VERSION ""

NS_ :

BS_:

BU_:BMS FCS VCU
BO_ 2550595703 BatP7_BMS_ChargingInfo: 8 BMS
 SG_ P7_ChrgrCplrStat : 7|1@0+ (1,0) [0|1] "" VCU
 SG_ P7_HVBattChrgSysStatus : 6|4@0+ (1,0) [0|15] "" VCU
 SG_ P7_DCChrgCrntCmd : 2|9@0+ (1,0) [0|500] "A" VCU
 SG_ P7_CC2Vlt : 9|8@0+ (0.1,0) [0|25] "V" VCU
 SG_ P7_DCRcptPosTemp : 17|9@0+ (0.5,-40) [-40|150] "C" VCU
 SG_ P7_DCRcptNegTemp : 24|9@0+ (0.5,-40) [-40|150] "C" VCU
 SG_ P7_Tm2FullChrg : 47|14@0+ (1,0) [0|65535] "min" VCU

BO_ 2550661239 BatP7_BMS_ThermalManagement: 8 BMS
 SG_ P7_Inlet1ClntTemp : 7|11@0+ (0.1,-40) [-40|150] "C" VCU
 SG_ P7_Inlet2ClntTemp : 12|11@0+ (0.1,-40) [-40|150] "C" VCU
 SG_ P7_Outlet1ClntTemp : 17|11@0+ (0.1,-40) [-40|150] "C" VCU
 SG_ P7_Outlet2ClntTemp : 38|11@0+ (0.1,-40) [-40|150] "C" VCU
 SG_ P7_TrgtClntTemp : 43|11@0+ (0.1,-40) [-40|150] "C" VCU
 SG_ P7_TrgtClntFlowRate : 48|9@0+ (0.2,0) [0|100] "C" VCU

BO_ 2550726775 BatP7_BMS_CellVoltMaxMin: 8 BMS
 SG_ P7_MaxCellVlt : 7|13@0+ (0.001,0) [0|5] "V" VCU
 SG_ P7_MaxCellVltNum : 10|9@0+ (1,0) [0|500] "" VCU
 SG_ P7_MinCellVlt : 17|13@0+ (0.001,0) [0|5] "V" VCU
 SG_ P7_MinCellVltNum : 36|9@0+ (1,0) [0|500] "" VCU
 SG_ P7_AvgCellVlt : 43|13@0+ (0.001,0) [0|5] "V" VCU

BO_ 2550792311 BatP7_BMS_CellTempMaxMin: 8 BMS
 SG_ P7_MaxCellTemp : 7|11@0+ (0.1,-40) [-40|150] "C" VCU
 SG_ P7_MaxCellTempNum : 12|9@0+ (1,0) [0|500] "" VCU
 SG_ P7_MinCellTemp : 19|11@0+ (0.1,-40) [-40|150] "C" VCU
 SG_ P7_MinCellTempNum : 24|9@0+ (1,0) [0|500] "" VCU
 SG_ P7_AvgCellTemp : 47|11@0+ (0.1,-40) [-40|150] "C" VCU

BO_ 2550857847 BatP7_BMS_PackFaultInfo1: 8 BMS
 SG_ P7_PackTotFltNum : 7|8@0+ (1,0) [0|200] "" VCU
 SG_ P7_CellOverVoltage : 15|2@0+ (1,0) [0|3] "" VCU
 SG_ P7_CellUnderVoltage : 13|2@0+ (1,0) [0|3] "" VCU
 SG_ P7_CellVoltageDiffHi : 11|1@0+ (1,0) [0|1] "" VCU
 SG_ P7_PackOverVoltage : 10|2@0+ (1,0) [0|3] "" VCU
 SG_ P7_PackUnderVoltage : 8|2@0+ (1,0) [0|3] "" VCU
 SG_ P7_CellOverTemp : 22|2@0+ (1,0) [0|3] "" VCU
 SG_ P7_CellTempLow : 20|1@0+ (1,0) [0|1] "" VCU
 SG_ P7_CellTempDiffHi : 19|1@0+ (1,0) [0|1] "" VCU
 SG_ P7_PackDschrgCrntHi : 18|2@0+ (1,0) [0|3] "" VCU
 SG_ P7_PackChrgCrntHi : 16|2@0+ (1,0) [0|3] "" VCU
 SG_ P7_PackCrnSnsr1OffsetHi : 30|1@0+ (1,0) [0|1] "" VCU
 SG_ P7_HVIsolFlt : 29|2@0+ (1,0) [0|3] "" VCU
 SG_ P7_HVILFlt : 27|1@0+ (1,0) [0|1] "" VCU
 SG_ P7_ThrmlRunaway : 26|1@0+ (1,0) [0|1] "" VCU
 SG_ P7_CellVoltInvalid : 25|1@0+ (1,0) [0|1] "" VCU
 SG_ P7_CellTempInvalid : 24|1@0+ (1,0) [0|1] "" VCU
 SG_ P7_DaisyChainComFlt : 39|1@0+ (1,0) [0|1] "" VCU
 SG_ P7_PackVoltRatFlt : 38|1@0+ (1,0) [0|1] "" VCU
 SG_ P7_CrntSnsr1Invalid : 37|1@0+ (1,0) [0|1] "" VCU
 SG_ P7_CrntSnsr1OOR : 36|1@0+ (1,0) [0|1] "" VCU
 SG_ P7_CrntSnsr2Invalid : 35|1@0+ (1,0) [0|1] "" VCU
 SG_ P7_CrntSnsr2OOR : 34|1@0+ (1,0) [0|1] "" VCU
 SG_ P7_PackCrnSnsr2OffsetHi : 33|1@0+ (1,0) [0|1] "" VCU
 SG_ P7_OutofEnergy : 32|1@0+ (1,0) [0|1] "" VCU
 SG_ P7_IsolDetCircErr : 47|1@0+ (1,0) [0|1] "" VCU
 SG_ P7_HVILCircShortToGND : 46|1@0+ (1,0) [0|1] "" VCU
 SG_ P7_HVILCircShortToPwr : 45|1@0+ (1,0) [0|1] "" VCU

BO_ 2550923383 BatP7_BMS_PackFaultInfo2: 8 BMS
 SG_ P7_MainPosCntctrStkClsd : 7|1@0+ (1,0) [0|1] "" VCU
 SG_ P7_MainPosCntctrStkOpn : 6|1@0+ (1,0) [0|1] "" VCU
 SG_ P7_MainNegCntctr1StkClsd : 5|1@0+ (1,0) [0|1] "" VCU
 SG_ P7_MainNegCntctr1StkOpn : 4|1@0+ (1,0) [0|1] "" VCU
 SG_ P7_MainNegCntctr2StkClsd : 3|1@0+ (1,0) [0|1] "" VCU
 SG_ P7_MainNegCntctr2StkOpn : 2|1@0+ (1,0) [0|1] "" VCU
 SG_ P7_PrechargTmOut : 1|1@0+ (1,0) [0|1] "" VCU
 SG_ P7_PrechrgCrntHi : 0|1@0+ (1,0) [0|1] "" VCU
 SG_ P7_ChrgCplrPosTempHi : 15|1@0+ (1,0) [0|1] "" VCU
 SG_ P7_ChrgCplrNegTempHi : 14|1@0+ (1,0) [0|1] "" VCU
 SG_ P7_BMSPwrSuplVlt1Hi : 13|1@0+ (1,0) [0|1] "" VCU
 SG_ P7_BMSPwrSuplVlt1Lo : 12|1@0+ (1,0) [0|1] "" VCU
 SG_ P7_BMSPwrSuplVlt2Hi : 11|1@0+ (1,0) [0|1] "" VCU
 SG_ P7_BMSPwrSuplVlt2Lo : 10|1@0+ (1,0) [0|1] "" VCU
 SG_ P7_CntctrCirPwrSuplVltLo : 9|1@0+ (1,0) [0|1] "" VCU
 SG_ P7_CntctrCirPwrSuplVltHi : 8|1@0+ (1,0) [0|1] "" VCU
 SG_ P7_CAN1BusOff : 23|1@0+ (1,0) [0|1] "" VCU
 SG_ P7_CAN1BusTmOut : 22|1@0+ (1,0) [0|1] "" VCU
 SG_ P7_CAN2BusOff : 21|1@0+ (1,0) [0|1] "" VCU
 SG_ P7_CAN2BusTmOut : 20|1@0+ (1,0) [0|1] "" VCU
 SG_ P7_CellBalCircTempHi : 19|1@0+ (1,0) [0|1] "" VCU
 SG_ P7_ClntInTempHi : 18|1@0+ (1,0) [0|1] "" VCU
 SG_ P7_ClntOutTempHi : 17|1@0+ (1,0) [0|1] "" VCU
 SG_ P7_CellExtrmUdrVolt : 16|1@0+ (1,0) [0|1] "" VCU
 SG_ P7_CellExtrmOvrVolt : 31|1@0+ (1,0) [0|1] "" VCU
 SG_ P7_Branch1DischrgCrntHi  : 30|1@0+ (1,0) [0|1] "" VCU
 SG_ P7_Branch2DischrgCrntHi  : 29|1@0+ (1,0) [0|1] "" VCU
 SG_ P7_Branch1ChrgCrntHi  : 28|1@0+ (1,0) [0|1] "" VCU
 SG_ P7_Branch2ChrgCrntHi  : 27|1@0+ (1,0) [0|1] "" VCU
 SG_ P7_InitFailed : 26|1@0+ (1,0) [0|1] "" VCU
 SG_ P7_PackErrCode : 25|10@0+ (1,0) [0|1023] "" VCU

BO_ 2550988919 BatP7_BMS_PackConfigInfo: 8 BMS
 SG_ P7_PackTotCellNum : 7|9@0+ (1,0) [0|500] "" VCU
 SG_ P7_PackTotCellTempSnsrNum : 14|9@0+ (1,0) [0|500] "" VCU

BO_ 2552299639 BatP7_BMS_BMSVersion: 8 BMS
 SG_ P7_BMSASWMajVerNum : 7|8@0+ (1,0) [0|9] "" VCU
 SG_ P7_BMSASWMinVerNum : 15|8@0+ (1,0) [0|99] "" VCU
 SG_ P7_BMSASWPatchVerNum : 23|8@0+ (1,0) [0|255] "" VCU
 SG_ P7_BMSBSWMajVerNum : 31|8@0+ (1,0) [0|9] "" VCU
 SG_ P7_BMSBSWMinVerNum : 39|8@0+ (1,0) [0|99] "" VCU
 SG_ P7_BMSBSWPatchVerNum : 47|8@0+ (1,0) [0|255] "" VCU

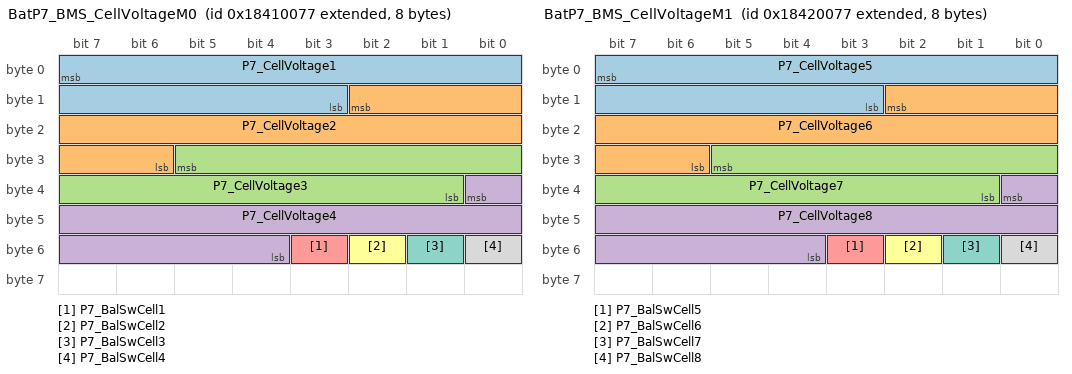
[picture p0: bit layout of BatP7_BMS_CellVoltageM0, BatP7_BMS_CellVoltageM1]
BO_ 2554396791 BatP7_BMS_CellVoltageM0: 8 BMS
 SG_ P7_CellVoltage1 : 7|13@0+ (0.001,0) [0|5] "V" VCU
 SG_ P7_CellVoltage2 : 10|13@0+ (0.001,0) [0|5] "V" VCU
 SG_ P7_CellVoltage3 : 29|13@0+ (0.001,0) [0|5] "V" VCU
 SG_ P7_CellVoltage4 : 32|13@0+ (0.001,0) [0|5] "V" VCU
 SG_ P7_BalSwCell1 : 51|1@0+ (1,0) [0|1] "" VCU
 SG_ P7_BalSwCell2 : 50|1@0+ (1,0) [0|1] "" VCU
 SG_ P7_BalSwCell3 : 49|1@0+ (1,0) [0|1] "" VCU
 SG_ P7_BalSwCell4 : 48|1@0+ (1,0) [0|1] "" VCU

BO_ 2554462327 BatP7_BMS_CellVoltageM1: 8 BMS
 SG_ P7_CellVoltage5 : 7|13@0+ (0.001,0) [0|5] "V" VCU
 SG_ P7_CellVoltage6 : 10|13@0+ (0.001,0) [0|5] "V" VCU
 SG_ P7_CellVoltage7 : 29|13@0+ (0.001,0) [0|5] "V" VCU
 SG_ P7_CellVoltage8 : 32|13@0+ (0.001,0) [0|5] "V" VCU
 SG_ P7_BalSwCell5 : 51|1@0+ (1,0) [0|1] "" VCU
 SG_ P7_BalSwCell6 : 50|1@0+ (1,0) [0|1] "" VCU
 SG_ P7_BalSwCell7 : 49|1@0+ (1,0) [0|1] "" VCU
 SG_ P7_BalSwCell8 : 48|1@0+ (1,0) [0|1] "" VCU

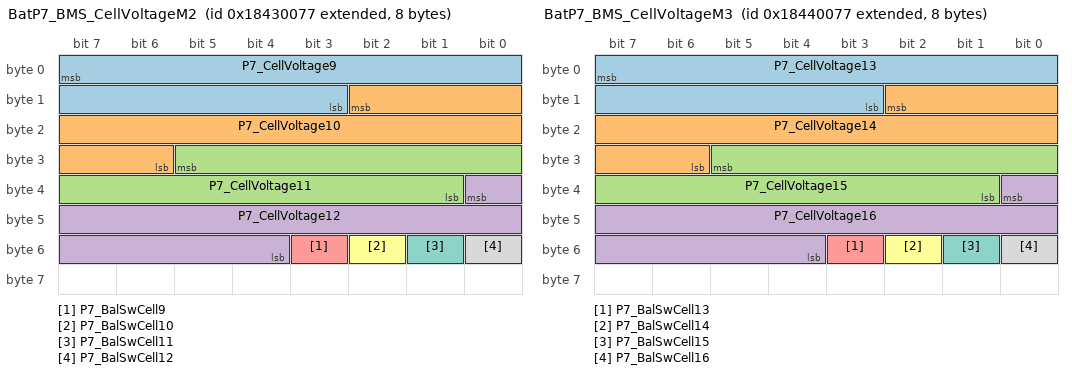
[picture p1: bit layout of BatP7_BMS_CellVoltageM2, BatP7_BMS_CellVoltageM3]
BO_ 2554527863 BatP7_BMS_CellVoltageM2: 8 BMS
 SG_ P7_CellVoltage9 : 7|13@0+ (0.001,0) [0|5] "V" VCU
 SG_ P7_CellVoltage10 : 10|13@0+ (0.001,0) [0|5] "V" VCU
 SG_ P7_CellVoltage11 : 29|13@0+ (0.001,0) [0|5] "V" VCU
 SG_ P7_CellVoltage12 : 32|13@0+ (0.001,0) [0|5] "V" VCU
 SG_ P7_BalSwCell9 : 51|1@0+ (1,0) [0|1] "" VCU
 SG_ P7_BalSwCell10 : 50|1@0+ (1,0) [0|1] "" VCU
 SG_ P7_BalSwCell11 : 49|1@0+ (1,0) [0|1] "" VCU
 SG_ P7_BalSwCell12 : 48|1@0+ (1,0) [0|1] "" VCU

BO_ 2554593399 BatP7_BMS_CellVoltageM3: 8 BMS
 SG_ P7_CellVoltage13 : 7|13@0+ (0.001,0) [0|5] "V" VCU
 SG_ P7_CellVoltage14 : 10|13@0+ (0.001,0) [0|5] "V" VCU
 SG_ P7_CellVoltage15 : 29|13@0+ (0.001,0) [0|5] "V" VCU
 SG_ P7_CellVoltage16 : 32|13@0+ (0.001,0) [0|5] "V" VCU
 SG_ P7_BalSwCell13 : 51|1@0+ (1,0) [0|1] "" VCU
 SG_ P7_BalSwCell14 : 50|1@0+ (1,0) [0|1] "" VCU
 SG_ P7_BalSwCell15 : 49|1@0+ (1,0) [0|1] "" VCU
 SG_ P7_BalSwCell16 : 48|1@0+ (1,0) [0|1] "" VCU

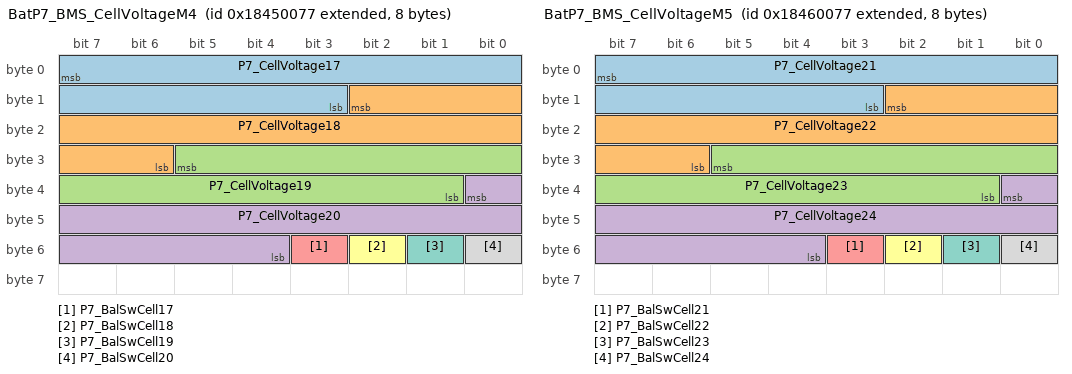
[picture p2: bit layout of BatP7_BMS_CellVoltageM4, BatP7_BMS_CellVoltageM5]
BO_ 2554658935 BatP7_BMS_CellVoltageM4: 8 BMS
 SG_ P7_CellVoltage17 : 7|13@0+ (0.001,0) [0|5] "V" VCU
 SG_ P7_CellVoltage18 : 10|13@0+ (0.001,0) [0|5] "V" VCU
 SG_ P7_CellVoltage19 : 29|13@0+ (0.001,0) [0|5] "V" VCU
 SG_ P7_CellVoltage20 : 32|13@0+ (0.001,0) [0|5] "V" VCU
 SG_ P7_BalSwCell17 : 51|1@0+ (1,0) [0|1] "" VCU
 SG_ P7_BalSwCell18 : 50|1@0+ (1,0) [0|1] "" VCU
 SG_ P7_BalSwCell19 : 49|1@0+ (1,0) [0|1] "" VCU
 SG_ P7_BalSwCell20 : 48|1@0+ (1,0) [0|1] "" VCU

BO_ 2554724471 BatP7_BMS_CellVoltageM5: 8 BMS
 SG_ P7_CellVoltage21 : 7|13@0+ (0.001,0) [0|5] "V" VCU
 SG_ P7_CellVoltage22 : 10|13@0+ (0.001,0) [0|5] "V" VCU
 SG_ P7_CellVoltage23 : 29|13@0+ (0.001,0) [0|5] "V" VCU
 SG_ P7_CellVoltage24 : 32|13@0+ (0.001,0) [0|5] "V" VCU
 SG_ P7_BalSwCell21 : 51|1@0+ (1,0) [0|1] "" VCU
 SG_ P7_BalSwCell22 : 50|1@0+ (1,0) [0|1] "" VCU
 SG_ P7_BalSwCell23 : 49|1@0+ (1,0) [0|1] "" VCU
 SG_ P7_BalSwCell24 : 48|1@0+ (1,0) [0|1] "" VCU

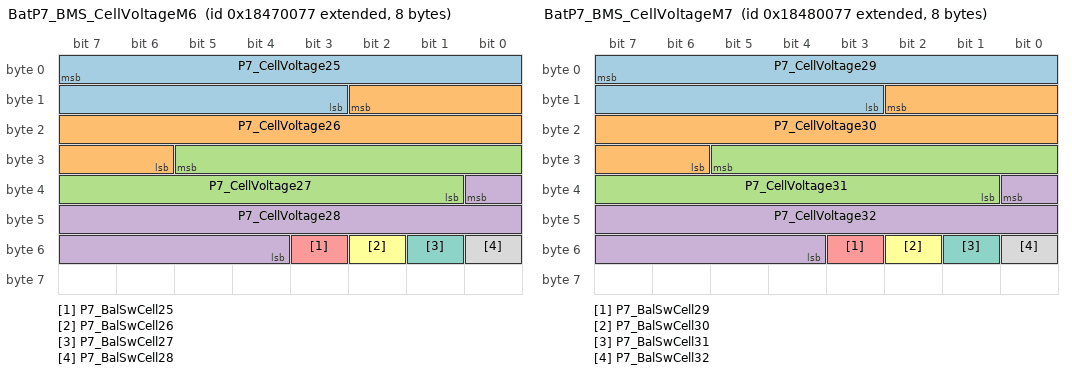
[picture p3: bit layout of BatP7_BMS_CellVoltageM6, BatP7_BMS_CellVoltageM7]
BO_ 2554790007 BatP7_BMS_CellVoltageM6: 8 BMS
 SG_ P7_CellVoltage25 : 7|13@0+ (0.001,0) [0|5] "V" VCU
 SG_ P7_CellVoltage26 : 10|13@0+ (0.001,0) [0|5] "V" VCU
 SG_ P7_CellVoltage27 : 29|13@0+ (0.001,0) [0|5] "V" VCU
 SG_ P7_CellVoltage28 : 32|13@0+ (0.001,0) [0|5] "V" VCU
 SG_ P7_BalSwCell25 : 51|1@0+ (1,0) [0|1] "" VCU
 SG_ P7_BalSwCell26 : 50|1@0+ (1,0) [0|1] "" VCU
 SG_ P7_BalSwCell27 : 49|1@0+ (1,0) [0|1] "" VCU
 SG_ P7_BalSwCell28 : 48|1@0+ (1,0) [0|1] "" VCU

BO_ 2554855543 BatP7_BMS_CellVoltageM7: 8 BMS
 SG_ P7_CellVoltage29 : 7|13@0+ (0.001,0) [0|5] "V" VCU
 SG_ P7_CellVoltage30 : 10|13@0+ (0.001,0) [0|5] "V" VCU
 SG_ P7_CellVoltage31 : 29|13@0+ (0.001,0) [0|5] "V" VCU
 SG_ P7_CellVoltage32 : 32|13@0+ (0.001,0) [0|5] "V" VCU
 SG_ P7_BalSwCell29 : 51|1@0+ (1,0) [0|1] "" VCU
 SG_ P7_BalSwCell30 : 50|1@0+ (1,0) [0|1] "" VCU
 SG_ P7_BalSwCell31 : 49|1@0+ (1,0) [0|1] "" VCU
 SG_ P7_BalSwCell32 : 48|1@0+ (1,0) [0|1] "" VCU

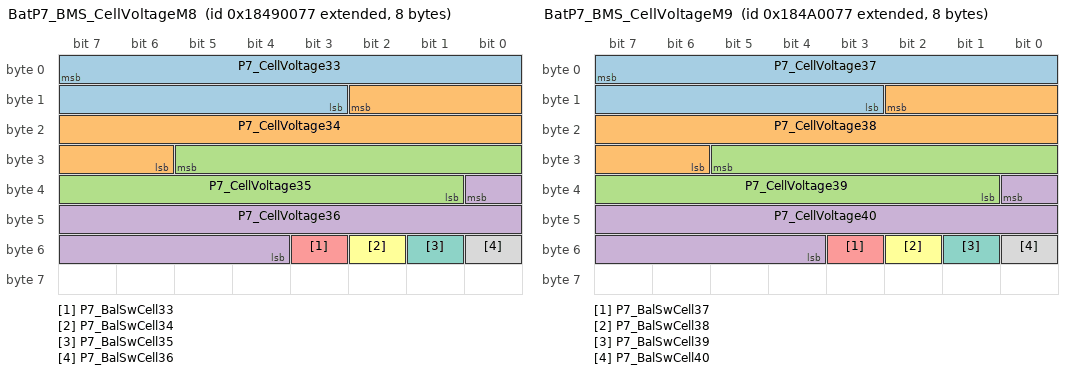
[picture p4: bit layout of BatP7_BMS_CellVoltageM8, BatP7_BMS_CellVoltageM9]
BO_ 2554921079 BatP7_BMS_CellVoltageM8: 8 BMS
 SG_ P7_CellVoltage33 : 7|13@0+ (0.001,0) [0|5] "V" VCU
 SG_ P7_CellVoltage34 : 10|13@0+ (0.001,0) [0|5] "V" VCU
 SG_ P7_CellVoltage35 : 29|13@0+ (0.001,0) [0|5] "V" VCU
 SG_ P7_CellVoltage36 : 32|13@0+ (0.001,0) [0|5] "V" VCU
 SG_ P7_BalSwCell33 : 51|1@0+ (1,0) [0|1] "" VCU
 SG_ P7_BalSwCell34 : 50|1@0+ (1,0) [0|1] "" VCU
 SG_ P7_BalSwCell35 : 49|1@0+ (1,0) [0|1] "" VCU
 SG_ P7_BalSwCell36 : 48|1@0+ (1,0) [0|1] "" VCU

BO_ 2554986615 BatP7_BMS_CellVoltageM9: 8 BMS
 SG_ P7_CellVoltage37 : 7|13@0+ (0.001,0) [0|5] "V" VCU
 SG_ P7_CellVoltage38 : 10|13@0+ (0.001,0) [0|5] "V" VCU
 SG_ P7_CellVoltage39 : 29|13@0+ (0.001,0) [0|5] "V" VCU
 SG_ P7_CellVoltage40 : 32|13@0+ (0.001,0) [0|5] "V" VCU
 SG_ P7_BalSwCell37 : 51|1@0+ (1,0) [0|1] "" VCU
 SG_ P7_BalSwCell38 : 50|1@0+ (1,0) [0|1] "" VCU
 SG_ P7_BalSwCell39 : 49|1@0+ (1,0) [0|1] "" VCU
 SG_ P7_BalSwCell40 : 48|1@0+ (1,0) [0|1] "" VCU

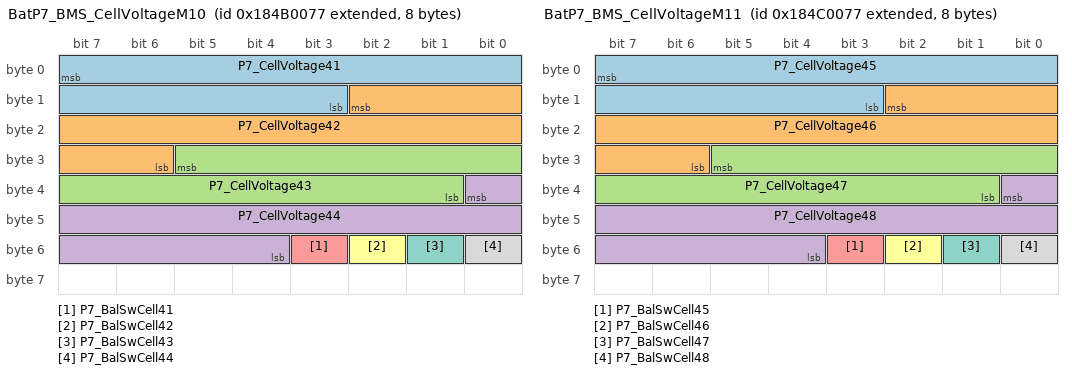
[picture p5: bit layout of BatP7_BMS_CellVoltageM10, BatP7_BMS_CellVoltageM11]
BO_ 2555052151 BatP7_BMS_CellVoltageM10: 8 BMS
 SG_ P7_CellVoltage41 : 7|13@0+ (0.001,0) [0|5] "V" VCU
 SG_ P7_CellVoltage42 : 10|13@0+ (0.001,0) [0|5] "V" VCU
 SG_ P7_CellVoltage43 : 29|13@0+ (0.001,0) [0|5] "V" VCU
 SG_ P7_CellVoltage44 : 32|13@0+ (0.001,0) [0|5] "V" VCU
 SG_ P7_BalSwCell41 : 51|1@0+ (1,0) [0|1] "" VCU
 SG_ P7_BalSwCell42 : 50|1@0+ (1,0) [0|1] "" VCU
 SG_ P7_BalSwCell43 : 49|1@0+ (1,0) [0|1] "" VCU
 SG_ P7_BalSwCell44 : 48|1@0+ (1,0) [0|1] "" VCU

BO_ 2555117687 BatP7_BMS_CellVoltageM11: 8 BMS
 SG_ P7_CellVoltage45 : 7|13@0+ (0.001,0) [0|5] "V" VCU
 SG_ P7_CellVoltage46 : 10|13@0+ (0.001,0) [0|5] "V" VCU
 SG_ P7_CellVoltage47 : 29|13@0+ (0.001,0) [0|5] "V" VCU
 SG_ P7_CellVoltage48 : 32|13@0+ (0.001,0) [0|5] "V" VCU
 SG_ P7_BalSwCell45 : 51|1@0+ (1,0) [0|1] "" VCU
 SG_ P7_BalSwCell46 : 50|1@0+ (1,0) [0|1] "" VCU
 SG_ P7_BalSwCell47 : 49|1@0+ (1,0) [0|1] "" VCU
 SG_ P7_BalSwCell48 : 48|1@0+ (1,0) [0|1] "" VCU

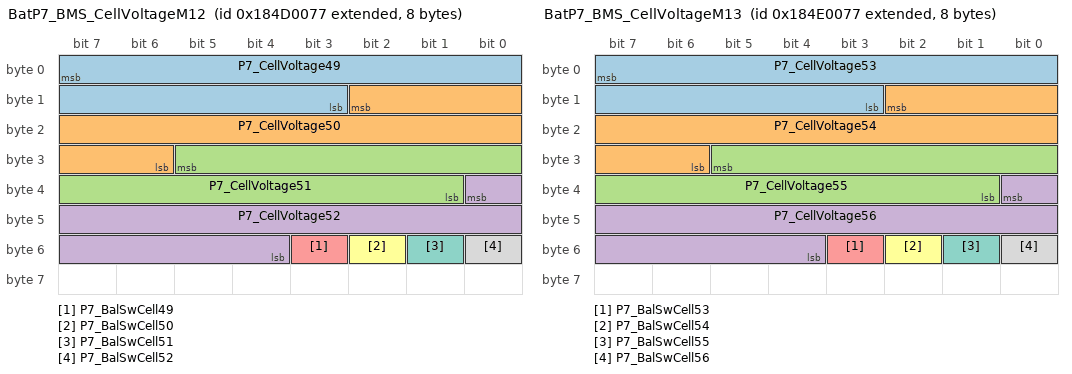
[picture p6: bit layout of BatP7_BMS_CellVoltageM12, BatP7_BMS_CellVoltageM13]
BO_ 2555183223 BatP7_BMS_CellVoltageM12: 8 BMS
 SG_ P7_CellVoltage49 : 7|13@0+ (0.001,0) [0|5] "V" VCU
 SG_ P7_CellVoltage50 : 10|13@0+ (0.001,0) [0|5] "V" VCU
 SG_ P7_CellVoltage51 : 29|13@0+ (0.001,0) [0|5] "V" VCU
 SG_ P7_CellVoltage52 : 32|13@0+ (0.001,0) [0|5] "V" VCU
 SG_ P7_BalSwCell49 : 51|1@0+ (1,0) [0|1] "" VCU
 SG_ P7_BalSwCell50 : 50|1@0+ (1,0) [0|1] "" VCU
 SG_ P7_BalSwCell51 : 49|1@0+ (1,0) [0|1] "" VCU
 SG_ P7_BalSwCell52 : 48|1@0+ (1,0) [0|1] "" VCU

BO_ 2555248759 BatP7_BMS_CellVoltageM13: 8 BMS
 SG_ P7_CellVoltage53 : 7|13@0+ (0.001,0) [0|5] "V" VCU
 SG_ P7_CellVoltage54 : 10|13@0+ (0.001,0) [0|5] "V" VCU
 SG_ P7_CellVoltage55 : 29|13@0+ (0.001,0) [0|5] "V" VCU
 SG_ P7_CellVoltage56 : 32|13@0+ (0.001,0) [0|5] "V" VCU
 SG_ P7_BalSwCell53 : 51|1@0+ (1,0) [0|1] "" VCU
 SG_ P7_BalSwCell54 : 50|1@0+ (1,0) [0|1] "" VCU
 SG_ P7_BalSwCell55 : 49|1@0+ (1,0) [0|1] "" VCU
 SG_ P7_BalSwCell56 : 48|1@0+ (1,0) [0|1] "" VCU

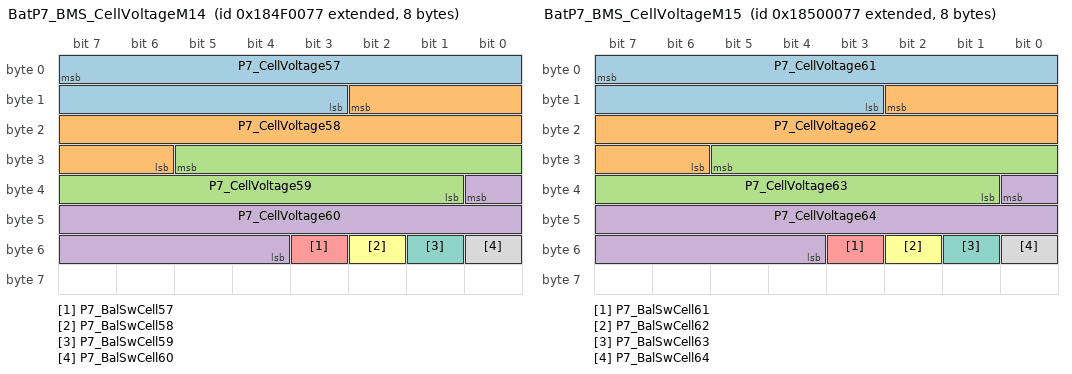
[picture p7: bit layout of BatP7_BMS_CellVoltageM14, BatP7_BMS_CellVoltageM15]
BO_ 2555314295 BatP7_BMS_CellVoltageM14: 8 BMS
 SG_ P7_CellVoltage57 : 7|13@0+ (0.001,0) [0|5] "V" VCU
 SG_ P7_CellVoltage58 : 10|13@0+ (0.001,0) [0|5] "V" VCU
 SG_ P7_CellVoltage59 : 29|13@0+ (0.001,0) [0|5] "V" VCU
 SG_ P7_CellVoltage60 : 32|13@0+ (0.001,0) [0|5] "V" VCU
 SG_ P7_BalSwCell57 : 51|1@0+ (1,0) [0|1] "" VCU
 SG_ P7_BalSwCell58 : 50|1@0+ (1,0) [0|1] "" VCU
 SG_ P7_BalSwCell59 : 49|1@0+ (1,0) [0|1] "" VCU
 SG_ P7_BalSwCell60 : 48|1@0+ (1,0) [0|1] "" VCU

BO_ 2555379831 BatP7_BMS_CellVoltageM15: 8 BMS
 SG_ P7_CellVoltage61 : 7|13@0+ (0.001,0) [0|5] "V" VCU
 SG_ P7_CellVoltage62 : 10|13@0+ (0.001,0) [0|5] "V" VCU
 SG_ P7_CellVoltage63 : 29|13@0+ (0.001,0) [0|5] "V" VCU
 SG_ P7_CellVoltage64 : 32|13@0+ (0.001,0) [0|5] "V" VCU
 SG_ P7_BalSwCell61 : 51|1@0+ (1,0) [0|1] "" VCU
 SG_ P7_BalSwCell62 : 50|1@0+ (1,0) [0|1] "" VCU
 SG_ P7_BalSwCell63 : 49|1@0+ (1,0) [0|1] "" VCU
 SG_ P7_BalSwCell64 : 48|1@0+ (1,0) [0|1] "" VCU

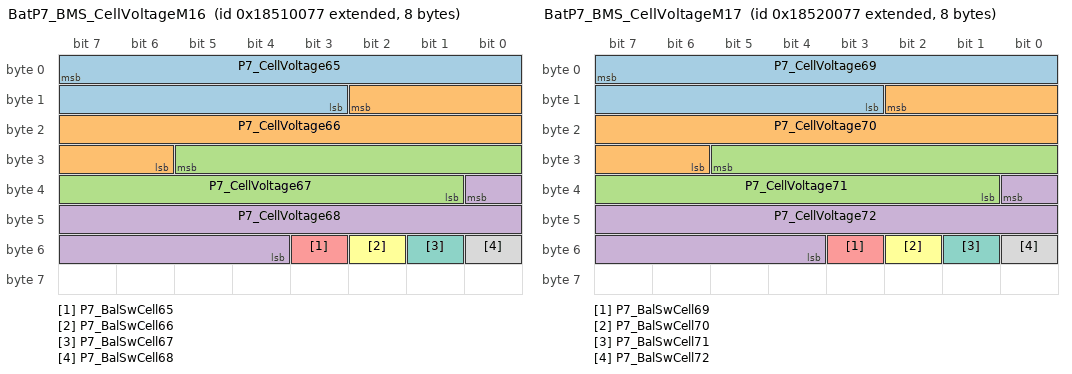
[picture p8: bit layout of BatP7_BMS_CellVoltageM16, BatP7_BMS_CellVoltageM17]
BO_ 2555445367 BatP7_BMS_CellVoltageM16: 8 BMS
 SG_ P7_CellVoltage65 : 7|13@0+ (0.001,0) [0|5] "V" VCU
 SG_ P7_CellVoltage66 : 10|13@0+ (0.001,0) [0|5] "V" VCU
 SG_ P7_CellVoltage67 : 29|13@0+ (0.001,0) [0|5] "V" VCU
 SG_ P7_CellVoltage68 : 32|13@0+ (0.001,0) [0|5] "V" VCU
 SG_ P7_BalSwCell65 : 51|1@0+ (1,0) [0|1] "" VCU
 SG_ P7_BalSwCell66 : 50|1@0+ (1,0) [0|1] "" VCU
 SG_ P7_BalSwCell67 : 49|1@0+ (1,0) [0|1] "" VCU
 SG_ P7_BalSwCell68 : 48|1@0+ (1,0) [0|1] "" VCU

BO_ 2555510903 BatP7_BMS_CellVoltageM17: 8 BMS
 SG_ P7_CellVoltage69 : 7|13@0+ (0.001,0) [0|5] "V" VCU
 SG_ P7_CellVoltage70 : 10|13@0+ (0.001,0) [0|5] "V" VCU
 SG_ P7_CellVoltage71 : 29|13@0+ (0.001,0) [0|5] "V" VCU
 SG_ P7_CellVoltage72 : 32|13@0+ (0.001,0) [0|5] "V" VCU
 SG_ P7_BalSwCell69 : 51|1@0+ (1,0) [0|1] "" VCU
 SG_ P7_BalSwCell70 : 50|1@0+ (1,0) [0|1] "" VCU
 SG_ P7_BalSwCell71 : 49|1@0+ (1,0) [0|1] "" VCU
 SG_ P7_BalSwCell72 : 48|1@0+ (1,0) [0|1] "" VCU

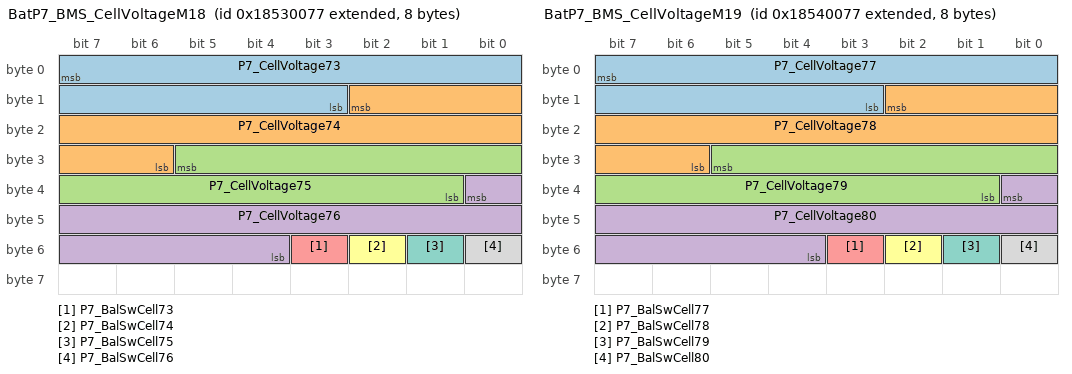
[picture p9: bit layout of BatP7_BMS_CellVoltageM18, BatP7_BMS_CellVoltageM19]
BO_ 2555576439 BatP7_BMS_CellVoltageM18: 8 BMS
 SG_ P7_CellVoltage73 : 7|13@0+ (0.001,0) [0|5] "V" VCU
 SG_ P7_CellVoltage74 : 10|13@0+ (0.001,0) [0|5] "V" VCU
 SG_ P7_CellVoltage75 : 29|13@0+ (0.001,0) [0|5] "V" VCU
 SG_ P7_CellVoltage76 : 32|13@0+ (0.001,0) [0|5] "V" VCU
 SG_ P7_BalSwCell73 : 51|1@0+ (1,0) [0|1] "" VCU
 SG_ P7_BalSwCell74 : 50|1@0+ (1,0) [0|1] "" VCU
 SG_ P7_BalSwCell75 : 49|1@0+ (1,0) [0|1] "" VCU
 SG_ P7_BalSwCell76 : 48|1@0+ (1,0) [0|1] "" VCU

BO_ 2555641975 BatP7_BMS_CellVoltageM19: 8 BMS
 SG_ P7_CellVoltage77 : 7|13@0+ (0.001,0) [0|5] "V" VCU
 SG_ P7_CellVoltage78 : 10|13@0+ (0.001,0) [0|5] "V" VCU
 SG_ P7_CellVoltage79 : 29|13@0+ (0.001,0) [0|5] "V" VCU
 SG_ P7_CellVoltage80 : 32|13@0+ (0.001,0) [0|5] "V" VCU
 SG_ P7_BalSwCell77 : 51|1@0+ (1,0) [0|1] "" VCU
 SG_ P7_BalSwCell78 : 50|1@0+ (1,0) [0|1] "" VCU
 SG_ P7_BalSwCell79 : 49|1@0+ (1,0) [0|1] "" VCU
 SG_ P7_BalSwCell80 : 48|1@0+ (1,0) [0|1] "" VCU

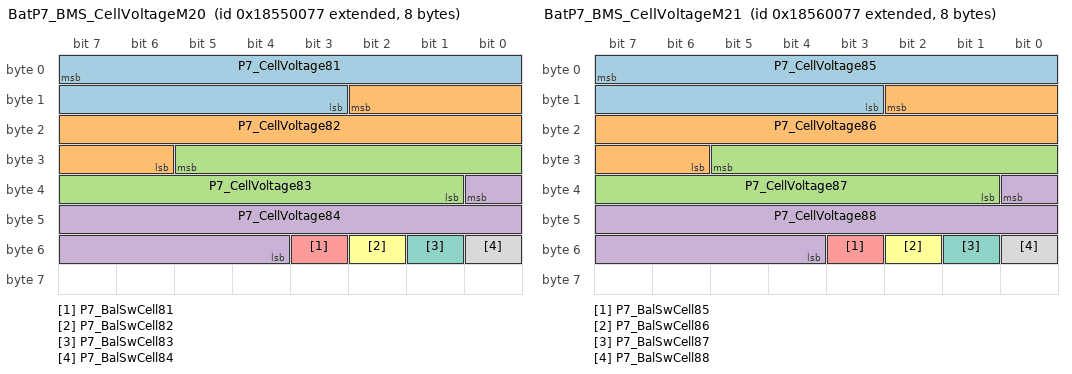
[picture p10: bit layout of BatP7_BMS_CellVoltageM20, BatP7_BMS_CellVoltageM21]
BO_ 2555707511 BatP7_BMS_CellVoltageM20: 8 BMS
 SG_ P7_CellVoltage81 : 7|13@0+ (0.001,0) [0|5] "V" VCU
 SG_ P7_CellVoltage82 : 10|13@0+ (0.001,0) [0|5] "V" VCU
 SG_ P7_CellVoltage83 : 29|13@0+ (0.001,0) [0|5] "V" VCU
 SG_ P7_CellVoltage84 : 32|13@0+ (0.001,0) [0|5] "V" VCU
 SG_ P7_BalSwCell81 : 51|1@0+ (1,0) [0|1] "" VCU
 SG_ P7_BalSwCell82 : 50|1@0+ (1,0) [0|1] "" VCU
 SG_ P7_BalSwCell83 : 49|1@0+ (1,0) [0|1] "" VCU
 SG_ P7_BalSwCell84 : 48|1@0+ (1,0) [0|1] "" VCU

BO_ 2555773047 BatP7_BMS_CellVoltageM21: 8 BMS
 SG_ P7_CellVoltage85 : 7|13@0+ (0.001,0) [0|5] "V" VCU
 SG_ P7_CellVoltage86 : 10|13@0+ (0.001,0) [0|5] "V" VCU
 SG_ P7_CellVoltage87 : 29|13@0+ (0.001,0) [0|5] "V" VCU
 SG_ P7_CellVoltage88 : 32|13@0+ (0.001,0) [0|5] "V" VCU
 SG_ P7_BalSwCell85 : 51|1@0+ (1,0) [0|1] "" VCU
 SG_ P7_BalSwCell86 : 50|1@0+ (1,0) [0|1] "" VCU
 SG_ P7_BalSwCell87 : 49|1@0+ (1,0) [0|1] "" VCU
 SG_ P7_BalSwCell88 : 48|1@0+ (1,0) [0|1] "" VCU

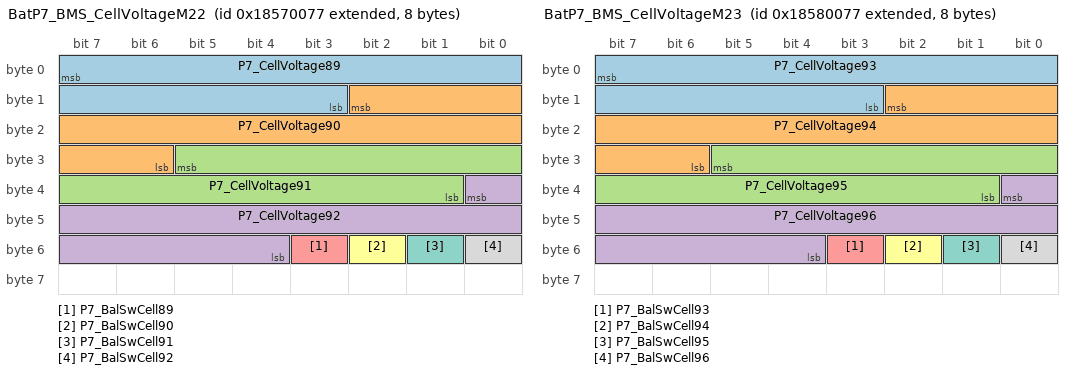
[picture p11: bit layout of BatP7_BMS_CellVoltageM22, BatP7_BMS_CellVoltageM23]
BO_ 2555838583 BatP7_BMS_CellVoltageM22: 8 BMS
 SG_ P7_CellVoltage89 : 7|13@0+ (0.001,0) [0|5] "V" VCU
 SG_ P7_CellVoltage90 : 10|13@0+ (0.001,0) [0|5] "V" VCU
 SG_ P7_CellVoltage91 : 29|13@0+ (0.001,0) [0|5] "V" VCU
 SG_ P7_CellVoltage92 : 32|13@0+ (0.001,0) [0|5] "V" VCU
 SG_ P7_BalSwCell89 : 51|1@0+ (1,0) [0|1] "" VCU
 SG_ P7_BalSwCell90 : 50|1@0+ (1,0) [0|1] "" VCU
 SG_ P7_BalSwCell91 : 49|1@0+ (1,0) [0|1] "" VCU
 SG_ P7_BalSwCell92 : 48|1@0+ (1,0) [0|1] "" VCU

BO_ 2555904119 BatP7_BMS_CellVoltageM23: 8 BMS
 SG_ P7_CellVoltage93 : 7|13@0+ (0.001,0) [0|5] "V" VCU
 SG_ P7_CellVoltage94 : 10|13@0+ (0.001,0) [0|5] "V" VCU
 SG_ P7_CellVoltage95 : 29|13@0+ (0.001,0) [0|5] "V" VCU
 SG_ P7_CellVoltage96 : 32|13@0+ (0.001,0) [0|5] "V" VCU
 SG_ P7_BalSwCell93 : 51|1@0+ (1,0) [0|1] "" VCU
 SG_ P7_BalSwCell94 : 50|1@0+ (1,0) [0|1] "" VCU
 SG_ P7_BalSwCell95 : 49|1@0+ (1,0) [0|1] "" VCU
 SG_ P7_BalSwCell96 : 48|1@0+ (1,0) [0|1] "" VCU

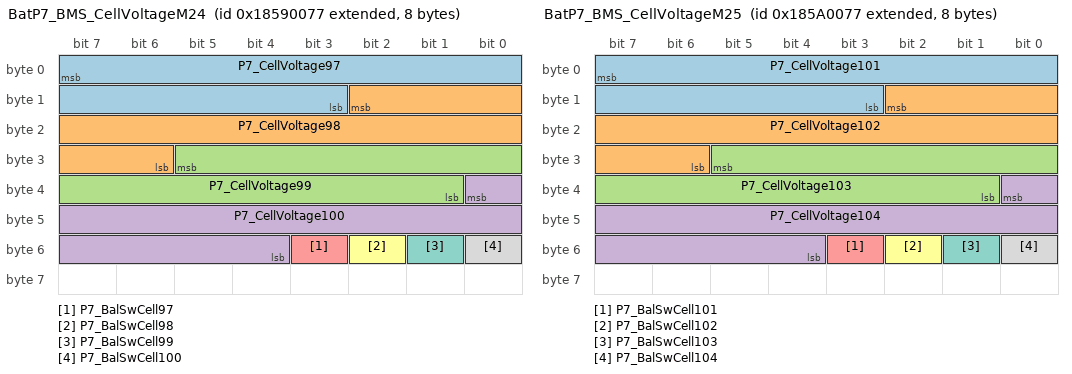
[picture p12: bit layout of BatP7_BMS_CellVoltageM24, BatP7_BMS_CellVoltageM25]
BO_ 2555969655 BatP7_BMS_CellVoltageM24: 8 BMS
 SG_ P7_CellVoltage97 : 7|13@0+ (0.001,0) [0|5] "V" VCU
 SG_ P7_CellVoltage98 : 10|13@0+ (0.001,0) [0|5] "V" VCU
 SG_ P7_CellVoltage99 : 29|13@0+ (0.001,0) [0|5] "V" VCU
 SG_ P7_CellVoltage100 : 32|13@0+ (0.001,0) [0|5] "V" VCU
 SG_ P7_BalSwCell97 : 51|1@0+ (1,0) [0|1] "" VCU
 SG_ P7_BalSwCell98 : 50|1@0+ (1,0) [0|1] "" VCU
 SG_ P7_BalSwCell99 : 49|1@0+ (1,0) [0|1] "" VCU
 SG_ P7_BalSwCell100 : 48|1@0+ (1,0) [0|1] "" VCU

BO_ 2556035191 BatP7_BMS_CellVoltageM25: 8 BMS
 SG_ P7_CellVoltage101 : 7|13@0+ (0.001,0) [0|5] "V" VCU
 SG_ P7_CellVoltage102 : 10|13@0+ (0.001,0) [0|5] "V" VCU
 SG_ P7_CellVoltage103 : 29|13@0+ (0.001,0) [0|5] "V" VCU
 SG_ P7_CellVoltage104 : 32|13@0+ (0.001,0) [0|5] "V" VCU
 SG_ P7_BalSwCell101 : 51|1@0+ (1,0) [0|1] "" VCU
 SG_ P7_BalSwCell102 : 50|1@0+ (1,0) [0|1] "" VCU
 SG_ P7_BalSwCell103 : 49|1@0+ (1,0) [0|1] "" VCU
 SG_ P7_BalSwCell104 : 48|1@0+ (1,0) [0|1] "" VCU

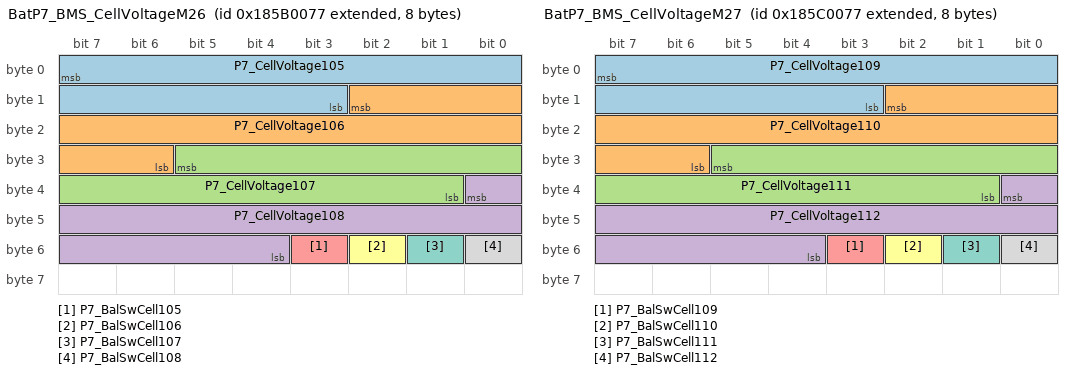
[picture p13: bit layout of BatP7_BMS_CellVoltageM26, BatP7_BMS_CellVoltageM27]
BO_ 2556100727 BatP7_BMS_CellVoltageM26: 8 BMS
 SG_ P7_CellVoltage105 : 7|13@0+ (0.001,0) [0|5] "V" VCU
 SG_ P7_CellVoltage106 : 10|13@0+ (0.001,0) [0|5] "V" VCU
 SG_ P7_CellVoltage107 : 29|13@0+ (0.001,0) [0|5] "V" VCU
 SG_ P7_CellVoltage108 : 32|13@0+ (0.001,0) [0|5] "V" VCU
 SG_ P7_BalSwCell105 : 51|1@0+ (1,0) [0|1] "" VCU
 SG_ P7_BalSwCell106 : 50|1@0+ (1,0) [0|1] "" VCU
 SG_ P7_BalSwCell107 : 49|1@0+ (1,0) [0|1] "" VCU
 SG_ P7_BalSwCell108 : 48|1@0+ (1,0) [0|1] "" VCU

BO_ 2556166263 BatP7_BMS_CellVoltageM27: 8 BMS
 SG_ P7_CellVoltage109 : 7|13@0+ (0.001,0) [0|5] "V" VCU
 SG_ P7_CellVoltage110 : 10|13@0+ (0.001,0) [0|5] "V" VCU
 SG_ P7_CellVoltage111 : 29|13@0+ (0.001,0) [0|5] "V" VCU
 SG_ P7_CellVoltage112 : 32|13@0+ (0.001,0) [0|5] "V" VCU
 SG_ P7_BalSwCell109 : 51|1@0+ (1,0) [0|1] "" VCU
 SG_ P7_BalSwCell110 : 50|1@0+ (1,0) [0|1] "" VCU
 SG_ P7_BalSwCell111 : 49|1@0+ (1,0) [0|1] "" VCU
 SG_ P7_BalSwCell112 : 48|1@0+ (1,0) [0|1] "" VCU

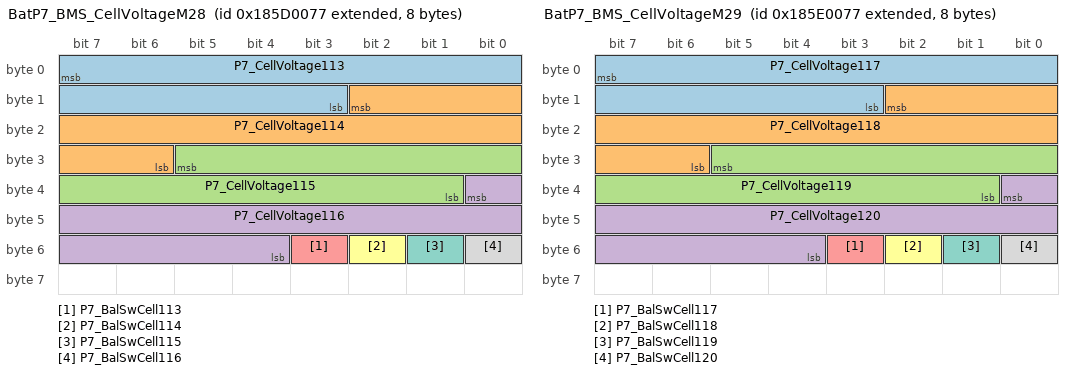
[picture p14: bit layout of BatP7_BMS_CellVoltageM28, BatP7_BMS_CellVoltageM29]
BO_ 2556231799 BatP7_BMS_CellVoltageM28: 8 BMS
 SG_ P7_CellVoltage113 : 7|13@0+ (0.001,0) [0|5] "V" VCU
 SG_ P7_CellVoltage114 : 10|13@0+ (0.001,0) [0|5] "V" VCU
 SG_ P7_CellVoltage115 : 29|13@0+ (0.001,0) [0|5] "V" VCU
 SG_ P7_CellVoltage116 : 32|13@0+ (0.001,0) [0|5] "V" VCU
 SG_ P7_BalSwCell113 : 51|1@0+ (1,0) [0|1] "" VCU
 SG_ P7_BalSwCell114 : 50|1@0+ (1,0) [0|1] "" VCU
 SG_ P7_BalSwCell115 : 49|1@0+ (1,0) [0|1] "" VCU
 SG_ P7_BalSwCell116 : 48|1@0+ (1,0) [0|1] "" VCU

BO_ 2556297335 BatP7_BMS_CellVoltageM29: 8 BMS
 SG_ P7_CellVoltage117 : 7|13@0+ (0.001,0) [0|5] "V" VCU
 SG_ P7_CellVoltage118 : 10|13@0+ (0.001,0) [0|5] "V" VCU
 SG_ P7_CellVoltage119 : 29|13@0+ (0.001,0) [0|5] "V" VCU
 SG_ P7_CellVoltage120 : 32|13@0+ (0.001,0) [0|5] "V" VCU
 SG_ P7_BalSwCell117 : 51|1@0+ (1,0) [0|1] "" VCU
 SG_ P7_BalSwCell118 : 50|1@0+ (1,0) [0|1] "" VCU
 SG_ P7_BalSwCell119 : 49|1@0+ (1,0) [0|1] "" VCU
 SG_ P7_BalSwCell120 : 48|1@0+ (1,0) [0|1] "" VCU

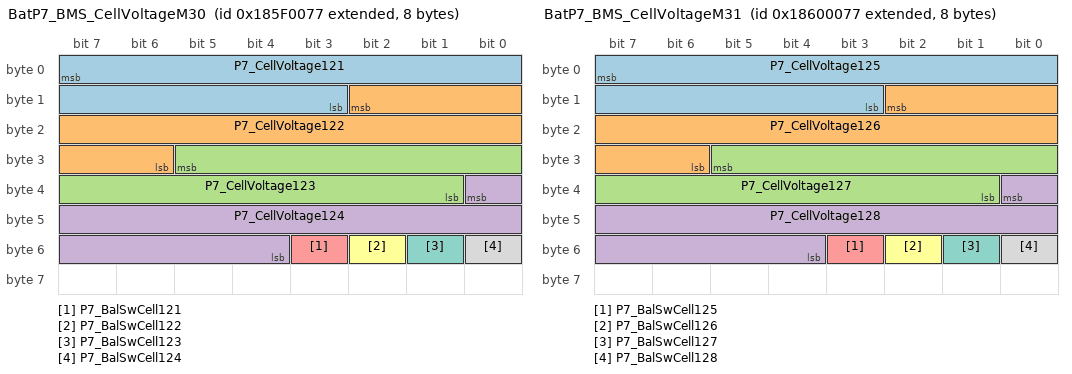
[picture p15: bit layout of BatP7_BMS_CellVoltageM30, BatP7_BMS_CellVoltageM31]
BO_ 2556362871 BatP7_BMS_CellVoltageM30: 8 BMS
 SG_ P7_CellVoltage121 : 7|13@0+ (0.001,0) [0|5] "V" VCU
 SG_ P7_CellVoltage122 : 10|13@0+ (0.001,0) [0|5] "V" VCU
 SG_ P7_CellVoltage123 : 29|13@0+ (0.001,0) [0|5] "V" VCU
 SG_ P7_CellVoltage124 : 32|13@0+ (0.001,0) [0|5] "V" VCU
 SG_ P7_BalSwCell121 : 51|1@0+ (1,0) [0|1] "" VCU
 SG_ P7_BalSwCell122 : 50|1@0+ (1,0) [0|1] "" VCU
 SG_ P7_BalSwCell123 : 49|1@0+ (1,0) [0|1] "" VCU
 SG_ P7_BalSwCell124 : 48|1@0+ (1,0) [0|1] "" VCU

BO_ 2556428407 BatP7_BMS_CellVoltageM31: 8 BMS
 SG_ P7_CellVoltage125 : 7|13@0+ (0.001,0) [0|5] "V" VCU
 SG_ P7_CellVoltage126 : 10|13@0+ (0.001,0) [0|5] "V" VCU
 SG_ P7_CellVoltage127 : 29|13@0+ (0.001,0) [0|5] "V" VCU
 SG_ P7_CellVoltage128 : 32|13@0+ (0.001,0) [0|5] "V" VCU
 SG_ P7_BalSwCell125 : 51|1@0+ (1,0) [0|1] "" VCU
 SG_ P7_BalSwCell126 : 50|1@0+ (1,0) [0|1] "" VCU
 SG_ P7_BalSwCell127 : 49|1@0+ (1,0) [0|1] "" VCU
 SG_ P7_BalSwCell128 : 48|1@0+ (1,0) [0|1] "" VCU

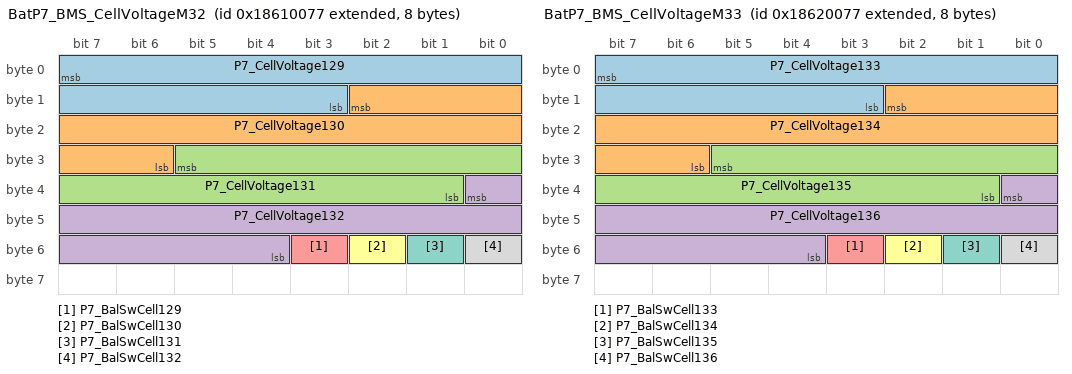
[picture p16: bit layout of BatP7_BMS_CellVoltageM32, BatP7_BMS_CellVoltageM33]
BO_ 2556493943 BatP7_BMS_CellVoltageM32: 8 BMS
 SG_ P7_CellVoltage129 : 7|13@0+ (0.001,0) [0|5] "V" VCU
 SG_ P7_CellVoltage130 : 10|13@0+ (0.001,0) [0|5] "V" VCU
 SG_ P7_CellVoltage131 : 29|13@0+ (0.001,0) [0|5] "V" VCU
 SG_ P7_CellVoltage132 : 32|13@0+ (0.001,0) [0|5] "V" VCU
 SG_ P7_BalSwCell129 : 51|1@0+ (1,0) [0|1] "" VCU
 SG_ P7_BalSwCell130 : 50|1@0+ (1,0) [0|1] "" VCU
 SG_ P7_BalSwCell131 : 49|1@0+ (1,0) [0|1] "" VCU
 SG_ P7_BalSwCell132 : 48|1@0+ (1,0) [0|1] "" VCU

BO_ 2556559479 BatP7_BMS_CellVoltageM33: 8 BMS
 SG_ P7_CellVoltage133 : 7|13@0+ (0.001,0) [0|5] "V" VCU
 SG_ P7_CellVoltage134 : 10|13@0+ (0.001,0) [0|5] "V" VCU
 SG_ P7_CellVoltage135 : 29|13@0+ (0.001,0) [0|5] "V" VCU
 SG_ P7_CellVoltage136 : 32|13@0+ (0.001,0) [0|5] "V" VCU
 SG_ P7_BalSwCell133 : 51|1@0+ (1,0) [0|1] "" VCU
 SG_ P7_BalSwCell134 : 50|1@0+ (1,0) [0|1] "" VCU
 SG_ P7_BalSwCell135 : 49|1@0+ (1,0) [0|1] "" VCU
 SG_ P7_BalSwCell136 : 48|1@0+ (1,0) [0|1] "" VCU

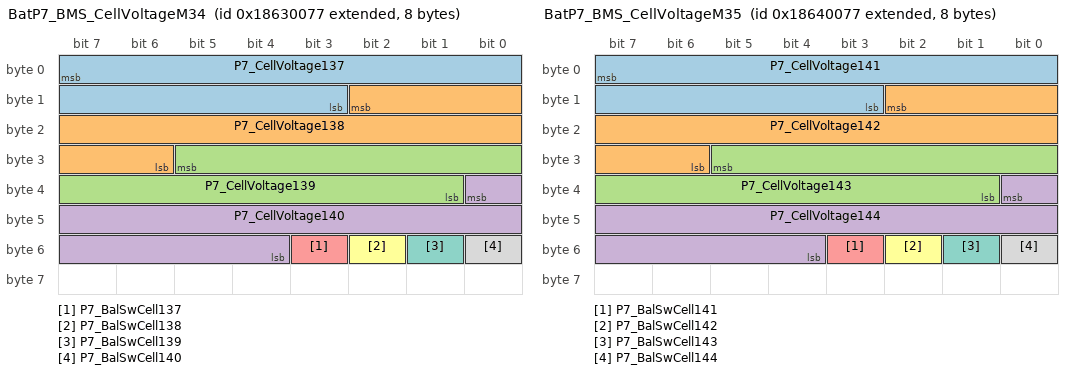
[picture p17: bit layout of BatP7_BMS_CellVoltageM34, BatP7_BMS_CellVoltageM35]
BO_ 2556625015 BatP7_BMS_CellVoltageM34: 8 BMS
 SG_ P7_CellVoltage137 : 7|13@0+ (0.001,0) [0|5] "V" VCU
 SG_ P7_CellVoltage138 : 10|13@0+ (0.001,0) [0|5] "V" VCU
 SG_ P7_CellVoltage139 : 29|13@0+ (0.001,0) [0|5] "V" VCU
 SG_ P7_CellVoltage140 : 32|13@0+ (0.001,0) [0|5] "V" VCU
 SG_ P7_BalSwCell137 : 51|1@0+ (1,0) [0|1] "" VCU
 SG_ P7_BalSwCell138 : 50|1@0+ (1,0) [0|1] "" VCU
 SG_ P7_BalSwCell139 : 49|1@0+ (1,0) [0|1] "" VCU
 SG_ P7_BalSwCell140 : 48|1@0+ (1,0) [0|1] "" VCU

BO_ 2556690551 BatP7_BMS_CellVoltageM35: 8 BMS
 SG_ P7_CellVoltage141 : 7|13@0+ (0.001,0) [0|5] "V" VCU
 SG_ P7_CellVoltage142 : 10|13@0+ (0.001,0) [0|5] "V" VCU
 SG_ P7_CellVoltage143 : 29|13@0+ (0.001,0) [0|5] "V" VCU
 SG_ P7_CellVoltage144 : 32|13@0+ (0.001,0) [0|5] "V" VCU
 SG_ P7_BalSwCell141 : 51|1@0+ (1,0) [0|1] "" VCU
 SG_ P7_BalSwCell142 : 50|1@0+ (1,0) [0|1] "" VCU
 SG_ P7_BalSwCell143 : 49|1@0+ (1,0) [0|1] "" VCU
 SG_ P7_BalSwCell144 : 48|1@0+ (1,0) [0|1] "" VCU

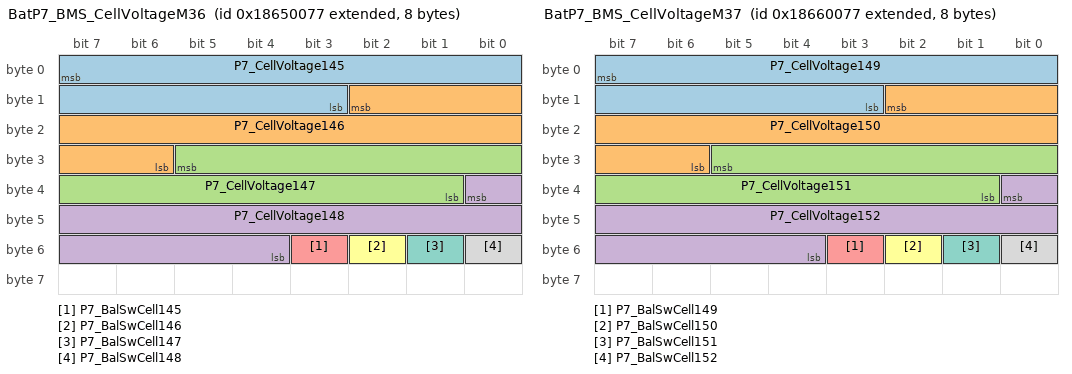
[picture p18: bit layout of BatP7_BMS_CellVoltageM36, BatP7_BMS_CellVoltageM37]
BO_ 2556756087 BatP7_BMS_CellVoltageM36: 8 BMS
 SG_ P7_CellVoltage145 : 7|13@0+ (0.001,0) [0|5] "V" VCU
 SG_ P7_CellVoltage146 : 10|13@0+ (0.001,0) [0|5] "V" VCU
 SG_ P7_CellVoltage147 : 29|13@0+ (0.001,0) [0|5] "V" VCU
 SG_ P7_CellVoltage148 : 32|13@0+ (0.001,0) [0|5] "V" VCU
 SG_ P7_BalSwCell145 : 51|1@0+ (1,0) [0|1] "" VCU
 SG_ P7_BalSwCell146 : 50|1@0+ (1,0) [0|1] "" VCU
 SG_ P7_BalSwCell147 : 49|1@0+ (1,0) [0|1] "" VCU
 SG_ P7_BalSwCell148 : 48|1@0+ (1,0) [0|1] "" VCU

BO_ 2556821623 BatP7_BMS_CellVoltageM37: 8 BMS
 SG_ P7_CellVoltage149 : 7|13@0+ (0.001,0) [0|5] "V" VCU
 SG_ P7_CellVoltage150 : 10|13@0+ (0.001,0) [0|5] "V" VCU
 SG_ P7_CellVoltage151 : 29|13@0+ (0.001,0) [0|5] "V" VCU
 SG_ P7_CellVoltage152 : 32|13@0+ (0.001,0) [0|5] "V" VCU
 SG_ P7_BalSwCell149 : 51|1@0+ (1,0) [0|1] "" VCU
 SG_ P7_BalSwCell150 : 50|1@0+ (1,0) [0|1] "" VCU
 SG_ P7_BalSwCell151 : 49|1@0+ (1,0) [0|1] "" VCU
 SG_ P7_BalSwCell152 : 48|1@0+ (1,0) [0|1] "" VCU

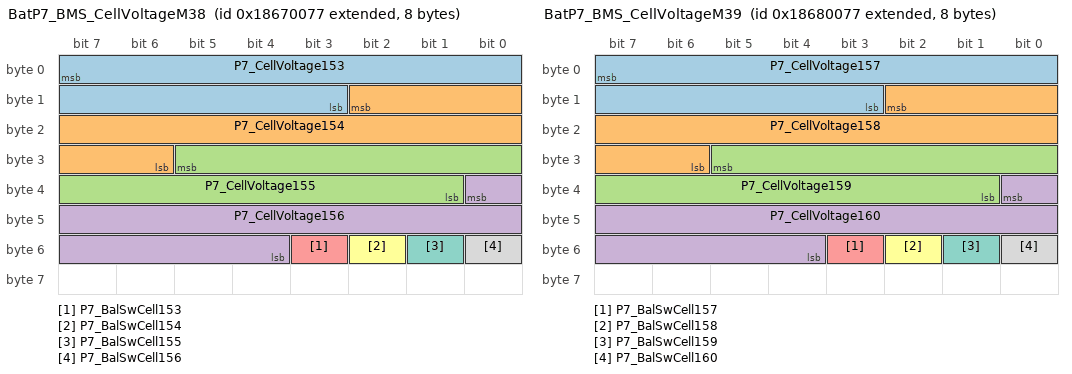
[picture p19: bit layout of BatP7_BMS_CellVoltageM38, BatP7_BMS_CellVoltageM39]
BO_ 2556887159 BatP7_BMS_CellVoltageM38: 8 BMS
 SG_ P7_CellVoltage153 : 7|13@0+ (0.001,0) [0|5] "V" VCU
 SG_ P7_CellVoltage154 : 10|13@0+ (0.001,0) [0|5] "V" VCU
 SG_ P7_CellVoltage155 : 29|13@0+ (0.001,0) [0|5] "V" VCU
 SG_ P7_CellVoltage156 : 32|13@0+ (0.001,0) [0|5] "V" VCU
 SG_ P7_BalSwCell153 : 51|1@0+ (1,0) [0|1] "" VCU
 SG_ P7_BalSwCell154 : 50|1@0+ (1,0) [0|1] "" VCU
 SG_ P7_BalSwCell155 : 49|1@0+ (1,0) [0|1] "" VCU
 SG_ P7_BalSwCell156 : 48|1@0+ (1,0) [0|1] "" VCU

BO_ 2556952695 BatP7_BMS_CellVoltageM39: 8 BMS
 SG_ P7_CellVoltage157 : 7|13@0+ (0.001,0) [0|5] "V" VCU
 SG_ P7_CellVoltage158 : 10|13@0+ (0.001,0) [0|5] "V" VCU
 SG_ P7_CellVoltage159 : 29|13@0+ (0.001,0) [0|5] "V" VCU
 SG_ P7_CellVoltage160 : 32|13@0+ (0.001,0) [0|5] "V" VCU
 SG_ P7_BalSwCell157 : 51|1@0+ (1,0) [0|1] "" VCU
 SG_ P7_BalSwCell158 : 50|1@0+ (1,0) [0|1] "" VCU
 SG_ P7_BalSwCell159 : 49|1@0+ (1,0) [0|1] "" VCU
 SG_ P7_BalSwCell160 : 48|1@0+ (1,0) [0|1] "" VCU

BO_ 2557018231 BatP7_BMS_CellVoltageM40: 8 BMS
 SG_ P7_CellVoltage161 : 7|13@0+ (0.001,0) [0|5] "V" VCU
 SG_ P7_CellVoltage162 : 10|13@0+ (0.001,0) [0|5] "V" VCU
 SG_ P7_CellVoltage163 : 29|13@0+ (0.001,0) [0|5] "V" VCU
 SG_ P7_CellVoltage164 : 32|13@0+ (0.001,0) [0|5] "V" VCU
 SG_ P7_BalSwCell161 : 51|1@0+ (1,0) [0|1] "" VCU
 SG_ P7_BalSwCell162 : 50|1@0+ (1,0) [0|1] "" VCU
 SG_ P7_BalSwCell163 : 49|1@0+ (1,0) [0|1] "" VCU
 SG_ P7_BalSwCell164 : 48|1@0+ (1,0) [0|1] "" VCU

BO_ 2557083767 BatP7_BMS_CellVoltageM41: 8 BMS
 SG_ P7_CellVoltage165 : 7|13@0+ (0.001,0) [0|5] "V" VCU
 SG_ P7_CellVoltage166 : 10|13@0+ (0.001,0) [0|5] "V" VCU
 SG_ P7_CellVoltage167 : 29|13@0+ (0.001,0) [0|5] "V" VCU
 SG_ P7_CellVoltage168 : 32|13@0+ (0.001,0) [0|5] "V" VCU
 SG_ P7_BalSwCell165 : 51|1@0+ (1,0) [0|1] "" VCU
 SG_ P7_BalSwCell166 : 50|1@0+ (1,0) [0|1] "" VCU
 SG_ P7_BalSwCell167 : 49|1@0+ (1,0) [0|1] "" VCU
 SG_ P7_BalSwCell168 : 48|1@0+ (1,0) [0|1] "" VCU

BO_ 2557149303 BatP7_BMS_CellVoltageM42: 8 BMS
 SG_ P7_CellVoltage169 : 7|13@0+ (0.001,0) [0|5] "V" VCU
 SG_ P7_CellVoltage170 : 10|13@0+ (0.001,0) [0|5] "V" VCU
 SG_ P7_CellVoltage171 : 29|13@0+ (0.001,0) [0|5] "V" VCU
 SG_ P7_CellVoltage172 : 32|13@0+ (0.001,0) [0|5] "V" VCU
 SG_ P7_BalSwCell169 : 51|1@0+ (1,0) [0|1] "" VCU
 SG_ P7_BalSwCell170 : 50|1@0+ (1,0) [0|1] "" VCU
 SG_ P7_BalSwCell171 : 49|1@0+ (1,0) [0|1] "" VCU
 SG_ P7_BalSwCell172 : 48|1@0+ (1,0) [0|1] "" VCU

BO_ 2557214839 BatP7_BMS_CellVoltageM43: 8 BMS
 SG_ P7_CellVoltage173 : 7|13@0+ (0.001,0) [0|5] "V" VCU
 SG_ P7_CellVoltage174 : 10|13@0+ (0.001,0) [0|5] "V" VCU
 SG_ P7_CellVoltage175 : 29|13@0+ (0.001,0) [0|5] "V" VCU
 SG_ P7_CellVoltage176 : 32|13@0+ (0.001,0) [0|5] "V" VCU
 SG_ P7_BalSwCell173 : 51|1@0+ (1,0) [0|1] "" VCU
 SG_ P7_BalSwCell174 : 50|1@0+ (1,0) [0|1] "" VCU
 SG_ P7_BalSwCell175 : 49|1@0+ (1,0) [0|1] "" VCU
 SG_ P7_BalSwCell176 : 48|1@0+ (1,0) [0|1] "" VCU

BO_ 2557280375 BatP7_BMS_CellVoltageM44: 8 BMS
 SG_ P7_CellVoltage177 : 7|13@0+ (0.001,0) [0|5] "V" VCU
 SG_ P7_CellVoltage178 : 10|13@0+ (0.001,0) [0|5] "V" VCU
 SG_ P7_CellVoltage179 : 29|13@0+ (0.001,0) [0|5] "V" VCU
 SG_ P7_CellVoltage180 : 32|13@0+ (0.001,0) [0|5] "V" VCU
 SG_ P7_BalSwCell177 : 51|1@0+ (1,0) [0|1] "" VCU
 SG_ P7_BalSwCell178 : 50|1@0+ (1,0) [0|1] "" VCU
 SG_ P7_BalSwCell179 : 49|1@0+ (1,0) [0|1] "" VCU
 SG_ P7_BalSwCell180 : 48|1@0+ (1,0) [0|1] "" VCU

BO_ 2557345911 BatP7_BMS_CellVoltageM45: 8 BMS
 SG_ P7_CellVoltage181 : 7|13@0+ (0.001,0) [0|5] "V" VCU
 SG_ P7_CellVoltage182 : 10|13@0+ (0.001,0) [0|5] "V" VCU
 SG_ P7_CellVoltage183 : 29|13@0+ (0.001,0) [0|5] "V" VCU
 SG_ P7_CellVoltage184 : 32|13@0+ (0.001,0) [0|5] "V" VCU
 SG_ P7_BalSwCell181 : 51|1@0+ (1,0) [0|1] "" VCU
 SG_ P7_BalSwCell182 : 50|1@0+ (1,0) [0|1] "" VCU
 SG_ P7_BalSwCell183 : 49|1@0+ (1,0) [0|1] "" VCU
 SG_ P7_BalSwCell184 : 48|1@0+ (1,0) [0|1] "" VCU

BO_ 2557411447 BatP7_BMS_CellVoltageM46: 8 BMS
 SG_ P7_CellVoltage185 : 7|13@0+ (0.001,0) [0|5] "V" VCU
 SG_ P7_CellVoltage186 : 10|13@0+ (0.001,0) [0|5] "V" VCU
 SG_ P7_CellVoltage187 : 29|13@0+ (0.001,0) [0|5] "V" VCU
 SG_ P7_CellVoltage188 : 32|13@0+ (0.001,0) [0|5] "V" VCU
 SG_ P7_BalSwCell185 : 51|1@0+ (1,0) [0|1] "" VCU
 SG_ P7_BalSwCell186 : 50|1@0+ (1,0) [0|1] "" VCU
 SG_ P7_BalSwCell187 : 49|1@0+ (1,0) [0|1] "" VCU
 SG_ P7_BalSwCell188 : 48|1@0+ (1,0) [0|1] "" VCU

BO_ 2557476983 BatP7_BMS_CellVoltageM47: 8 BMS
 SG_ P7_CellVoltage189 : 7|13@0+ (0.001,0) [0|5] "V" VCU
 SG_ P7_CellVoltage190 : 10|13@0+ (0.001,0) [0|5] "V" VCU
 SG_ P7_CellVoltage191 : 29|13@0+ (0.001,0) [0|5] "V" VCU
 SG_ P7_CellVoltage192 : 32|13@0+ (0.001,0) [0|5] "V" VCU
 SG_ P7_BalSwCell189 : 51|1@0+ (1,0) [0|1] "" VCU
 SG_ P7_BalSwCell190 : 50|1@0+ (1,0) [0|1] "" VCU
 SG_ P7_BalSwCell191 : 49|1@0+ (1,0) [0|1] "" VCU
 SG_ P7_BalSwCell192 : 48|1@0+ (1,0) [0|1] "" VCU

BO_ 2558525559 BatP7_BMS_CellTempM0: 8 BMS
 SG_ P7_CellTemp1 : 7|11@0+ (0.1,-40) [-40|150] "C" VCU
 SG_ P7_CellTemp2 : 12|11@0+ (0.1,-40) [-40|150] "C" VCU
 SG_ P7_CellTemp3 : 17|11@0+ (0.1,-40) [-40|150] "C" VCU
 SG_ P7_CellTemp4 : 38|11@0+ (0.1,-40) [-40|150] "C" VCU
 SG_ P7_CellTemp5 : 43|11@0+ (0.1,-40) [-40|150] "C" VCU

BO_ 2558591095 BatP7_BMS_CellTempM1: 8 BMS
 SG_ P7_CellTemp6 : 7|11@0+ (0.1,-40) [-40|150] "C" VCU
 SG_ P7_CellTemp7 : 12|11@0+ (0.1,-40) [-40|150] "C" VCU
 SG_ P7_CellTemp8 : 17|11@0+ (0.1,-40) [-40|150] "C" VCU
 SG_ P7_CellTemp9 : 38|11@0+ (0.1,-40) [-40|150] "C" VCU
 SG_ P7_CellTemp10 : 43|11@0+ (0.1,-40) [-40|150] "C" VCU

BO_ 2558656631 BatP7_BMS_CellTempM2: 8 BMS
 SG_ P7_CellTemp11 : 7|11@0+ (0.1,-40) [-40|150] "C" VCU
 SG_ P7_CellTemp12 : 12|11@0+ (0.1,-40) [-40|150] "C" VCU
 SG_ P7_CellTemp13 : 17|11@0+ (0.1,-40) [-40|150] "C" VCU
 SG_ P7_CellTemp14 : 38|11@0+ (0.1,-40) [-40|150] "C" VCU
 SG_ P7_CellTemp15 : 43|11@0+ (0.1,-40) [-40|150] "C" VCU

BO_ 2558722167 BatP7_BMS_CellTempM3: 8 BMS
 SG_ P7_CellTemp16 : 7|11@0+ (0.1,-40) [-40|150] "C" VCU
 SG_ P7_CellTemp17 : 12|11@0+ (0.1,-40) [-40|150] "C" VCU
 SG_ P7_CellTemp18 : 17|11@0+ (0.1,-40) [-40|150] "C" VCU
 SG_ P7_CellTemp19 : 38|11@0+ (0.1,-40) [-40|150] "C" VCU
 SG_ P7_CellTemp20 : 43|11@0+ (0.1,-40) [-40|150] "C" VCU

BO_ 2558787703 BatP7_BMS_CellTempM4: 8 BMS
 SG_ P7_CellTemp21 : 7|11@0+ (0.1,-40) [-40|150] "C" VCU
 SG_ P7_CellTemp22 : 12|11@0+ (0.1,-40) [-40|150] "C" VCU
 SG_ P7_CellTemp23 : 17|11@0+ (0.1,-40) [-40|150] "C" VCU
 SG_ P7_CellTemp24 : 38|11@0+ (0.1,-40) [-40|150] "C" VCU
 SG_ P7_CellTemp25 : 43|11@0+ (0.1,-40) [-40|150] "C" VCU

BO_ 2558853239 BatP7_BMS_CellTempM5: 8 BMS
 SG_ P7_CellTemp26 : 7|11@0+ (0.1,-40) [-40|150] "C" VCU
 SG_ P7_CellTemp27 : 12|11@0+ (0.1,-40) [-40|150] "C" VCU
 SG_ P7_CellTemp28 : 17|11@0+ (0.1,-40) [-40|150] "C" VCU
 SG_ P7_CellTemp29 : 38|11@0+ (0.1,-40) [-40|150] "C" VCU
 SG_ P7_CellTemp30 : 43|11@0+ (0.1,-40) [-40|150] "C" VCU

BO_ 2558918775 BatP7_BMS_CellTempM6: 8 BMS
 SG_ P7_CellTemp31 : 7|11@0+ (0.1,-40) [-40|150] "C" VCU
 SG_ P7_CellTemp32 : 12|11@0+ (0.1,-40) [-40|150] "C" VCU
 SG_ P7_CellTemp33 : 17|11@0+ (0.1,-40) [-40|150] "C" VCU
 SG_ P7_CellTemp34 : 38|11@0+ (0.1,-40) [-40|150] "C" VCU
 SG_ P7_CellTemp35 : 43|11@0+ (0.1,-40) [-40|150] "C" VCU

BO_ 2558984311 BatP7_BMS_CellTempM7: 8 BMS
 SG_ P7_CellTemp36 : 7|11@0+ (0.1,-40) [-40|150] "C" VCU
 SG_ P7_CellTemp37 : 12|11@0+ (0.1,-40) [-40|150] "C" VCU
 SG_ P7_CellTemp38 : 17|11@0+ (0.1,-40) [-40|150] "C" VCU
 SG_ P7_CellTemp39 : 38|11@0+ (0.1,-40) [-40|150] "C" VCU
 SG_ P7_CellTemp40 : 43|11@0+ (0.1,-40) [-40|150] "C" VCU

BO_ 2559049847 BatP7_BMS_CellTempM8: 8 BMS
 SG_ P7_CellTemp41 : 7|11@0+ (0.1,-40) [-40|150] "C" VCU
 SG_ P7_CellTemp42 : 12|11@0+ (0.1,-40) [-40|150] "C" VCU
 SG_ P7_CellTemp43 : 17|11@0+ (0.1,-40) [-40|150] "C" VCU
 SG_ P7_CellTemp44 : 38|11@0+ (0.1,-40) [-40|150] "C" VCU
 SG_ P7_CellTemp45 : 43|11@0+ (0.1,-40) [-40|150] "C" VCU

BO_ 2559115383 BatP7_BMS_CellTempM9: 8 BMS
 SG_ P7_CellTemp46 : 7|11@0+ (0.1,-40) [-40|150] "C" VCU
 SG_ P7_CellTemp47 : 12|11@0+ (0.1,-40) [-40|150] "C" VCU
 SG_ P7_CellTemp48 : 17|11@0+ (0.1,-40) [-40|150] "C" VCU
 SG_ P7_CellTemp49 : 38|11@0+ (0.1,-40) [-40|150] "C" VCU
 SG_ P7_CellTemp50 : 43|11@0+ (0.1,-40) [-40|150] "C" VCU

BO_ 2559180919 BatP7_BMS_CellTempM10: 8 BMS
 SG_ P7_CellTemp51 : 7|11@0+ (0.1,-40) [-40|150] "C" VCU
 SG_ P7_CellTemp52 : 12|11@0+ (0.1,-40) [-40|150] "C" VCU
 SG_ P7_CellTemp53 : 17|11@0+ (0.1,-40) [-40|150] "C" VCU
 SG_ P7_CellTemp54 : 38|11@0+ (0.1,-40) [-40|150] "C" VCU
 SG_ P7_CellTemp55 : 43|11@0+ (0.1,-40) [-40|150] "C" VCU

BO_ 2559246455 BatP7_BMS_CellTempM11: 8 BMS
 SG_ P7_CellTemp56 : 7|11@0+ (0.1,-40) [-40|150] "C" VCU
 SG_ P7_CellTemp57 : 12|11@0+ (0.1,-40) [-40|150] "C" VCU
 SG_ P7_CellTemp58 : 17|11@0+ (0.1,-40) [-40|150] "C" VCU
 SG_ P7_CellTemp59 : 38|11@0+ (0.1,-40) [-40|150] "C" VCU
 SG_ P7_CellTemp60 : 43|11@0+ (0.1,-40) [-40|150] "C" VCU

BO_ 2559311991 BatP7_BMS_CellTempM12: 8 BMS
 SG_ P7_CellTemp61 : 7|11@0+ (0.1,-40) [-40|150] "C" VCU
 SG_ P7_CellTemp62 : 12|11@0+ (0.1,-40) [-40|150] "C" VCU
 SG_ P7_CellTemp63 : 17|11@0+ (0.1,-40) [-40|150] "C" VCU
 SG_ P7_CellTemp64 : 38|11@0+ (0.1,-40) [-40|150] "C" VCU
 SG_ P7_CellTemp65 : 43|11@0+ (0.1,-40) [-40|150] "C" VCU

BO_ 2559377527 BatP7_BMS_CellTempM13: 8 BMS
 SG_ P7_CellTemp66 : 7|11@0+ (0.1,-40) [-40|150] "C" VCU
 SG_ P7_CellTemp67 : 12|11@0+ (0.1,-40) [-40|150] "C" VCU
 SG_ P7_CellTemp68 : 17|11@0+ (0.1,-40) [-40|150] "C" VCU
 SG_ P7_CellTemp69 : 38|11@0+ (0.1,-40) [-40|150] "C" VCU
 SG_ P7_CellTemp70 : 43|11@0+ (0.1,-40) [-40|150] "C" VCU

BO_ 2559443063 BatP7_BMS_CellTempM14: 8 BMS
 SG_ P7_CellTemp71 : 7|11@0+ (0.1,-40) [-40|150] "C" VCU
 SG_ P7_CellTemp72 : 12|11@0+ (0.1,-40) [-40|150] "C" VCU
 SG_ P7_CellTemp73 : 17|11@0+ (0.1,-40) [-40|150] "C" VCU
 SG_ P7_CellTemp74 : 38|11@0+ (0.1,-40) [-40|150] "C" VCU
 SG_ P7_CellTemp75 : 43|11@0+ (0.1,-40) [-40|150] "C" VCU

BO_ 2559508599 BatP7_BMS_CellTempM15: 8 BMS
 SG_ P7_CellTemp76 : 7|11@0+ (0.1,-40) [-40|150] "C" VCU
 SG_ P7_CellTemp77 : 12|11@0+ (0.1,-40) [-40|150] "C" VCU
 SG_ P7_CellTemp78 : 17|11@0+ (0.1,-40) [-40|150] "C" VCU
 SG_ P7_CellTemp79 : 38|11@0+ (0.1,-40) [-40|150] "C" VCU
 SG_ P7_CellTemp80 : 43|11@0+ (0.1,-40) [-40|150] "C" VCU

BO_ 2559574135 BatP7_BMS_CellTempM16: 8 BMS
 SG_ P7_CellTemp81 : 7|11@0+ (0.1,-40) [-40|150] "C" VCU
 SG_ P7_CellTemp82 : 12|11@0+ (0.1,-40) [-40|150] "C" VCU
 SG_ P7_CellTemp83 : 17|11@0+ (0.1,-40) [-40|150] "C" VCU
 SG_ P7_CellTemp84 : 38|11@0+ (0.1,-40) [-40|150] "C" VCU
 SG_ P7_CellTemp85 : 43|11@0+ (0.1,-40) [-40|150] "C" VCU

BO_ 2559639671 BatP7_BMS_CellTempM17: 8 BMS
 SG_ P7_CellTemp86 : 7|11@0+ (0.1,-40) [-40|150] "C" VCU
 SG_ P7_CellTemp87 : 12|11@0+ (0.1,-40) [-40|150] "C" VCU
 SG_ P7_CellTemp88 : 17|11@0+ (0.1,-40) [-40|150] "C" VCU
 SG_ P7_CellTemp89 : 38|11@0+ (0.1,-40) [-40|150] "C" VCU
 SG_ P7_CellTemp90 : 43|11@0+ (0.1,-40) [-40|150] "C" VCU

BO_ 2559705207 BatP7_BMS_CellTempM18: 8 BMS
 SG_ P7_CellTemp91 : 7|11@0+ (0.1,-40) [-40|150] "C" VCU
 SG_ P7_CellTemp92 : 12|11@0+ (0.1,-40) [-40|150] "C" VCU
 SG_ P7_CellTemp93 : 17|11@0+ (0.1,-40) [-40|150] "C" VCU
 SG_ P7_CellTemp94 : 38|11@0+ (0.1,-40) [-40|150] "C" VCU
 SG_ P7_CellTemp95 : 43|11@0+ (0.1,-40) [-40|150] "C" VCU

BO_ 2559770743 BatP7_BMS_CellTempM19: 8 BMS
 SG_ P7_CellTemp96 : 7|11@0+ (0.1,-40) [-40|150] "C" VCU
 SG_ P7_CellTemp97 : 12|11@0+ (0.1,-40) [-40|150] "C" VCU
 SG_ P7_CellTemp98 : 17|11@0+ (0.1,-40) [-40|150] "C" VCU
 SG_ P7_CellTemp99 : 38|11@0+ (0.1,-40) [-40|150] "C" VCU
 SG_ P7_CellTemp100 : 43|11@0+ (0.1,-40) [-40|150] "C" VCU

BO_ 2559836279 BatP7_BMS_CellTempM20: 8 BMS
 SG_ P7_CellTemp101 : 7|11@0+ (0.1,-40) [-40|150] "C" VCU
 SG_ P7_CellTemp102 : 12|11@0+ (0.1,-40) [-40|150] "C" VCU
 SG_ P7_CellTemp103 : 17|11@0+ (0.1,-40) [-40|150] "C" VCU
 SG_ P7_CellTemp104 : 38|11@0+ (0.1,-40) [-40|150] "C" VCU
 SG_ P7_CellTemp105 : 43|11@0+ (0.1,-40) [-40|150] "C" VCU

BO_ 2559901815 BatP7_BMS_CellTempM21: 8 BMS
 SG_ P7_CellTemp106 : 7|11@0+ (0.1,-40) [-40|150] "C" VCU
 SG_ P7_CellTemp107 : 12|11@0+ (0.1,-40) [-40|150] "C" VCU
 SG_ P7_CellTemp108 : 17|11@0+ (0.1,-40) [-40|150] "C" VCU
 SG_ P7_CellTemp109 : 38|11@0+ (0.1,-40) [-40|150] "C" VCU
 SG_ P7_CellTemp110 : 43|11@0+ (0.1,-40) [-40|150] "C" VCU

BO_ 2559967351 BatP7_BMS_CellTempM22: 8 BMS
 SG_ P7_CellTemp111 : 7|11@0+ (0.1,-40) [-40|150] "C" VCU
 SG_ P7_CellTemp112 : 12|11@0+ (0.1,-40) [-40|150] "C" VCU
 SG_ P7_CellTemp113 : 17|11@0+ (0.1,-40) [-40|150] "C" VCU
 SG_ P7_CellTemp114 : 38|11@0+ (0.1,-40) [-40|150] "C" VCU
 SG_ P7_CellTemp115 : 43|11@0+ (0.1,-40) [-40|150] "C" VCU

BO_ 2560032887 BatP7_BMS_CellTempM23: 8 BMS
 SG_ P7_CellTemp116 : 7|11@0+ (0.1,-40) [-40|150] "C" VCU
 SG_ P7_CellTemp117 : 12|11@0+ (0.1,-40) [-40|150] "C" VCU
 SG_ P7_CellTemp118 : 17|11@0+ (0.1,-40) [-40|150] "C" VCU
 SG_ P7_CellTemp119 : 38|11@0+ (0.1,-40) [-40|150] "C" VCU
 SG_ P7_CellTemp120 : 43|11@0+ (0.1,-40) [-40|150] "C" VCU

BO_ 2560098423 BatP7_BMS_CellTempM24: 8 BMS
 SG_ P7_CellTemp121 : 7|11@0+ (0.1,-40) [-40|150] "C" VCU
 SG_ P7_CellTemp122 : 12|11@0+ (0.1,-40) [-40|150] "C" VCU
 SG_ P7_CellTemp123 : 17|11@0+ (0.1,-40) [-40|150] "C" VCU
 SG_ P7_CellTemp124 : 38|11@0+ (0.1,-40) [-40|150] "C" VCU
 SG_ P7_CellTemp125 : 43|11@0+ (0.1,-40) [-40|150] "C" VCU

BO_ 2560163959 BatP7_BMS_CellTempM25: 8 BMS
 SG_ P7_CellTemp126 : 7|11@0+ (0.1,-40) [-40|150] "C" VCU
 SG_ P7_CellTemp127 : 12|11@0+ (0.1,-40) [-40|150] "C" VCU
 SG_ P7_CellTemp128 : 17|11@0+ (0.1,-40) [-40|150] "C" VCU
 SG_ P7_CellTemp129 : 38|11@0+ (0.1,-40) [-40|150] "C" VCU
 SG_ P7_CellTemp130 : 43|11@0+ (0.1,-40) [-40|150] "C" VCU

BO_ 2560229495 BatP7_BMS_CellTempM26: 8 BMS
 SG_ P7_CellTemp131 : 7|11@0+ (0.1,-40) [-40|150] "C" VCU
 SG_ P7_CellTemp132 : 12|11@0+ (0.1,-40) [-40|150] "C" VCU
 SG_ P7_CellTemp133 : 17|11@0+ (0.1,-40) [-40|150] "C" VCU
 SG_ P7_CellTemp134 : 38|11@0+ (0.1,-40) [-40|150] "C" VCU
 SG_ P7_CellTemp135 : 43|11@0+ (0.1,-40) [-40|150] "C" VCU

BO_ 2560295031 BatP7_BMS_CellTempM27: 8 BMS
 SG_ P7_CellTemp136 : 7|11@0+ (0.1,-40) [-40|150] "C" VCU
 SG_ P7_CellTemp137 : 12|11@0+ (0.1,-40) [-40|150] "C" VCU
 SG_ P7_CellTemp138 : 17|11@0+ (0.1,-40) [-40|150] "C" VCU
 SG_ P7_CellTemp139 : 38|11@0+ (0.1,-40) [-40|150] "C" VCU
 SG_ P7_CellTemp140 : 43|11@0+ (0.1,-40) [-40|150] "C" VCU

BO_ 2560360567 BatP7_BMS_CellTempM28: 8 BMS
 SG_ P7_CellTemp141 : 7|11@0+ (0.1,-40) [-40|150] "C" VCU
 SG_ P7_CellTemp142 : 12|11@0+ (0.1,-40) [-40|150] "C" VCU
 SG_ P7_CellTemp143 : 17|11@0+ (0.1,-40) [-40|150] "C" VCU
 SG_ P7_CellTemp144 : 38|11@0+ (0.1,-40) [-40|150] "C" VCU
 SG_ P7_CellTemp145 : 43|11@0+ (0.1,-40) [-40|150] "C" VCU

BO_ 2560426103 BatP7_BMS_CellTempM29: 8 BMS
 SG_ P7_CellTemp146 : 7|11@0+ (0.1,-40) [-40|150] "C" VCU
 SG_ P7_CellTemp147 : 12|11@0+ (0.1,-40) [-40|150] "C" VCU
 SG_ P7_CellTemp148 : 17|11@0+ (0.1,-40) [-40|150] "C" VCU
 SG_ P7_CellTemp149 : 38|11@0+ (0.1,-40) [-40|150] "C" VCU
 SG_ P7_CellTemp150 : 43|11@0+ (0.1,-40) [-40|150] "C" VCU

BO_ 2560491639 BatP7_BMS_CellTempM30: 8 BMS
 SG_ P7_CellTemp151 : 7|11@0+ (0.1,-40) [-40|150] "C" VCU
 SG_ P7_CellTemp152 : 12|11@0+ (0.1,-40) [-40|150] "C" VCU
 SG_ P7_CellTemp153 : 17|11@0+ (0.1,-40) [-40|150] "C" VCU
 SG_ P7_CellTemp154 : 38|11@0+ (0.1,-40) [-40|150] "C" VCU
 SG_ P7_CellTemp155 : 43|11@0+ (0.1,-40) [-40|150] "C" VCU

BO_ 2560557175 BatP7_BMS_CellTempM31: 8 BMS
 SG_ P7_CellTemp156 : 7|11@0+ (0.1,-40) [-40|150] "C" VCU
 SG_ P7_CellTemp157 : 12|11@0+ (0.1,-40) [-40|150] "C" VCU
 SG_ P7_CellTemp158 : 17|11@0+ (0.1,-40) [-40|150] "C" VCU
 SG_ P7_CellTemp159 : 38|11@0+ (0.1,-40) [-40|150] "C" VCU
 SG_ P7_CellTemp160 : 43|11@0+ (0.1,-40) [-40|150] "C" VCU

BO_ 2560622711 BatP7_BMS_CellTempM32: 8 BMS
 SG_ P7_CellTemp161 : 7|11@0+ (0.1,-40) [-40|150] "C" VCU
 SG_ P7_CellTemp162 : 12|11@0+ (0.1,-40) [-40|150] "C" VCU
 SG_ P7_CellTemp163 : 17|11@0+ (0.1,-40) [-40|150] "C" VCU
 SG_ P7_CellTemp164 : 38|11@0+ (0.1,-40) [-40|150] "C" VCU
 SG_ P7_CellTemp165 : 43|11@0+ (0.1,-40) [-40|150] "C" VCU

BO_ 2560688247 BatP7_BMS_CellTempM33: 8 BMS
 SG_ P7_CellTemp166 : 7|11@0+ (0.1,-40) [-40|150] "C" VCU
 SG_ P7_CellTemp167 : 12|11@0+ (0.1,-40) [-40|150] "C" VCU
 SG_ P7_CellTemp168 : 17|11@0+ (0.1,-40) [-40|150] "C" VCU
 SG_ P7_CellTemp169 : 38|11@0+ (0.1,-40) [-40|150] "C" VCU
 SG_ P7_CellTemp170 : 43|11@0+ (0.1,-40) [-40|150] "C" VCU

BO_ 2560753783 BatP7_BMS_CellTempM34: 8 BMS
 SG_ P7_CellTemp171 : 7|11@0+ (0.1,-40) [-40|150] "C" VCU
 SG_ P7_CellTemp172 : 12|11@0+ (0.1,-40) [-40|150] "C" VCU
 SG_ P7_CellTemp173 : 17|11@0+ (0.1,-40) [-40|150] "C" VCU
 SG_ P7_CellTemp174 : 38|11@0+ (0.1,-40) [-40|150] "C" VCU
 SG_ P7_CellTemp175 : 43|11@0+ (0.1,-40) [-40|150] "C" VCU

BO_ 2560819319 BatP7_BMS_CellTempM35: 8 BMS
 SG_ P7_CellTemp176 : 7|11@0+ (0.1,-40) [-40|150] "C" VCU
 SG_ P7_CellTemp177 : 12|11@0+ (0.1,-40) [-40|150] "C" VCU
 SG_ P7_CellTemp178 : 17|11@0+ (0.1,-40) [-40|150] "C" VCU
 SG_ P7_CellTemp179 : 38|11@0+ (0.1,-40) [-40|150] "C" VCU
 SG_ P7_CellTemp180 : 43|11@0+ (0.1,-40) [-40|150] "C" VCU

BO_ 2560884855 BatP7_BMS_CellTempM36: 8 BMS
 SG_ P7_CellTemp181 : 7|11@0+ (0.1,-40) [-40|150] "C" VCU
 SG_ P7_CellTemp182 : 12|11@0+ (0.1,-40) [-40|150] "C" VCU
 SG_ P7_CellTemp183 : 17|11@0+ (0.1,-40) [-40|150] "C" VCU
 SG_ P7_CellTemp184 : 38|11@0+ (0.1,-40) [-40|150] "C" VCU
 SG_ P7_CellTemp185 : 43|11@0+ (0.1,-40) [-40|150] "C" VCU

BO_ 2560950391 BatP7_BMS_CellTempM37: 8 BMS
 SG_ P7_CellTemp186 : 7|11@0+ (0.1,-40) [-40|150] "C" VCU
 SG_ P7_CellTemp187 : 12|11@0+ (0.1,-40) [-40|150] "C" VCU
 SG_ P7_CellTemp188 : 17|11@0+ (0.1,-40) [-40|150] "C" VCU
 SG_ P7_CellTemp189 : 38|11@0+ (0.1,-40) [-40|150] "C" VCU
 SG_ P7_CellTemp190 : 43|11@0+ (0.1,-40) [-40|150] "C" VCU

BO_ 2561015927 BatP7_BMS_CellTempM38: 8 BMS
 SG_ P7_CellTemp191 : 7|11@0+ (0.1,-40) [-40|150] "C" VCU
 SG_ P7_CellTemp192 : 12|11@0+ (0.1,-40) [-40|150] "C" VCU
 SG_ P7_DatLen16DbgInfo1 : 7|16@0+ (1,0) [0|65535] "" VCU
 SG_ P7_DatLen16DbgInfo2 : 23|16@0+ (1,0) [0|65535] "" VCU
 SG_ P7_DatLen16DbgInfo3 : 39|16@0+ (1,0) [0|65535] "" VCU
 SG_ P7_DatLen16DbgInfo4 : 55|16@0+ (1,0) [0|65535] "" VCU

BO_ 2550399112 BatP8_BMS_PowerSupplyInfo: 8 BMS
 SG_ P8_BMSPwrSuplVlt1 : 7|9@0+ (0.1,0) [0|50] "V" VCU
 SG_ P8_BMSPwrSuplVlt2 : 14|9@0+ (0.1,0) [0|50] "V" VCU
 SG_ P8_ChrgStationAuxPwrSuplVlt : 21|9@0+ (0.1,0) [0|50] "V" VCU
 SG_ P8_BMSKL15ON : 28|1@0+ (1,0) [0|1] "" VCU
 SG_ P8_DCStepState : 27|8@0+ (1,0) [0|255] "" VCU
 SG_ P8_ExtLvWakeup_28VOnly : 35|9@0+ (0.1,0) [0|50] "V" VCU

BO_ 2550464648 BatP8_BMS_PackUsageLimit: 8 BMS
 SG_ P8_PackVltUprLmt : 7|14@0+ (0.1,0) [0|1200] "V" VCU
 SG_ P8_PackVltLoLmt : 9|14@0+ (0.1,0) [0|1200] "V" VCU
 SG_ P8_PackMaxDschrgCrnt : 27|14@0+ (0.1,0) [0|1600] "A" VCU
 SG_ P8_PackMaxChrgCrnt : 45|14@0+ (0.1,0) [0|1600] "A" VCU

BO_ 2550530184 BatP8_BMS_PackPowerCapability: 8 BMS
 SG_ P8_PackDschrgPwrLmt : 7|10@0+ (1,0) [0|1000] "kW" VCU
 SG_ P8_PackDschrgPwrStat : 13|2@0+ (1,0) [0|3] "" VCU
 SG_ P8_PackChrgPwrLmt : 11|10@0+ (1,0) [0|1000] "kW" VCU
 SG_ P8_PackChrgPwrStat : 17|2@0+ (1,0) [0|3] "" VCU

BO_ 2550595720 BatP8_BMS_ChargingInfo: 8 BMS
 SG_ P8_ChrgrCplrStat : 7|1@0+ (1,0) [0|1] "" VCU
 SG_ P8_HVBattChrgSysStatus : 6|4@0+ (1,0) [0|15] "" VCU
 SG_ P8_DCChrgCrntCmd : 2|9@0+ (1,0) [0|500] "A" VCU
 SG_ P8_CC2Vlt : 9|8@0+ (0.1,0) [0|25] "V" VCU
 SG_ P8_DCRcptPosTemp : 17|9@0+ (0.5,-40) [-40|150] "C" VCU
 SG_ P8_DCRcptNegTemp : 24|9@0+ (0.5,-40) [-40|150] "C" VCU
 SG_ P8_Tm2FullChrg : 47|14@0+ (1,0) [0|65535] "min" VCU

BO_ 2550661256 BatP8_BMS_ThermalManagement: 8 BMS
 SG_ P8_Inlet1ClntTemp : 7|11@0+ (0.1,-40) [-40|150] "C" VCU
 SG_ P8_Inlet2ClntTemp : 12|11@0+ (0.1,-40) [-40|150] "C" VCU
 SG_ P8_Outlet1ClntTemp : 17|11@0+ (0.1,-40) [-40|150] "C" VCU
 SG_ P8_Outlet2ClntTemp : 38|11@0+ (0.1,-40) [-40|150] "C" VCU
 SG_ P8_TrgtClntTemp : 43|11@0+ (0.1,-40) [-40|150] "C" VCU
 SG_ P8_TrgtClntFlowRate : 48|9@0+ (0.2,0) [0|100] "C" VCU

BO_ 2550726792 BatP8_BMS_CellVoltMaxMin: 8 BMS
 SG_ P8_MaxCellVlt : 7|13@0+ (0.001,0) [0|5] "V" VCU
 SG_ P8_MaxCellVltNum : 10|9@0+ (1,0) [0|500] "" VCU
 SG_ P8_MinCellVlt : 17|13@0+ (0.001,0) [0|5] "V" VCU
 SG_ P8_MinCellVltNum : 36|9@0+ (1,0) [0|500] "" VCU
 SG_ P8_AvgCellVlt : 43|13@0+ (0.001,0) [0|5] "V" VCU

BO_ 2550792328 BatP8_BMS_CellTempMaxMin: 8 BMS
 SG_ P8_MaxCellTemp : 7|11@0+ (0.1,-40) [-40|150] "C" VCU
 SG_ P8_MaxCellTempNum : 12|9@0+ (1,0) [0|500] "" VCU
 SG_ P8_MinCellTemp : 19|11@0+ (0.1,-40) [-40|150] "C" VCU
 SG_ P8_MinCellTempNum : 24|9@0+ (1,0) [0|500] "" VCU
 SG_ P8_AvgCellTemp : 47|11@0+ (0.1,-40) [-40|150] "C" VCU

BO_ 2550857864 BatP8_BMS_PackFaultInfo1: 8 BMS
 SG_ P8_PackTotFltNum : 7|8@0+ (1,0) [0|200] "" VCU
 SG_ P8_CellOverVoltage : 15|2@0+ (1,0) [0|3] "" VCU
 SG_ P8_CellUnderVoltage : 13|2@0+ (1,0) [0|3] "" VCU
 SG_ P8_CellVoltageDiffHi : 11|1@0+ (1,0) [0|1] "" VCU
 SG_ P8_PackOverVoltage : 10|2@0+ (1,0) [0|3] "" VCU
 SG_ P8_PackUnderVoltage : 8|2@0+ (1,0) [0|3] "" VCU
 SG_ P8_CellOverTemp : 22|2@0+ (1,0) [0|3] "" VCU
 SG_ P8_CellTempLow : 20|1@0+ (1,0) [0|1] "" VCU
 SG_ P8_CellTempDiffHi : 19|1@0+ (1,0) [0|1] "" VCU
 SG_ P8_PackDschrgCrntHi : 18|2@0+ (1,0) [0|3] "" VCU
 SG_ P8_PackChrgCrntHi : 16|2@0+ (1,0) [0|3] "" VCU
 SG_ P8_PackCrnSnsr1OffsetHi : 30|1@0+ (1,0) [0|1] "" VCU
 SG_ P8_HVIsolFlt : 29|2@0+ (1,0) [0|3] "" VCU
 SG_ P8_HVILFlt : 27|1@0+ (1,0) [0|1] "" VCU
 SG_ P8_ThrmlRunaway : 26|1@0+ (1,0) [0|1] "" VCU
 SG_ P8_CellVoltInvalid : 25|1@0+ (1,0) [0|1] "" VCU
 SG_ P8_CellTempInvalid : 24|1@0+ (1,0) [0|1] "" VCU
 SG_ P8_DaisyChainComFlt : 39|1@0+ (1,0) [0|1] "" VCU
 SG_ P8_PackVoltRatFlt : 38|1@0+ (1,0) [0|1] "" VCU
 SG_ P8_CrntSnsr1Invalid : 37|1@0+ (1,0) [0|1] "" VCU
 SG_ P8_CrntSnsr1OOR : 36|1@0+ (1,0) [0|1] "" VCU
 SG_ P8_CrntSnsr2Invalid : 35|1@0+ (1,0) [0|1] "" VCU
 SG_ P8_CrntSnsr2OOR : 34|1@0+ (1,0) [0|1] "" VCU
 SG_ P8_PackCrnSnsr2OffsetHi : 33|1@0+ (1,0) [0|1] "" VCU
 SG_ P8_OutofEnergy : 32|1@0+ (1,0) [0|1] "" VCU
 SG_ P8_IsolDetCircErr : 47|1@0+ (1,0) [0|1] "" VCU
 SG_ P8_HVILCircShortToGND : 46|1@0+ (1,0) [0|1] "" VCU
 SG_ P8_HVILCircShortToPwr : 45|1@0+ (1,0) [0|1] "" VCU

BO_ 2550923400 BatP8_BMS_PackFaultInfo2: 8 BMS
 SG_ P8_MainPosCntctrStkClsd : 7|1@0+ (1,0) [0|1] "" VCU
 SG_ P8_MainPosCntctrStkOpn : 6|1@0+ (1,0) [0|1] "" VCU
 SG_ P8_MainNegCntctr1StkClsd : 5|1@0+ (1,0) [0|1] "" VCU
 SG_ P8_MainNegCntctr1StkOpn : 4|1@0+ (1,0) [0|1] "" VCU
 SG_ P8_MainNegCntctr2StkClsd : 3|1@0+ (1,0) [0|1] "" VCU
 SG_ P8_MainNegCntctr2StkOpn : 2|1@0+ (1,0) [0|1] "" VCU
 SG_ P8_PrechargTmOut : 1|1@0+ (1,0) [0|1] "" VCU
 SG_ P8_PrechrgCrntHi : 0|1@0+ (1,0) [0|1] "" VCU
 SG_ P8_ChrgCplrPosTempHi : 15|1@0+ (1,0) [0|1] "" VCU
 SG_ P8_ChrgCplrNegTempHi : 14|1@0+ (1,0) [0|1] "" VCU
 SG_ P8_BMSPwrSuplVlt1Hi : 13|1@0+ (1,0) [0|1] "" VCU
 SG_ P8_BMSPwrSuplVlt1Lo : 12|1@0+ (1,0) [0|1] "" VCU
 SG_ P8_BMSPwrSuplVlt2Hi : 11|1@0+ (1,0) [0|1] "" VCU
 SG_ P8_BMSPwrSuplVlt2Lo : 10|1@0+ (1,0) [0|1] "" VCU
 SG_ P8_CntctrCirPwrSuplVltLo : 9|1@0+ (1,0) [0|1] "" VCU
 SG_ P8_CntctrCirPwrSuplVltHi : 8|1@0+ (1,0) [0|1] "" VCU
 SG_ P8_CAN1BusOff : 23|1@0+ (1,0) [0|1] "" VCU
 SG_ P8_CAN1BusTmOut : 22|1@0+ (1,0) [0|1] "" VCU
 SG_ P8_CAN2BusOff : 21|1@0+ (1,0) [0|1] "" VCU
 SG_ P8_CAN2BusTmOut : 20|1@0+ (1,0) [0|1] "" VCU
 SG_ P8_CellBalCircTempHi : 19|1@0+ (1,0) [0|1] "" VCU
 SG_ P8_ClntInTempHi : 18|1@0+ (1,0) [0|1] "" VCU
 SG_ P8_ClntOutTempHi : 17|1@0+ (1,0) [0|1] "" VCU
 SG_ P8_CellExtrmUdrVolt : 16|1@0+ (1,0) [0|1] "" VCU
 SG_ P8_CellExtrmOvrVolt : 31|1@0+ (1,0) [0|1] "" VCU
 SG_ P8_Branch1DischrgCrntHi  : 30|1@0+ (1,0) [0|1] "" VCU
 SG_ P8_Branch2DischrgCrntHi  : 29|1@0+ (1,0) [0|1] "" VCU
 SG_ P8_Branch1ChrgCrntHi  : 28|1@0+ (1,0) [0|1] "" VCU
 SG_ P8_Branch2ChrgCrntHi  : 27|1@0+ (1,0) [0|1] "" VCU
 SG_ P8_InitFailed : 26|1@0+ (1,0) [0|1] "" VCU
 SG_ P8_PackErrCode : 25|10@0+ (1,0) [0|1023] "" VCU

BO_ 2550988936 BatP8_BMS_PackConfigInfo: 8 BMS
 SG_ P8_PackTotCellNum : 7|9@0+ (1,0) [0|500] "" VCU
 SG_ P8_PackTotCellTempSnsrNum : 14|9@0+ (1,0) [0|500] "" VCU

BO_ 2552299656 BatP8_BMS_BMSVersion: 8 BMS
 SG_ P8_BMSASWMajVerNum : 7|8@0+ (1,0) [0|9] "" VCU
 SG_ P8_BMSASWMinVerNum : 15|8@0+ (1,0) [0|99] "" VCU
 SG_ P8_BMSASWPatchVerNum : 23|8@0+ (1,0) [0|255] "" VCU
 SG_ P8_BMSBSWMajVerNum : 31|8@0+ (1,0) [0|9] "" VCU
 SG_ P8_BMSBSWMinVerNum : 39|8@0+ (1,0) [0|99] "" VCU
 SG_ P8_BMSBSWPatchVerNum : 47|8@0+ (1,0) [0|255] "" VCU

BO_ 2554396808 BatP8_BMS_CellVoltageM0: 8 BMS
 SG_ P8_CellVoltage1 : 7|13@0+ (0.001,0) [0|5] "V" VCU
 SG_ P8_CellVoltage2 : 10|13@0+ (0.001,0) [0|5] "V" VCU
 SG_ P8_CellVoltage3 : 29|13@0+ (0.001,0) [0|5] "V" VCU
 SG_ P8_CellVoltage4 : 32|13@0+ (0.001,0) [0|5] "V" VCU
 SG_ P8_BalSwCell1 : 51|1@0+ (1,0) [0|1] "" VCU
 SG_ P8_BalSwCell2 : 50|1@0+ (1,0) [0|1] "" VCU
 SG_ P8_BalSwCell3 : 49|1@0+ (1,0) [0|1] "" VCU
 SG_ P8_BalSwCell4 : 48|1@0+ (1,0) [0|1] "" VCU

BO_ 2554462344 BatP8_BMS_CellVoltageM1: 8 BMS
 SG_ P8_CellVoltage5 : 7|13@0+ (0.001,0) [0|5] "V" VCU
 SG_ P8_CellVoltage6 : 10|13@0+ (0.001,0) [0|5] "V" VCU
 SG_ P8_CellVoltage7 : 29|13@0+ (0.001,0) [0|5] "V" VCU
 SG_ P8_CellVoltage8 : 32|13@0+ (0.001,0) [0|5] "V" VCU
 SG_ P8_BalSwCell5 : 51|1@0+ (1,0) [0|1] "" VCU
 SG_ P8_BalSwCell6 : 50|1@0+ (1,0) [0|1] "" VCU
 SG_ P8_BalSwCell7 : 49|1@0+ (1,0) [0|1] "" VCU
 SG_ P8_BalSwCell8 : 48|1@0+ (1,0) [0|1] "" VCU

BO_ 2554527880 BatP8_BMS_CellVoltageM2: 8 BMS
 SG_ P8_CellVoltage9 : 7|13@0+ (0.001,0) [0|5] "V" VCU
 SG_ P8_CellVoltage10 : 10|13@0+ (0.001,0) [0|5] "V" VCU
 SG_ P8_CellVoltage11 : 29|13@0+ (0.001,0) [0|5] "V" VCU
 SG_ P8_CellVoltage12 : 32|13@0+ (0.001,0) [0|5] "V" VCU
 SG_ P8_BalSwCell9 : 51|1@0+ (1,0) [0|1] "" VCU
 SG_ P8_BalSwCell10 : 50|1@0+ (1,0) [0|1] "" VCU
 SG_ P8_BalSwCell11 : 49|1@0+ (1,0) [0|1] "" VCU
 SG_ P8_BalSwCell12 : 48|1@0+ (1,0) [0|1] "" VCU

BO_ 2554593416 BatP8_BMS_CellVoltageM3: 8 BMS
 SG_ P8_CellVoltage13 : 7|13@0+ (0.001,0) [0|5] "V" VCU
 SG_ P8_CellVoltage14 : 10|13@0+ (0.001,0) [0|5] "V" VCU
 SG_ P8_CellVoltage15 : 29|13@0+ (0.001,0) [0|5] "V" VCU
 SG_ P8_CellVoltage16 : 32|13@0+ (0.001,0) [0|5] "V" VCU
 SG_ P8_BalSwCell13 : 51|1@0+ (1,0) [0|1] "" VCU
 SG_ P8_BalSwCell14 : 50|1@0+ (1,0) [0|1] "" VCU
 SG_ P8_BalSwCell15 : 49|1@0+ (1,0) [0|1] "" VCU
 SG_ P8_BalSwCell16 : 48|1@0+ (1,0) [0|1] "" VCU

BO_ 2554658952 BatP8_BMS_CellVoltageM4: 8 BMS
 SG_ P8_CellVoltage17 : 7|13@0+ (0.001,0) [0|5] "V" VCU
 SG_ P8_CellVoltage18 : 10|13@0+ (0.001,0) [0|5] "V" VCU
 SG_ P8_CellVoltage19 : 29|13@0+ (0.001,0) [0|5] "V" VCU
 SG_ P8_CellVoltage20 : 32|13@0+ (0.001,0) [0|5] "V" VCU
 SG_ P8_BalSwCell17 : 51|1@0+ (1,0) [0|1] "" VCU
 SG_ P8_BalSwCell18 : 50|1@0+ (1,0) [0|1] "" VCU
 SG_ P8_BalSwCell19 : 49|1@0+ (1,0) [0|1] "" VCU
 SG_ P8_BalSwCell20 : 48|1@0+ (1,0) [0|1] "" VCU

BO_ 2554724488 BatP8_BMS_CellVoltageM5: 8 BMS
 SG_ P8_CellVoltage21 : 7|13@0+ (0.001,0) [0|5] "V" VCU
 SG_ P8_CellVoltage22 : 10|13@0+ (0.001,0) [0|5] "V" VCU
 SG_ P8_CellVoltage23 : 29|13@0+ (0.001,0) [0|5] "V" VCU
 SG_ P8_CellVoltage24 : 32|13@0+ (0.001,0) [0|5] "V" VCU
 SG_ P8_BalSwCell21 : 51|1@0+ (1,0) [0|1] "" VCU
 SG_ P8_BalSwCell22 : 50|1@0+ (1,0) [0|1] "" VCU
 SG_ P8_BalSwCell23 : 49|1@0+ (1,0) [0|1] "" VCU
 SG_ P8_BalSwCell24 : 48|1@0+ (1,0) [0|1] "" VCU

BO_ 2554790024 BatP8_BMS_CellVoltageM6: 8 BMS
 SG_ P8_CellVoltage25 : 7|13@0+ (0.001,0) [0|5] "V" VCU
 SG_ P8_CellVoltage26 : 10|13@0+ (0.001,0) [0|5] "V" VCU
 SG_ P8_CellVoltage27 : 29|13@0+ (0.001,0) [0|5] "V" VCU
 SG_ P8_CellVoltage28 : 32|13@0+ (0.001,0) [0|5] "V" VCU
 SG_ P8_BalSwCell25 : 51|1@0+ (1,0) [0|1] "" VCU
 SG_ P8_BalSwCell26 : 50|1@0+ (1,0) [0|1] "" VCU
 SG_ P8_BalSwCell27 : 49|1@0+ (1,0) [0|1] "" VCU
 SG_ P8_BalSwCell28 : 48|1@0+ (1,0) [0|1] "" VCU

BO_ 2554855560 BatP8_BMS_CellVoltageM7: 8 BMS
 SG_ P8_CellVoltage29 : 7|13@0+ (0.001,0) [0|5] "V" VCU
 SG_ P8_CellVoltage30 : 10|13@0+ (0.001,0) [0|5] "V" VCU
 SG_ P8_CellVoltage31 : 29|13@0+ (0.001,0) [0|5] "V" VCU
 SG_ P8_CellVoltage32 : 32|13@0+ (0.001,0) [0|5] "V" VCU
 SG_ P8_BalSwCell29 : 51|1@0+ (1,0) [0|1] "" VCU
 SG_ P8_BalSwCell30 : 50|1@0+ (1,0) [0|1] "" VCU
 SG_ P8_BalSwCell31 : 49|1@0+ (1,0) [0|1] "" VCU
 SG_ P8_BalSwCell32 : 48|1@0+ (1,0) [0|1] "" VCU

BO_ 2554921096 BatP8_BMS_CellVoltageM8: 8 BMS
 SG_ P8_CellVoltage33 : 7|13@0+ (0.001,0) [0|5] "V" VCU
 SG_ P8_CellVoltage34 : 10|13@0+ (0.001,0) [0|5] "V" VCU
 SG_ P8_CellVoltage35 : 29|13@0+ (0.001,0) [0|5] "V" VCU
 SG_ P8_CellVoltage36 : 32|13@0+ (0.001,0) [0|5] "V" VCU
 SG_ P8_BalSwCell33 : 51|1@0+ (1,0) [0|1] "" VCU
 SG_ P8_BalSwCell34 : 50|1@0+ (1,0) [0|1] "" VCU
 SG_ P8_BalSwCell35 : 49|1@0+ (1,0) [0|1] "" VCU
 SG_ P8_BalSwCell36 : 48|1@0+ (1,0) [0|1] "" VCU

BO_ 2554986632 BatP8_BMS_CellVoltageM9: 8 BMS
 SG_ P8_CellVoltage37 : 7|13@0+ (0.001,0) [0|5] "V" VCU
 SG_ P8_CellVoltage38 : 10|13@0+ (0.001,0) [0|5] "V" VCU
 SG_ P8_CellVoltage39 : 29|13@0+ (0.001,0) [0|5] "V" VCU
 SG_ P8_CellVoltage40 : 32|13@0+ (0.001,0) [0|5] "V" VCU
 SG_ P8_BalSwCell37 : 51|1@0+ (1,0) [0|1] "" VCU
 SG_ P8_BalSwCell38 : 50|1@0+ (1,0) [0|1] "" VCU
 SG_ P8_BalSwCell39 : 49|1@0+ (1,0) [0|1] "" VCU
 SG_ P8_BalSwCell40 : 48|1@0+ (1,0) [0|1] "" VCU

BO_ 2555052168 BatP8_BMS_CellVoltageM10: 8 BMS
 SG_ P8_CellVoltage41 : 7|13@0+ (0.001,0) [0|5] "V" VCU
 SG_ P8_CellVoltage42 : 10|13@0+ (0.001,0) [0|5] "V" VCU
 SG_ P8_CellVoltage43 : 29|13@0+ (0.001,0) [0|5] "V" VCU
 SG_ P8_CellVoltage44 : 32|13@0+ (0.001,0) [0|5] "V" VCU
 SG_ P8_BalSwCell41 : 51|1@0+ (1,0) [0|1] "" VCU
 SG_ P8_BalSwCell42 : 50|1@0+ (1,0) [0|1] "" VCU
 SG_ P8_BalSwCell43 : 49|1@0+ (1,0) [0|1] "" VCU
 SG_ P8_BalSwCell44 : 48|1@0+ (1,0) [0|1] "" VCU

BO_ 2555117704 BatP8_BMS_CellVoltageM11: 8 BMS
 SG_ P8_CellVoltage45 : 7|13@0+ (0.001,0) [0|5] "V" VCU
 SG_ P8_CellVoltage46 : 10|13@0+ (0.001,0) [0|5] "V" VCU
 SG_ P8_CellVoltage47 : 29|13@0+ (0.001,0) [0|5] "V" VCU
 SG_ P8_CellVoltage48 : 32|13@0+ (0.001,0) [0|5] "V" VCU
 SG_ P8_BalSwCell45 : 51|1@0+ (1,0) [0|1] "" VCU
 SG_ P8_BalSwCell46 : 50|1@0+ (1,0) [0|1] "" VCU
 SG_ P8_BalSwCell47 : 49|1@0+ (1,0) [0|1] "" VCU
 SG_ P8_BalSwCell48 : 48|1@0+ (1,0) [0|1] "" VCU

BO_ 2555183240 BatP8_BMS_CellVoltageM12: 8 BMS
 SG_ P8_CellVoltage49 : 7|13@0+ (0.001,0) [0|5] "V" VCU
 SG_ P8_CellVoltage50 : 10|13@0+ (0.001,0) [0|5] "V" VCU
 SG_ P8_CellVoltage51 : 29|13@0+ (0.001,0) [0|5] "V" VCU
 SG_ P8_CellVoltage52 : 32|13@0+ (0.001,0) [0|5] "V" VCU
 SG_ P8_BalSwCell49 : 51|1@0+ (1,0) [0|1] "" VCU
 SG_ P8_BalSwCell50 : 50|1@0+ (1,0) [0|1] "" VCU
 SG_ P8_BalSwCell51 : 49|1@0+ (1,0) [0|1] "" VCU
 SG_ P8_BalSwCell52 : 48|1@0+ (1,0) [0|1] "" VCU

BO_ 2555248776 BatP8_BMS_CellVoltageM13: 8 BMS
 SG_ P8_CellVoltage53 : 7|13@0+ (0.001,0) [0|5] "V" VCU
 SG_ P8_CellVoltage54 : 10|13@0+ (0.001,0) [0|5] "V" VCU
 SG_ P8_CellVoltage55 : 29|13@0+ (0.001,0) [0|5] "V" VCU
 SG_ P8_CellVoltage56 : 32|13@0+ (0.001,0) [0|5] "V" VCU
 SG_ P8_BalSwCell53 : 51|1@0+ (1,0) [0|1] "" VCU
 SG_ P8_BalSwCell54 : 50|1@0+ (1,0) [0|1] "" VCU
 SG_ P8_BalSwCell55 : 49|1@0+ (1,0) [0|1] "" VCU
 SG_ P8_BalSwCell56 : 48|1@0+ (1,0) [0|1] "" VCU

BO_ 2555314312 BatP8_BMS_CellVoltageM14: 8 BMS
 SG_ P8_CellVoltage57 : 7|13@0+ (0.001,0) [0|5] "V" VCU
 SG_ P8_CellVoltage58 : 10|13@0+ (0.001,0) [0|5] "V" VCU
 SG_ P8_CellVoltage59 : 29|13@0+ (0.001,0) [0|5] "V" VCU
 SG_ P8_CellVoltage60 : 32|13@0+ (0.001,0) [0|5] "V" VCU
 SG_ P8_BalSwCell57 : 51|1@0+ (1,0) [0|1] "" VCU
 SG_ P8_BalSwCell58 : 50|1@0+ (1,0) [0|1] "" VCU
 SG_ P8_BalSwCell59 : 49|1@0+ (1,0) [0|1] "" VCU
 SG_ P8_BalSwCell60 : 48|1@0+ (1,0) [0|1] "" VCU

BO_ 2555379848 BatP8_BMS_CellVoltageM15: 8 BMS
 SG_ P8_CellVoltage61 : 7|13@0+ (0.001,0) [0|5] "V" VCU
 SG_ P8_CellVoltage62 : 10|13@0+ (0.001,0) [0|5] "V" VCU
 SG_ P8_CellVoltage63 : 29|13@0+ (0.001,0) [0|5] "V" VCU
 SG_ P8_CellVoltage64 : 32|13@0+ (0.001,0) [0|5] "V" VCU
 SG_ P8_BalSwCell61 : 51|1@0+ (1,0) [0|1] "" VCU
 SG_ P8_BalSwCell62 : 50|1@0+ (1,0) [0|1] "" VCU
 SG_ P8_BalSwCell63 : 49|1@0+ (1,0) [0|1] "" VCU
 SG_ P8_BalSwCell64 : 48|1@0+ (1,0) [0|1] "" VCU

BO_ 2555445384 BatP8_BMS_CellVoltageM16: 8 BMS
 SG_ P8_CellVoltage65 : 7|13@0+ (0.001,0) [0|5] "V" VCU
 SG_ P8_CellVoltage66 : 10|13@0+ (0.001,0) [0|5] "V" VCU
 SG_ P8_CellVoltage67 : 29|13@0+ (0.001,0) [0|5] "V" VCU
 SG_ P8_CellVoltage68 : 32|13@0+ (0.001,0) [0|5] "V" VCU
 SG_ P8_BalSwCell65 : 51|1@0+ (1,0) [0|1] "" VCU
 SG_ P8_BalSwCell66 : 50|1@0+ (1,0) [0|1] "" VCU
 SG_ P8_BalSwCell67 : 49|1@0+ (1,0) [0|1] "" VCU
 SG_ P8_BalSwCell68 : 48|1@0+ (1,0) [0|1] "" VCU

BO_ 2555510920 BatP8_BMS_CellVoltageM17: 8 BMS
 SG_ P8_CellVoltage69 : 7|13@0+ (0.001,0) [0|5] "V" VCU
 SG_ P8_CellVoltage70 : 10|13@0+ (0.001,0) [0|5] "V" VCU
 SG_ P8_CellVoltage71 : 29|13@0+ (0.001,0) [0|5] "V" VCU
 SG_ P8_CellVoltage72 : 32|13@0+ (0.001,0) [0|5] "V" VCU
 SG_ P8_BalSwCell69 : 51|1@0+ (1,0) [0|1] "" VCU
 SG_ P8_BalSwCell70 : 50|1@0+ (1,0) [0|1] "" VCU
 SG_ P8_BalSwCell71 : 49|1@0+ (1,0) [0|1] "" VCU
 SG_ P8_BalSwCell72 : 48|1@0+ (1,0) [0|1] "" VCU

BO_ 2555576456 BatP8_BMS_CellVoltageM18: 8 BMS
 SG_ P8_CellVoltage73 : 7|13@0+ (0.001,0) [0|5] "V" VCU
 SG_ P8_CellVoltage74 : 10|13@0+ (0.001,0) [0|5] "V" VCU
 SG_ P8_CellVoltage75 : 29|13@0+ (0.001,0) [0|5] "V" VCU
 SG_ P8_CellVoltage76 : 32|13@0+ (0.001,0) [0|5] "V" VCU
 SG_ P8_BalSwCell73 : 51|1@0+ (1,0) [0|1] "" VCU
 SG_ P8_BalSwCell74 : 50|1@0+ (1,0) [0|1] "" VCU
 SG_ P8_BalSwCell75 : 49|1@0+ (1,0) [0|1] "" VCU
 SG_ P8_BalSwCell76 : 48|1@0+ (1,0) [0|1] "" VCU

BO_ 2555641992 BatP8_BMS_CellVoltageM19: 8 BMS
 SG_ P8_CellVoltage77 : 7|13@0+ (0.001,0) [0|5] "V" VCU
 SG_ P8_CellVoltage78 : 10|13@0+ (0.001,0) [0|5] "V" VCU
 SG_ P8_CellVoltage79 : 29|13@0+ (0.001,0) [0|5] "V" VCU
 SG_ P8_CellVoltage80 : 32|13@0+ (0.001,0) [0|5] "V" VCU
 SG_ P8_BalSwCell77 : 51|1@0+ (1,0) [0|1] "" VCU
 SG_ P8_BalSwCell78 : 50|1@0+ (1,0) [0|1] "" VCU
 SG_ P8_BalSwCell79 : 49|1@0+ (1,0) [0|1] "" VCU
 SG_ P8_BalSwCell80 : 48|1@0+ (1,0) [0|1] "" VCU

BO_ 2555707528 BatP8_BMS_CellVoltageM20: 8 BMS
 SG_ P8_CellVoltage81 : 7|13@0+ (0.001,0) [0|5] "V" VCU
 SG_ P8_CellVoltage82 : 10|13@0+ (0.001,0) [0|5] "V" VCU
 SG_ P8_CellVoltage83 : 29|13@0+ (0.001,0) [0|5] "V" VCU
 SG_ P8_CellVoltage84 : 32|13@0+ (0.001,0) [0|5] "V" VCU
 SG_ P8_BalSwCell81 : 51|1@0+ (1,0) [0|1] "" VCU
 SG_ P8_BalSwCell82 : 50|1@0+ (1,0) [0|1] "" VCU
 SG_ P8_BalSwCell83 : 49|1@0+ (1,0) [0|1] "" VCU
 SG_ P8_BalSwCell84 : 48|1@0+ (1,0) [0|1] "" VCU

BO_ 2555773064 BatP8_BMS_CellVoltageM21: 8 BMS
 SG_ P8_CellVoltage85 : 7|13@0+ (0.001,0) [0|5] "V" VCU
 SG_ P8_CellVoltage86 : 10|13@0+ (0.001,0) [0|5] "V" VCU
 SG_ P8_CellVoltage87 : 29|13@0+ (0.001,0) [0|5] "V" VCU
 SG_ P8_CellVoltage88 : 32|13@0+ (0.001,0) [0|5] "V" VCU
 SG_ P8_BalSwCell85 : 51|1@0+ (1,0) [0|1] "" VCU
 SG_ P8_BalSwCell86 : 50|1@0+ (1,0) [0|1] "" VCU
 SG_ P8_BalSwCell87 : 49|1@0+ (1,0) [0|1] "" VCU
 SG_ P8_BalSwCell88 : 48|1@0+ (1,0) [0|1] "" VCU

BO_ 2555838600 BatP8_BMS_CellVoltageM22: 8 BMS
 SG_ P8_CellVoltage89 : 7|13@0+ (0.001,0) [0|5] "V" VCU
 SG_ P8_CellVoltage90 : 10|13@0+ (0.001,0) [0|5] "V" VCU
 SG_ P8_CellVoltage91 : 29|13@0+ (0.001,0) [0|5] "V" VCU
 SG_ P8_CellVoltage92 : 32|13@0+ (0.001,0) [0|5] "V" VCU
 SG_ P8_BalSwCell89 : 51|1@0+ (1,0) [0|1] "" VCU
 SG_ P8_BalSwCell90 : 50|1@0+ (1,0) [0|1] "" VCU
 SG_ P8_BalSwCell91 : 49|1@0+ (1,0) [0|1] "" VCU
 SG_ P8_BalSwCell92 : 48|1@0+ (1,0) [0|1] "" VCU

BO_ 2555904136 BatP8_BMS_CellVoltageM23: 8 BMS
 SG_ P8_CellVoltage93 : 7|13@0+ (0.001,0) [0|5] "V" VCU
 SG_ P8_CellVoltage94 : 10|13@0+ (0.001,0) [0|5] "V" VCU
 SG_ P8_CellVoltage95 : 29|13@0+ (0.001,0) [0|5] "V" VCU
 SG_ P8_CellVoltage96 : 32|13@0+ (0.001,0) [0|5] "V" VCU
 SG_ P8_BalSwCell93 : 51|1@0+ (1,0) [0|1] "" VCU
 SG_ P8_BalSwCell94 : 50|1@0+ (1,0) [0|1] "" VCU
 SG_ P8_BalSwCell95 : 49|1@0+ (1,0) [0|1] "" VCU
 SG_ P8_BalSwCell96 : 48|1@0+ (1,0) [0|1] "" VCU

BO_ 2555969672 BatP8_BMS_CellVoltageM24: 8 BMS
 SG_ P8_CellVoltage97 : 7|13@0+ (0.001,0) [0|5] "V" VCU
 SG_ P8_CellVoltage98 : 10|13@0+ (0.001,0) [0|5] "V" VCU
 SG_ P8_CellVoltage99 : 29|13@0+ (0.001,0) [0|5] "V" VCU
 SG_ P8_CellVoltage100 : 32|13@0+ (0.001,0) [0|5] "V" VCU
 SG_ P8_BalSwCell97 : 51|1@0+ (1,0) [0|1] "" VCU
 SG_ P8_BalSwCell98 : 50|1@0+ (1,0) [0|1] "" VCU
 SG_ P8_BalSwCell99 : 49|1@0+ (1,0) [0|1] "" VCU
 SG_ P8_BalSwCell100 : 48|1@0+ (1,0) [0|1] "" VCU

BO_ 2556035208 BatP8_BMS_CellVoltageM25: 8 BMS
 SG_ P8_CellVoltage101 : 7|13@0+ (0.001,0) [0|5] "V" VCU
 SG_ P8_CellVoltage102 : 10|13@0+ (0.001,0) [0|5] "V" VCU
 SG_ P8_CellVoltage103 : 29|13@0+ (0.001,0) [0|5] "V" VCU
 SG_ P8_CellVoltage104 : 32|13@0+ (0.001,0) [0|5] "V" VCU
 SG_ P8_BalSwCell101 : 51|1@0+ (1,0) [0|1] "" VCU
 SG_ P8_BalSwCell102 : 50|1@0+ (1,0) [0|1] "" VCU
 SG_ P8_BalSwCell103 : 49|1@0+ (1,0) [0|1] "" VCU
 SG_ P8_BalSwCell104 : 48|1@0+ (1,0) [0|1] "" VCU

BO_ 2556100744 BatP8_BMS_CellVoltageM26: 8 BMS
 SG_ P8_CellVoltage105 : 7|13@0+ (0.001,0) [0|5] "V" VCU
 SG_ P8_CellVoltage106 : 10|13@0+ (0.001,0) [0|5] "V" VCU
 SG_ P8_CellVoltage107 : 29|13@0+ (0.001,0) [0|5] "V" VCU
 SG_ P8_CellVoltage108 : 32|13@0+ (0.001,0) [0|5] "V" VCU
 SG_ P8_BalSwCell105 : 51|1@0+ (1,0) [0|1] "" VCU
 SG_ P8_BalSwCell106 : 50|1@0+ (1,0) [0|1] "" VCU
 SG_ P8_BalSwCell107 : 49|1@0+ (1,0) [0|1] "" VCU
 SG_ P8_BalSwCell108 : 48|1@0+ (1,0) [0|1] "" VCU

BO_ 2556166280 BatP8_BMS_CellVoltageM27: 8 BMS
 SG_ P8_CellVoltage109 : 7|13@0+ (0.001,0) [0|5] "V" VCU
 SG_ P8_CellVoltage110 : 10|13@0+ (0.001,0) [0|5] "V" VCU
 SG_ P8_CellVoltage111 : 29|13@0+ (0.001,0) [0|5] "V" VCU
 SG_ P8_CellVoltage112 : 32|13@0+ (0.001,0) [0|5] "V" VCU
 SG_ P8_BalSwCell109 : 51|1@0+ (1,0) [0|1] "" VCU
 SG_ P8_BalSwCell110 : 50|1@0+ (1,0) [0|1] "" VCU
 SG_ P8_BalSwCell111 : 49|1@0+ (1,0) [0|1] "" VCU
 SG_ P8_BalSwCell112 : 48|1@0+ (1,0) [0|1] "" VCU

BO_ 2556231816 BatP8_BMS_CellVoltageM28: 8 BMS
 SG_ P8_CellVoltage113 : 7|13@0+ (0.001,0) [0|5] "V" VCU
 SG_ P8_CellVoltage114 : 10|13@0+ (0.001,0) [0|5] "V" VCU
 SG_ P8_CellVoltage115 : 29|13@0+ (0.001,0) [0|5] "V" VCU
 SG_ P8_CellVoltage116 : 32|13@0+ (0.001,0) [0|5] "V" VCU
 SG_ P8_BalSwCell113 : 51|1@0+ (1,0) [0|1] "" VCU
 SG_ P8_BalSwCell114 : 50|1@0+ (1,0) [0|1] "" VCU
 SG_ P8_BalSwCell115 : 49|1@0+ (1,0) [0|1] "" VCU
 SG_ P8_BalSwCell116 : 48|1@0+ (1,0) [0|1] "" VCU

BO_ 2556297352 BatP8_BMS_CellVoltageM29: 8 BMS
 SG_ P8_CellVoltage117 : 7|13@0+ (0.001,0) [0|5] "V" VCU
 SG_ P8_CellVoltage118 : 10|13@0+ (0.001,0) [0|5] "V" VCU
 SG_ P8_CellVoltage119 : 29|13@0+ (0.001,0) [0|5] "V" VCU
 SG_ P8_CellVoltage120 : 32|13@0+ (0.001,0) [0|5] "V" VCU
 SG_ P8_BalSwCell117 : 51|1@0+ (1,0) [0|1] "" VCU
 SG_ P8_BalSwCell118 : 50|1@0+ (1,0) [0|1] "" VCU
 SG_ P8_BalSwCell119 : 49|1@0+ (1,0) [0|1] "" VCU
 SG_ P8_BalSwCell120 : 48|1@0+ (1,0) [0|1] "" VCU

BO_ 2556362888 BatP8_BMS_CellVoltageM30: 8 BMS
 SG_ P8_CellVoltage121 : 7|13@0+ (0.001,0) [0|5] "V" VCU
 SG_ P8_CellVoltage122 : 10|13@0+ (0.001,0) [0|5] "V" VCU
 SG_ P8_CellVoltage123 : 29|13@0+ (0.001,0) [0|5] "V" VCU
 SG_ P8_CellVoltage124 : 32|13@0+ (0.001,0) [0|5] "V" VCU
 SG_ P8_BalSwCell121 : 51|1@0+ (1,0) [0|1] "" VCU
 SG_ P8_BalSwCell122 : 50|1@0+ (1,0) [0|1] "" VCU
 SG_ P8_BalSwCell123 : 49|1@0+ (1,0) [0|1] "" VCU
 SG_ P8_BalSwCell124 : 48|1@0+ (1,0) [0|1] "" VCU

BO_ 2556428424 BatP8_BMS_CellVoltageM31: 8 BMS
 SG_ P8_CellVoltage125 : 7|13@0+ (0.001,0) [0|5] "V" VCU
 SG_ P8_CellVoltage126 : 10|13@0+ (0.001,0) [0|5] "V" VCU
 SG_ P8_CellVoltage127 : 29|13@0+ (0.001,0) [0|5] "V" VCU
 SG_ P8_CellVoltage128 : 32|13@0+ (0.001,0) [0|5] "V" VCU
 SG_ P8_BalSwCell125 : 51|1@0+ (1,0) [0|1] "" VCU
 SG_ P8_BalSwCell126 : 50|1@0+ (1,0) [0|1] "" VCU
 SG_ P8_BalSwCell127 : 49|1@0+ (1,0) [0|1] "" VCU
 SG_ P8_BalSwCell128 : 48|1@0+ (1,0) [0|1] "" VCU

BO_ 2556493960 BatP8_BMS_CellVoltageM32: 8 BMS
 SG_ P8_CellVoltage129 : 7|13@0+ (0.001,0) [0|5] "V" VCU
 SG_ P8_CellVoltage130 : 10|13@0+ (0.001,0) [0|5] "V" VCU
 SG_ P8_CellVoltage131 : 29|13@0+ (0.001,0) [0|5] "V" VCU
 SG_ P8_CellVoltage132 : 32|13@0+ (0.001,0) [0|5] "V" VCU
 SG_ P8_BalSwCell129 : 51|1@0+ (1,0) [0|1] "" VCU
 SG_ P8_BalSwCell130 : 50|1@0+ (1,0) [0|1] "" VCU
 SG_ P8_BalSwCell131 : 49|1@0+ (1,0) [0|1] "" VCU
 SG_ P8_BalSwCell132 : 48|1@0+ (1,0) [0|1] "" VCU

BO_ 2556559496 BatP8_BMS_CellVoltageM33: 8 BMS
 SG_ P8_CellVoltage133 : 7|13@0+ (0.001,0) [0|5] "V" VCU
 SG_ P8_CellVoltage134 : 10|13@0+ (0.001,0) [0|5] "V" VCU
 SG_ P8_CellVoltage135 : 29|13@0+ (0.001,0) [0|5] "V" VCU
 SG_ P8_CellVoltage136 : 32|13@0+ (0.001,0) [0|5] "V" VCU
 SG_ P8_BalSwCell133 : 51|1@0+ (1,0) [0|1] "" VCU
 SG_ P8_BalSwCell134 : 50|1@0+ (1,0) [0|1] "" VCU
 SG_ P8_BalSwCell135 : 49|1@0+ (1,0) [0|1] "" VCU
 SG_ P8_BalSwCell136 : 48|1@0+ (1,0) [0|1] "" VCU

BO_ 2556625032 BatP8_BMS_CellVoltageM34: 8 BMS
 SG_ P8_CellVoltage137 : 7|13@0+ (0.001,0) [0|5] "V" VCU
 SG_ P8_CellVoltage138 : 10|13@0+ (0.001,0) [0|5] "V" VCU
 SG_ P8_CellVoltage139 : 29|13@0+ (0.001,0) [0|5] "V" VCU
 SG_ P8_CellVoltage140 : 32|13@0+ (0.001,0) [0|5] "V" VCU
 SG_ P8_BalSwCell137 : 51|1@0+ (1,0) [0|1] "" VCU
 SG_ P8_BalSwCell138 : 50|1@0+ (1,0) [0|1] "" VCU
 SG_ P8_BalSwCell139 : 49|1@0+ (1,0) [0|1] "" VCU
 SG_ P8_BalSwCell140 : 48|1@0+ (1,0) [0|1] "" VCU

BO_ 2556690568 BatP8_BMS_CellVoltageM35: 8 BMS
 SG_ P8_CellVoltage141 : 7|13@0+ (0.001,0) [0|5] "V" VCU
 SG_ P8_CellVoltage142 : 10|13@0+ (0.001,0) [0|5] "V" VCU
 SG_ P8_CellVoltage143 : 29|13@0+ (0.001,0) [0|5] "V" VCU
 SG_ P8_CellVoltage144 : 32|13@0+ (0.001,0) [0|5] "V" VCU
 SG_ P8_BalSwCell141 : 51|1@0+ (1,0) [0|1] "" VCU
 SG_ P8_BalSwCell142 : 50|1@0+ (1,0) [0|1] "" VCU
 SG_ P8_BalSwCell143 : 49|1@0+ (1,0) [0|1] "" VCU
 SG_ P8_BalSwCell144 : 48|1@0+ (1,0) [0|1] "" VCU

BO_ 2556756104 BatP8_BMS_CellVoltageM36: 8 BMS
 SG_ P8_CellVoltage145 : 7|13@0+ (0.001,0) [0|5] "V" VCU
 SG_ P8_CellVoltage146 : 10|13@0+ (0.001,0) [0|5] "V" VCU
 SG_ P8_CellVoltage147 : 29|13@0+ (0.001,0) [0|5] "V" VCU
 SG_ P8_CellVoltage148 : 32|13@0+ (0.001,0) [0|5] "V" VCU
 SG_ P8_BalSwCell145 : 51|1@0+ (1,0) [0|1] "" VCU
 SG_ P8_BalSwCell146 : 50|1@0+ (1,0) [0|1] "" VCU
 SG_ P8_BalSwCell147 : 49|1@0+ (1,0) [0|1] "" VCU
 SG_ P8_BalSwCell148 : 48|1@0+ (1,0) [0|1] "" VCU

BO_ 2556821640 BatP8_BMS_CellVoltageM37: 8 BMS
 SG_ P8_CellVoltage149 : 7|13@0+ (0.001,0) [0|5] "V" VCU
 SG_ P8_CellVoltage150 : 10|13@0+ (0.001,0) [0|5] "V" VCU
 SG_ P8_CellVoltage151 : 29|13@0+ (0.001,0) [0|5] "V" VCU
 SG_ P8_CellVoltage152 : 32|13@0+ (0.001,0) [0|5] "V" VCU
 SG_ P8_BalSwCell149 : 51|1@0+ (1,0) [0|1] "" VCU
 SG_ P8_BalSwCell150 : 50|1@0+ (1,0) [0|1] "" VCU
 SG_ P8_BalSwCell151 : 49|1@0+ (1,0) [0|1] "" VCU
 SG_ P8_BalSwCell152 : 48|1@0+ (1,0) [0|1] "" VCU

BO_ 2556887176 BatP8_BMS_CellVoltageM38: 8 BMS
 SG_ P8_CellVoltage153 : 7|13@0+ (0.001,0) [0|5] "V" VCU
 SG_ P8_CellVoltage154 : 10|13@0+ (0.001,0) [0|5] "V" VCU
 SG_ P8_CellVoltage155 : 29|13@0+ (0.001,0) [0|5] "V" VCU
 SG_ P8_CellVoltage156 : 32|13@0+ (0.001,0) [0|5] "V" VCU
 SG_ P8_BalSwCell153 : 51|1@0+ (1,0) [0|1] "" VCU
 SG_ P8_BalSwCell154 : 50|1@0+ (1,0) [0|1] "" VCU
 SG_ P8_BalSwCell155 : 49|1@0+ (1,0) [0|1] "" VCU
 SG_ P8_BalSwCell156 : 48|1@0+ (1,0) [0|1] "" VCU

BO_ 2556952712 BatP8_BMS_CellVoltageM39: 8 BMS
 SG_ P8_CellVoltage157 : 7|13@0+ (0.001,0) [0|5] "V" VCU
 SG_ P8_CellVoltage158 : 10|13@0+ (0.001,0) [0|5] "V" VCU
 SG_ P8_CellVoltage159 : 29|13@0+ (0.001,0) [0|5] "V" VCU
 SG_ P8_CellVoltage160 : 32|13@0+ (0.001,0) [0|5] "V" VCU
 SG_ P8_BalSwCell157 : 51|1@0+ (1,0) [0|1] "" VCU
 SG_ P8_BalSwCell158 : 50|1@0+ (1,0) [0|1] "" VCU
 SG_ P8_BalSwCell159 : 49|1@0+ (1,0) [0|1] "" VCU
 SG_ P8_BalSwCell160 : 48|1@0+ (1,0) [0|1] "" VCU

BO_ 2557018248 BatP8_BMS_CellVoltageM40: 8 BMS
 SG_ P8_CellVoltage161 : 7|13@0+ (0.001,0) [0|5] "V" VCU
 SG_ P8_CellVoltage162 : 10|13@0+ (0.001,0) [0|5] "V" VCU
 SG_ P8_CellVoltage163 : 29|13@0+ (0.001,0) [0|5] "V" VCU
 SG_ P8_CellVoltage164 : 32|13@0+ (0.001,0) [0|5] "V" VCU
 SG_ P8_BalSwCell161 : 51|1@0+ (1,0) [0|1] "" VCU
 SG_ P8_BalSwCell162 : 50|1@0+ (1,0) [0|1] "" VCU
 SG_ P8_BalSwCell163 : 49|1@0+ (1,0) [0|1] "" VCU
 SG_ P8_BalSwCell164 : 48|1@0+ (1,0) [0|1] "" VCU

BO_ 2557083784 BatP8_BMS_CellVoltageM41: 8 BMS
 SG_ P8_CellVoltage165 : 7|13@0+ (0.001,0) [0|5] "V" VCU
 SG_ P8_CellVoltage166 : 10|13@0+ (0.001,0) [0|5] "V" VCU
 SG_ P8_CellVoltage167 : 29|13@0+ (0.001,0) [0|5] "V" VCU
 SG_ P8_CellVoltage168 : 32|13@0+ (0.001,0) [0|5] "V" VCU
 SG_ P8_BalSwCell165 : 51|1@0+ (1,0) [0|1] "" VCU
 SG_ P8_BalSwCell166 : 50|1@0+ (1,0) [0|1] "" VCU
 SG_ P8_BalSwCell167 : 49|1@0+ (1,0) [0|1] "" VCU
 SG_ P8_BalSwCell168 : 48|1@0+ (1,0) [0|1] "" VCU

BO_ 2557149320 BatP8_BMS_CellVoltageM42: 8 BMS
 SG_ P8_CellVoltage169 : 7|13@0+ (0.001,0) [0|5] "V" VCU
 SG_ P8_CellVoltage170 : 10|13@0+ (0.001,0) [0|5] "V" VCU
 SG_ P8_CellVoltage171 : 29|13@0+ (0.001,0) [0|5] "V" VCU
 SG_ P8_CellVoltage172 : 32|13@0+ (0.001,0) [0|5] "V" VCU
 SG_ P8_BalSwCell169 : 51|1@0+ (1,0) [0|1] "" VCU
 SG_ P8_BalSwCell170 : 50|1@0+ (1,0) [0|1] "" VCU
 SG_ P8_BalSwCell171 : 49|1@0+ (1,0) [0|1] "" VCU
 SG_ P8_BalSwCell172 : 48|1@0+ (1,0) [0|1] "" VCU

BO_ 2557214856 BatP8_BMS_CellVoltageM43: 8 BMS
 SG_ P8_CellVoltage173 : 7|13@0+ (0.001,0) [0|5] "V" VCU
 SG_ P8_CellVoltage174 : 10|13@0+ (0.001,0) [0|5] "V" VCU
 SG_ P8_CellVoltage175 : 29|13@0+ (0.001,0) [0|5] "V" VCU
 SG_ P8_CellVoltage176 : 32|13@0+ (0.001,0) [0|5] "V" VCU
 SG_ P8_BalSwCell173 : 51|1@0+ (1,0) [0|1] "" VCU
 SG_ P8_BalSwCell174 : 50|1@0+ (1,0) [0|1] "" VCU
 SG_ P8_BalSwCell175 : 49|1@0+ (1,0) [0|1] "" VCU
 SG_ P8_BalSwCell176 : 48|1@0+ (1,0) [0|1] "" VCU

BO_ 2557280392 BatP8_BMS_CellVoltageM44: 8 BMS
 SG_ P8_CellVoltage177 : 7|13@0+ (0.001,0) [0|5] "V" VCU
 SG_ P8_CellVoltage178 : 10|13@0+ (0.001,0) [0|5] "V" VCU
 SG_ P8_CellVoltage179 : 29|13@0+ (0.001,0) [0|5] "V" VCU
 SG_ P8_CellVoltage180 : 32|13@0+ (0.001,0) [0|5] "V" VCU
 SG_ P8_BalSwCell177 : 51|1@0+ (1,0) [0|1] "" VCU
 SG_ P8_BalSwCell178 : 50|1@0+ (1,0) [0|1] "" VCU
 SG_ P8_BalSwCell179 : 49|1@0+ (1,0) [0|1] "" VCU
 SG_ P8_BalSwCell180 : 48|1@0+ (1,0) [0|1] "" VCU

BO_ 2557345928 BatP8_BMS_CellVoltageM45: 8 BMS
 SG_ P8_CellVoltage181 : 7|13@0+ (0.001,0) [0|5] "V" VCU
 SG_ P8_CellVoltage182 : 10|13@0+ (0.001,0) [0|5] "V" VCU
 SG_ P8_CellVoltage183 : 29|13@0+ (0.001,0) [0|5] "V" VCU
 SG_ P8_CellVoltage184 : 32|13@0+ (0.001,0) [0|5] "V" VCU
 SG_ P8_BalSwCell181 : 51|1@0+ (1,0) [0|1] "" VCU
 SG_ P8_BalSwCell182 : 50|1@0+ (1,0) [0|1] "" VCU
 SG_ P8_BalSwCell183 : 49|1@0+ (1,0) [0|1] "" VCU
 SG_ P8_BalSwCell184 : 48|1@0+ (1,0) [0|1] "" VCU

BO_ 2557411464 BatP8_BMS_CellVoltageM46: 8 BMS
 SG_ P8_CellVoltage185 : 7|13@0+ (0.001,0) [0|5] "V" VCU
 SG_ P8_CellVoltage186 : 10|13@0+ (0.001,0) [0|5] "V" VCU
 SG_ P8_CellVoltage187 : 29|13@0+ (0.001,0) [0|5] "V" VCU
 SG_ P8_CellVoltage188 : 32|13@0+ (0.001,0) [0|5] "V" VCU
 SG_ P8_BalSwCell185 : 51|1@0+ (1,0) [0|1] "" VCU
 SG_ P8_BalSwCell186 : 50|1@0+ (1,0) [0|1] "" VCU
 SG_ P8_BalSwCell187 : 49|1@0+ (1,0) [0|1] "" VCU
 SG_ P8_BalSwCell188 : 48|1@0+ (1,0) [0|1] "" VCU

BO_ 2557477000 BatP8_BMS_CellVoltageM47: 8 BMS
 SG_ P8_CellVoltage189 : 7|13@0+ (0.001,0) [0|5] "V" VCU
 SG_ P8_CellVoltage190 : 10|13@0+ (0.001,0) [0|5] "V" VCU
 SG_ P8_CellVoltage191 : 29|13@0+ (0.001,0) [0|5] "V" VCU
 SG_ P8_CellVoltage192 : 32|13@0+ (0.001,0) [0|5] "V" VCU
 SG_ P8_BalSwCell189 : 51|1@0+ (1,0) [0|1] "" VCU
 SG_ P8_BalSwCell190 : 50|1@0+ (1,0) [0|1] "" VCU
 SG_ P8_BalSwCell191 : 49|1@0+ (1,0) [0|1] "" VCU
 SG_ P8_BalSwCell192 : 48|1@0+ (1,0) [0|1] "" VCU

BO_ 2558525576 BatP8_BMS_CellTempM0: 8 BMS
 SG_ P8_CellTemp1 : 7|11@0+ (0.1,-40) [-40|150] "C" VCU
 SG_ P8_CellTemp2 : 12|11@0+ (0.1,-40) [-40|150] "C" VCU
 SG_ P8_CellTemp3 : 17|11@0+ (0.1,-40) [-40|150] "C" VCU
 SG_ P8_CellTemp4 : 38|11@0+ (0.1,-40) [-40|150] "C" VCU
 SG_ P8_CellTemp5 : 43|11@0+ (0.1,-40) [-40|150] "C" VCU

BO_ 2558591112 BatP8_BMS_CellTempM1: 8 BMS
 SG_ P8_CellTemp6 : 7|11@0+ (0.1,-40) [-40|150] "C" VCU
 SG_ P8_CellTemp7 : 12|11@0+ (0.1,-40) [-40|150] "C" VCU
 SG_ P8_CellTemp8 : 17|11@0+ (0.1,-40) [-40|150] "C" VCU
 SG_ P8_CellTemp9 : 38|11@0+ (0.1,-40) [-40|150] "C" VCU
 SG_ P8_CellTemp10 : 43|11@0+ (0.1,-40) [-40|150] "C" VCU

BO_ 2558656648 BatP8_BMS_CellTempM2: 8 BMS
 SG_ P8_CellTemp11 : 7|11@0+ (0.1,-40) [-40|150] "C" VCU
 SG_ P8_CellTemp12 : 12|11@0+ (0.1,-40) [-40|150] "C" VCU
 SG_ P8_CellTemp13 : 17|11@0+ (0.1,-40) [-40|150] "C" VCU
 SG_ P8_CellTemp14 : 38|11@0+ (0.1,-40) [-40|150] "C" VCU
 SG_ P8_CellTemp15 : 43|11@0+ (0.1,-40) [-40|150] "C" VCU

BO_ 2558722184 BatP8_BMS_CellTempM3: 8 BMS
 SG_ P8_CellTemp16 : 7|11@0+ (0.1,-40) [-40|150] "C" VCU
 SG_ P8_CellTemp17 : 12|11@0+ (0.1,-40) [-40|150] "C" VCU
 SG_ P8_CellTemp18 : 17|11@0+ (0.1,-40) [-40|150] "C" VCU
 SG_ P8_CellTemp19 : 38|11@0+ (0.1,-40) [-40|150] "C" VCU
 SG_ P8_CellTemp20 : 43|11@0+ (0.1,-40) [-40|150] "C" VCU

BO_ 2558787720 BatP8_BMS_CellTempM4: 8 BMS
 SG_ P8_CellTemp21 : 7|11@0+ (0.1,-40) [-40|150] "C" VCU
 SG_ P8_CellTemp22 : 12|11@0+ (0.1,-40) [-40|150] "C" VCU
 SG_ P8_CellTemp23 : 17|11@0+ (0.1,-40) [-40|150] "C" VCU
 SG_ P8_CellTemp24 : 38|11@0+ (0.1,-40) [-40|150] "C" VCU
 SG_ P8_CellTemp25 : 43|11@0+ (0.1,-40) [-40|150] "C" VCU

BO_ 2558853256 BatP8_BMS_CellTempM5: 8 BMS
 SG_ P8_CellTemp26 : 7|11@0+ (0.1,-40) [-40|150] "C" VCU
 SG_ P8_CellTemp27 : 12|11@0+ (0.1,-40) [-40|150] "C" VCU
 SG_ P8_CellTemp28 : 17|11@0+ (0.1,-40) [-40|150] "C" VCU
 SG_ P8_CellTemp29 : 38|11@0+ (0.1,-40) [-40|150] "C" VCU
 SG_ P8_CellTemp30 : 43|11@0+ (0.1,-40) [-40|150] "C" VCU

BO_ 2558918792 BatP8_BMS_CellTempM6: 8 BMS
 SG_ P8_CellTemp31 : 7|11@0+ (0.1,-40) [-40|150] "C" VCU
 SG_ P8_CellTemp32 : 12|11@0+ (0.1,-40) [-40|150] "C" VCU
 SG_ P8_CellTemp33 : 17|11@0+ (0.1,-40) [-40|150] "C" VCU
 SG_ P8_CellTemp34 : 38|11@0+ (0.1,-40) [-40|150] "C" VCU
 SG_ P8_CellTemp35 : 43|11@0+ (0.1,-40) [-40|150] "C" VCU

BO_ 2558984328 BatP8_BMS_CellTempM7: 8 BMS
 SG_ P8_CellTemp36 : 7|11@0+ (0.1,-40) [-40|150] "C" VCU
 SG_ P8_CellTemp37 : 12|11@0+ (0.1,-40) [-40|150] "C" VCU
 SG_ P8_CellTemp38 : 17|11@0+ (0.1,-40) [-40|150] "C" VCU
 SG_ P8_CellTemp39 : 38|11@0+ (0.1,-40) [-40|150] "C" VCU
 SG_ P8_CellTemp40 : 43|11@0+ (0.1,-40) [-40|150] "C" VCU

BO_ 2559049864 BatP8_BMS_CellTempM8: 8 BMS
 SG_ P8_CellTemp41 : 7|11@0+ (0.1,-40) [-40|150] "C" VCU
 SG_ P8_CellTemp42 : 12|11@0+ (0.1,-40) [-40|150] "C" VCU
 SG_ P8_CellTemp43 : 17|11@0+ (0.1,-40) [-40|150] "C" VCU
 SG_ P8_CellTemp44 : 38|11@0+ (0.1,-40) [-40|150] "C" VCU
 SG_ P8_CellTemp45 : 43|11@0+ (0.1,-40) [-40|150] "C" VCU

BO_ 2559115400 BatP8_BMS_CellTempM9: 8 BMS
 SG_ P8_CellTemp46 : 7|11@0+ (0.1,-40) [-40|150] "C" VCU
 SG_ P8_CellTemp47 : 12|11@0+ (0.1,-40) [-40|150] "C" VCU
 SG_ P8_CellTemp48 : 17|11@0+ (0.1,-40) [-40|150] "C" VCU
 SG_ P8_CellTemp49 : 38|11@0+ (0.1,-40) [-40|150] "C" VCU
 SG_ P8_CellTemp50 : 43|11@0+ (0.1,-40) [-40|150] "C" VCU

BO_ 2559180936 BatP8_BMS_CellTempM10: 8 BMS
 SG_ P8_CellTemp51 : 7|11@0+ (0.1,-40) [-40|150] "C" VCU
 SG_ P8_CellTemp52 : 12|11@0+ (0.1,-40) [-40|150] "C" VCU
 SG_ P8_CellTemp53 : 17|11@0+ (0.1,-40) [-40|150] "C" VCU
 SG_ P8_CellTemp54 : 38|11@0+ (0.1,-40) [-40|150] "C" VCU
 SG_ P8_CellTemp55 : 43|11@0+ (0.1,-40) [-40|150] "C" VCU

BO_ 2559246472 BatP8_BMS_CellTempM11: 8 BMS
 SG_ P8_CellTemp56 : 7|11@0+ (0.1,-40) [-40|150] "C" VCU
 SG_ P8_CellTemp57 : 12|11@0+ (0.1,-40) [-40|150] "C" VCU
 SG_ P8_CellTemp58 : 17|11@0+ (0.1,-40) [-40|150] "C" VCU
 SG_ P8_CellTemp59 : 38|11@0+ (0.1,-40) [-40|150] "C" VCU
 SG_ P8_CellTemp60 : 43|11@0+ (0.1,-40) [-40|150] "C" VCU

BO_ 2559312008 BatP8_BMS_CellTempM12: 8 BMS
 SG_ P8_CellTemp61 : 7|11@0+ (0.1,-40) [-40|150] "C" VCU
 SG_ P8_CellTemp62 : 12|11@0+ (0.1,-40) [-40|150] "C" VCU
 SG_ P8_CellTemp63 : 17|11@0+ (0.1,-40) [-40|150] "C" VCU
 SG_ P8_CellTemp64 : 38|11@0+ (0.1,-40) [-40|150] "C" VCU
 SG_ P8_CellTemp65 : 43|11@0+ (0.1,-40) [-40|150] "C" VCU

BO_ 2559377544 BatP8_BMS_CellTempM13: 8 BMS
 SG_ P8_CellTemp66 : 7|11@0+ (0.1,-40) [-40|150] "C" VCU
 SG_ P8_CellTemp67 : 12|11@0+ (0.1,-40) [-40|150] "C" VCU
 SG_ P8_CellTemp68 : 17|11@0+ (0.1,-40) [-40|150] "C" VCU
 SG_ P8_CellTemp69 : 38|11@0+ (0.1,-40) [-40|150] "C" VCU
 SG_ P8_CellTemp70 : 43|11@0+ (0.1,-40) [-40|150] "C" VCU

BO_ 2559443080 BatP8_BMS_CellTempM14: 8 BMS
 SG_ P8_CellTemp71 : 7|11@0+ (0.1,-40) [-40|150] "C" VCU
 SG_ P8_CellTemp72 : 12|11@0+ (0.1,-40) [-40|150] "C" VCU
 SG_ P8_CellTemp73 : 17|11@0+ (0.1,-40) [-40|150] "C" VCU
 SG_ P8_CellTemp74 : 38|11@0+ (0.1,-40) [-40|150] "C" VCU
 SG_ P8_CellTemp75 : 43|11@0+ (0.1,-40) [-40|150] "C" VCU

BO_ 2559508616 BatP8_BMS_CellTempM15: 8 BMS
 SG_ P8_CellTemp76 : 7|11@0+ (0.1,-40) [-40|150] "C" VCU
 SG_ P8_CellTemp77 : 12|11@0+ (0.1,-40) [-40|150] "C" VCU
 SG_ P8_CellTemp78 : 17|11@0+ (0.1,-40) [-40|150] "C" VCU
 SG_ P8_CellTemp79 : 38|11@0+ (0.1,-40) [-40|150] "C" VCU
 SG_ P8_CellTemp80 : 43|11@0+ (0.1,-40) [-40|150] "C" VCU

BO_ 2559574152 BatP8_BMS_CellTempM16: 8 BMS
 SG_ P8_CellTemp81 : 7|11@0+ (0.1,-40) [-40|150] "C" VCU
 SG_ P8_CellTemp82 : 12|11@0+ (0.1,-40) [-40|150] "C" VCU
 SG_ P8_CellTemp83 : 17|11@0+ (0.1,-40) [-40|150] "C" VCU
 SG_ P8_CellTemp84 : 38|11@0+ (0.1,-40) [-40|150] "C" VCU
 SG_ P8_CellTemp85 : 43|11@0+ (0.1,-40) [-40|150] "C" VCU

BO_ 2559639688 BatP8_BMS_CellTempM17: 8 BMS
 SG_ P8_CellTemp86 : 7|11@0+ (0.1,-40) [-40|150] "C" VCU
 SG_ P8_CellTemp87 : 12|11@0+ (0.1,-40) [-40|150] "C" VCU
 SG_ P8_CellTemp88 : 17|11@0+ (0.1,-40) [-40|150] "C" VCU
 SG_ P8_CellTemp89 : 38|11@0+ (0.1,-40) [-40|150] "C" VCU
 SG_ P8_CellTemp90 : 43|11@0+ (0.1,-40) [-40|150] "C" VCU

BO_ 2559705224 BatP8_BMS_CellTempM18: 8 BMS
 SG_ P8_CellTemp91 : 7|11@0+ (0.1,-40) [-40|150] "C" VCU
 SG_ P8_CellTemp92 : 12|11@0+ (0.1,-40) [-40|150] "C" VCU
 SG_ P8_CellTemp93 : 17|11@0+ (0.1,-40) [-40|150] "C" VCU
 SG_ P8_CellTemp94 : 38|11@0+ (0.1,-40) [-40|150] "C" VCU
 SG_ P8_CellTemp95 : 43|11@0+ (0.1,-40) [-40|150] "C" VCU

BO_ 2559770760 BatP8_BMS_CellTempM19: 8 BMS
 SG_ P8_CellTemp96 : 7|11@0+ (0.1,-40) [-40|150] "C" VCU
 SG_ P8_CellTemp97 : 12|11@0+ (0.1,-40) [-40|150] "C" VCU
 SG_ P8_CellTemp98 : 17|11@0+ (0.1,-40) [-40|150] "C" VCU
 SG_ P8_CellTemp99 : 38|11@0+ (0.1,-40) [-40|150] "C" VCU
 SG_ P8_CellTemp100 : 43|11@0+ (0.1,-40) [-40|150] "C" VCU

BO_ 2559836296 BatP8_BMS_CellTempM20: 8 BMS
 SG_ P8_CellTemp101 : 7|11@0+ (0.1,-40) [-40|150] "C" VCU
 SG_ P8_CellTemp102 : 12|11@0+ (0.1,-40) [-40|150] "C" VCU
 SG_ P8_CellTemp103 : 17|11@0+ (0.1,-40) [-40|150] "C" VCU
 SG_ P8_CellTemp104 : 38|11@0+ (0.1,-40) [-40|150] "C" VCU
 SG_ P8_CellTemp105 : 43|11@0+ (0.1,-40) [-40|150] "C" VCU

BO_ 2559901832 BatP8_BMS_CellTempM21: 8 BMS
 SG_ P8_CellTemp106 : 7|11@0+ (0.1,-40) [-40|150] "C" VCU
 SG_ P8_CellTemp107 : 12|11@0+ (0.1,-40) [-40|150] "C" VCU
 SG_ P8_CellTemp108 : 17|11@0+ (0.1,-40) [-40|150] "C" VCU
 SG_ P8_CellTemp109 : 38|11@0+ (0.1,-40) [-40|150] "C" VCU
 SG_ P8_CellTemp110 : 43|11@0+ (0.1,-40) [-40|150] "C" VCU

BO_ 2559967368 BatP8_BMS_CellTempM22: 8 BMS
 SG_ P8_CellTemp111 : 7|11@0+ (0.1,-40) [-40|150] "C" VCU
 SG_ P8_CellTemp112 : 12|11@0+ (0.1,-40) [-40|150] "C" VCU
 SG_ P8_CellTemp113 : 17|11@0+ (0.1,-40) [-40|150] "C" VCU
 SG_ P8_CellTemp114 : 38|11@0+ (0.1,-40) [-40|150] "C" VCU
 SG_ P8_CellTemp115 : 43|11@0+ (0.1,-40) [-40|150] "C" VCU

BO_ 2560032904 BatP8_BMS_CellTempM23: 8 BMS
 SG_ P8_CellTemp116 : 7|11@0+ (0.1,-40) [-40|150] "C" VCU
 SG_ P8_CellTemp117 : 12|11@0+ (0.1,-40) [-40|150] "C" VCU
 SG_ P8_CellTemp118 : 17|11@0+ (0.1,-40) [-40|150] "C" VCU
 SG_ P8_CellTemp119 : 38|11@0+ (0.1,-40) [-40|150] "C" VCU
 SG_ P8_CellTemp120 : 43|11@0+ (0.1,-40) [-40|150] "C" VCU

BO_ 2560098440 BatP8_BMS_CellTempM24: 8 BMS
 SG_ P8_CellTemp121 : 7|11@0+ (0.1,-40) [-40|150] "C" VCU
 SG_ P8_CellTemp122 : 12|11@0+ (0.1,-40) [-40|150] "C" VCU
 SG_ P8_CellTemp123 : 17|11@0+ (0.1,-40) [-40|150] "C" VCU
 SG_ P8_CellTemp124 : 38|11@0+ (0.1,-40) [-40|150] "C" VCU
 SG_ P8_CellTemp125 : 43|11@0+ (0.1,-40) [-40|150] "C" VCU

BO_ 2560163976 BatP8_BMS_CellTempM25: 8 BMS
 SG_ P8_CellTemp126 : 7|11@0+ (0.1,-40) [-40|150] "C" VCU
 SG_ P8_CellTemp127 : 12|11@0+ (0.1,-40) [-40|150] "C" VCU
 SG_ P8_CellTemp128 : 17|11@0+ (0.1,-40) [-40|150] "C" VCU
 SG_ P8_CellTemp129 : 38|11@0+ (0.1,-40) [-40|150] "C" VCU
 SG_ P8_CellTemp130 : 43|11@0+ (0.1,-40) [-40|150] "C" VCU

BO_ 2560229512 BatP8_BMS_CellTempM26: 8 BMS
 SG_ P8_CellTemp131 : 7|11@0+ (0.1,-40) [-40|150] "C" VCU
 SG_ P8_CellTemp132 : 12|11@0+ (0.1,-40) [-40|150] "C" VCU
 SG_ P8_CellTemp133 : 17|11@0+ (0.1,-40) [-40|150] "C" VCU
 SG_ P8_CellTemp134 : 38|11@0+ (0.1,-40) [-40|150] "C" VCU
 SG_ P8_CellTemp135 : 43|11@0+ (0.1,-40) [-40|150] "C" VCU

BO_ 2560295048 BatP8_BMS_CellTempM27: 8 BMS
 SG_ P8_CellTemp136 : 7|11@0+ (0.1,-40) [-40|150] "C" VCU
 SG_ P8_CellTemp137 : 12|11@0+ (0.1,-40) [-40|150] "C" VCU
 SG_ P8_CellTemp138 : 17|11@0+ (0.1,-40) [-40|150] "C" VCU
 SG_ P8_CellTemp139 : 38|11@0+ (0.1,-40) [-40|150] "C" VCU
 SG_ P8_CellTemp140 : 43|11@0+ (0.1,-40) [-40|150] "C" VCU

BO_ 2560360584 BatP8_BMS_CellTempM28: 8 BMS
 SG_ P8_CellTemp141 : 7|11@0+ (0.1,-40) [-40|150] "C" VCU
 SG_ P8_CellTemp142 : 12|11@0+ (0.1,-40) [-40|150] "C" VCU
 SG_ P8_CellTemp143 : 17|11@0+ (0.1,-40) [-40|150] "C" VCU
 SG_ P8_CellTemp144 : 38|11@0+ (0.1,-40) [-40|150] "C" VCU
 SG_ P8_CellTemp145 : 43|11@0+ (0.1,-40) [-40|150] "C" VCU

BO_ 2560426120 BatP8_BMS_CellTempM29: 8 BMS
 SG_ P8_CellTemp146 : 7|11@0+ (0.1,-40) [-40|150] "C" VCU
 SG_ P8_CellTemp147 : 12|11@0+ (0.1,-40) [-40|150] "C" VCU
 SG_ P8_CellTemp148 : 17|11@0+ (0.1,-40) [-40|150] "C" VCU
 SG_ P8_CellTemp149 : 38|11@0+ (0.1,-40) [-40|150] "C" VCU
 SG_ P8_CellTemp150 : 43|11@0+ (0.1,-40) [-40|150] "C" VCU

BO_ 2560491656 BatP8_BMS_CellTempM30: 8 BMS
 SG_ P8_CellTemp151 : 7|11@0+ (0.1,-40) [-40|150] "C" VCU
 SG_ P8_CellTemp152 : 12|11@0+ (0.1,-40) [-40|150] "C" VCU
 SG_ P8_CellTemp153 : 17|11@0+ (0.1,-40) [-40|150] "C" VCU
 SG_ P8_CellTemp154 : 38|11@0+ (0.1,-40) [-40|150] "C" VCU
 SG_ P8_CellTemp155 : 43|11@0+ (0.1,-40) [-40|150] "C" VCU

BO_ 2560557192 BatP8_BMS_CellTempM31: 8 BMS
 SG_ P8_CellTemp156 : 7|11@0+ (0.1,-40) [-40|150] "C" VCU
 SG_ P8_CellTemp157 : 12|11@0+ (0.1,-40) [-40|150] "C" VCU
 SG_ P8_CellTemp158 : 17|11@0+ (0.1,-40) [-40|150] "C" VCU
 SG_ P8_CellTemp159 : 38|11@0+ (0.1,-40) [-40|150] "C" VCU
 SG_ P8_CellTemp160 : 43|11@0+ (0.1,-40) [-40|150] "C" VCU

BO_ 2560622728 BatP8_BMS_CellTempM32: 8 BMS
 SG_ P8_CellTemp161 : 7|11@0+ (0.1,-40) [-40|150] "C" VCU
 SG_ P8_CellTemp162 : 12|11@0+ (0.1,-40) [-40|150] "C" VCU
 SG_ P8_CellTemp163 : 17|11@0+ (0.1,-40) [-40|150] "C" VCU
 SG_ P8_CellTemp164 : 38|11@0+ (0.1,-40) [-40|150] "C" VCU
 SG_ P8_CellTemp165 : 43|11@0+ (0.1,-40) [-40|150] "C" VCU

BO_ 2560688264 BatP8_BMS_CellTempM33: 8 BMS
 SG_ P8_CellTemp166 : 7|11@0+ (0.1,-40) [-40|150] "C" VCU
 SG_ P8_CellTemp167 : 12|11@0+ (0.1,-40) [-40|150] "C" VCU
 SG_ P8_CellTemp168 : 17|11@0+ (0.1,-40) [-40|150] "C" VCU
 SG_ P8_CellTemp169 : 38|11@0+ (0.1,-40) [-40|150] "C" VCU
 SG_ P8_CellTemp170 : 43|11@0+ (0.1,-40) [-40|150] "C" VCU

BO_ 2560753800 BatP8_BMS_CellTempM34: 8 BMS
 SG_ P8_CellTemp171 : 7|11@0+ (0.1,-40) [-40|150] "C" VCU
 SG_ P8_CellTemp172 : 12|11@0+ (0.1,-40) [-40|150] "C" VCU
 SG_ P8_CellTemp173 : 17|11@0+ (0.1,-40) [-40|150] "C" VCU
 SG_ P8_CellTemp174 : 38|11@0+ (0.1,-40) [-40|150] "C" VCU
 SG_ P8_CellTemp175 : 43|11@0+ (0.1,-40) [-40|150] "C" VCU

BO_ 2560819336 BatP8_BMS_CellTempM35: 8 BMS
 SG_ P8_CellTemp176 : 7|11@0+ (0.1,-40) [-40|150] "C" VCU
 SG_ P8_CellTemp177 : 12|11@0+ (0.1,-40) [-40|150] "C" VCU
 SG_ P8_CellTemp178 : 17|11@0+ (0.1,-40) [-40|150] "C" VCU
 SG_ P8_CellTemp179 : 38|11@0+ (0.1,-40) [-40|150] "C" VCU
 SG_ P8_CellTemp180 : 43|11@0+ (0.1,-40) [-40|150] "C" VCU

BO_ 2560884872 BatP8_BMS_CellTempM36: 8 BMS
 SG_ P8_CellTemp181 : 7|11@0+ (0.1,-40) [-40|150] "C" VCU
 SG_ P8_CellTemp182 : 12|11@0+ (0.1,-40) [-40|150] "C" VCU
 SG_ P8_CellTemp183 : 17|11@0+ (0.1,-40) [-40|150] "C" VCU
 SG_ P8_CellTemp184 : 38|11@0+ (0.1,-40) [-40|150] "C" VCU
 SG_ P8_CellTemp185 : 43|11@0+ (0.1,-40) [-40|150] "C" VCU

BO_ 2560950408 BatP8_BMS_CellTempM37: 8 BMS
 SG_ P8_CellTemp186 : 7|11@0+ (0.1,-40) [-40|150] "C" VCU
 SG_ P8_CellTemp187 : 12|11@0+ (0.1,-40) [-40|150] "C" VCU
 SG_ P8_CellTemp188 : 17|11@0+ (0.1,-40) [-40|150] "C" VCU
 SG_ P8_CellTemp189 : 38|11@0+ (0.1,-40) [-40|150] "C" VCU
 SG_ P8_CellTemp190 : 43|11@0+ (0.1,-40) [-40|150] "C" VCU

BO_ 2561015944 BatP8_BMS_CellTempM38: 8 BMS
 SG_ P8_CellTemp191 : 7|11@0+ (0.1,-40) [-40|150] "C" VCU
 SG_ P8_CellTemp192 : 12|11@0+ (0.1,-40) [-40|150] "C" VCU
 SG_ P8_DatLen16DbgInfo1 : 7|16@0+ (1,0) [0|65535] "" VCU
 SG_ P8_DatLen16DbgInfo2 : 23|16@0+ (1,0) [0|65535] "" VCU
 SG_ P8_DatLen16DbgInfo3 : 39|16@0+ (1,0) [0|65535] "" VCU
 SG_ P8_DatLen16DbgInfo4 : 55|16@0+ (1,0) [0|65535] "" VCU

BO_ 2550399129 BatP9_BMS_PowerSupplyInfo: 8 BMS
 SG_ P9_BMSPwrSuplVlt1 : 7|9@0+ (0.1,0) [0|50] "V" VCU
 SG_ P9_BMSPwrSuplVlt2 : 14|9@0+ (0.1,0) [0|50] "V" VCU
 SG_ P9_ChrgStationAuxPwrSuplVlt : 21|9@0+ (0.1,0) [0|50] "V" VCU
 SG_ P9_BMSKL15ON : 28|1@0+ (1,0) [0|1] "" VCU
 SG_ P9_DCStepState : 27|8@0+ (1,0) [0|255] "" VCU
 SG_ P9_ExtLvWakeup_28VOnly : 35|9@0+ (0.1,0) [0|50] "V" VCU

BO_ 2550464665 BatP9_BMS_PackUsageLimit: 8 BMS
 SG_ P9_PackVltUprLmt : 7|14@0+ (0.1,0) [0|1200] "V" VCU
 SG_ P9_PackVltLoLmt : 9|14@0+ (0.1,0) [0|1200] "V" VCU
 SG_ P9_PackMaxDschrgCrnt : 27|14@0+ (0.1,0) [0|1600] "A" VCU
 SG_ P9_PackMaxChrgCrnt : 45|14@0+ (0.1,0) [0|1600] "A" VCU

BO_ 2550530201 BatP9_BMS_PackPowerCapability: 8 BMS
 SG_ P9_PackDschrgPwrLmt : 7|10@0+ (1,0) [0|1000] "kW" VCU
 SG_ P9_PackDschrgPwrStat : 13|2@0+ (1,0) [0|3] "" VCU
 SG_ P9_PackChrgPwrLmt : 11|10@0+ (1,0) [0|1000] "kW" VCU
 SG_ P9_PackChrgPwrStat : 17|2@0+ (1,0) [0|3] "" VCU

CM_ SG_ 2550595703 P7_ChrgrCplrStat "电池包7的充电枪连接状态";
CM_ SG_ 2550595703 P7_HVBattChrgSysStatus "电池包7的充电系统状态";
CM_ SG_ 2550595703 P7_DCChrgCrntCmd "电池包7的直流充电请求电流";
CM_ SG_ 2550595703 P7_CC2Vlt "电池包7的CC2电压值";
CM_ SG_ 2550595703 P7_DCRcptPosTemp "电池包7的快充充电插座正极温度";
CM_ SG_ 2550595703 P7_DCRcptNegTemp "电池包7的快充充电插座负极温度";
CM_ SG_ 2550595703 P7_Tm2FullChrg "电池包7满充剩余时间";
CM_ SG_ 2550661239 P7_Inlet1ClntTemp "进水口1冷却液温度";
CM_ SG_ 2550661239 P7_Inlet2ClntTemp "进水口2冷却液温度";
CM_ SG_ 2550661239 P7_Outlet1ClntTemp "出水口1冷却液温度";
CM_ SG_ 2550661239 P7_Outlet2ClntTemp "出水口2冷却液温度";
CM_ SG_ 2550661239 P7_TrgtClntTemp "冷却水目标温度";
CM_ SG_ 2550661239 P7_TrgtClntFlowRate "冷却水目标流量";
CM_ SG_ 2550726775 P7_MaxCellVlt "电池包7的最大单体电压";
CM_ SG_ 2550726775 P7_MaxCellVltNum "电池包7的最大单体电压编号";
CM_ SG_ 2550726775 P7_MinCellVlt "电池包7的最小单体电压";
CM_ SG_ 2550726775 P7_MinCellVltNum "电池包7的最小单体电压编号";
CM_ SG_ 2550726775 P7_AvgCellVlt "电池包7的平均单体电压";
CM_ SG_ 2550792311 P7_MaxCellTemp "电池包7的最高单体温度";
CM_ SG_ 2550792311 P7_MaxCellTempNum "电池包7的最高单体温度编号";
CM_ SG_ 2550792311 P7_MinCellTemp "电池包7的最低单体温度";
CM_ SG_ 2550792311 P7_MinCellTempNum "电池包7的最低单体温度编号";
CM_ SG_ 2550792311 P7_AvgCellTemp "电池包7的单体平均温度";
CM_ SG_ 2550857847 P7_PackTotFltNum "电池包7的电池故障总数";
CM_ SG_ 2550857847 P7_CellOverVoltage "电池包7的单体过压";
CM_ SG_ 2550857847 P7_CellUnderVoltage "电池包7的单体欠压";
CM_ SG_ 2550857847 P7_CellVoltageDiffHi "电池包7的单体压差过大";
CM_ SG_ 2550857847 P7_PackOverVoltage "电池包7的电压过高";
CM_ SG_ 2550857847 P7_PackUnderVoltage "电池包7的电压过低";
CM_ SG_ 2550857847 P7_CellOverTemp "电池包7的单体过温";
CM_ SG_ 2550857847 P7_CellTempLow "电池包7的单体温度过低";
CM_ SG_ 2550857847 P7_CellTempDiffHi "电池包7的单体温度差异过大";
CM_ SG_ 2550857847 P7_PackDschrgCrntHi "电池包7的放电电流过流";
CM_ SG_ 2550857847 P7_PackChrgCrntHi "电池包7的充电电流过流";
CM_ SG_ 2550857847 P7_PackCrnSnsr1OffsetHi "电池包7的电流传感器1零漂过大";
CM_ SG_ 2550857847 P7_HVIsolFlt "电池包7的高压绝缘故障";
CM_ SG_ 2550857847 P7_HVILFlt "电池包7的高压互锁故障";
CM_ SG_ 2550857847 P7_ThrmlRunaway "电池包7的热失控故障";
CM_ SG_ 2550857847 P7_CellVoltInvalid "电池包7的单体电压采样失效";
CM_ SG_ 2550857847 P7_CellTempInvalid "电池包7的电芯温度采样失效";
CM_ SG_ 2550857847 P7_DaisyChainComFlt "电池包7的菊花链通信故障";
CM_ SG_ 2550857847 P7_PackVoltRatFlt "电池包7的总电压与单体电压总和偏差过大";
CM_ SG_ 2550857847 P7_CrntSnsr1Invalid "电池包7的电流传感器1电流采样失效";
CM_ SG_ 2550857847 P7_CrntSnsr1OOR "电池包7的电流传感器1电流超出采样范围";
CM_ SG_ 2550857847 P7_CrntSnsr2Invalid "电池包7的电流传感器2电流采样失效";
CM_ SG_ 2550857847 P7_CrntSnsr2OOR "电池包7的电流传感器2电流超出采样范围";
CM_ SG_ 2550857847 P7_PackCrnSnsr2OffsetHi "电池包7的电流传感器2零漂过大";
CM_ SG_ 2550857847 P7_OutofEnergy "电池包7的电池剩余电量低";
CM_ SG_ 2550857847 P7_IsolDetCircErr "电池包7的绝缘检测电路失效";
CM_ SG_ 2550857847 P7_HVILCircShortToGND "电池包7的高压互锁对地短路";
CM_ SG_ 2550857847 P7_HVILCircShortToPwr "电池包7的高压互锁对电源短路";
CM_ SG_ 2550923383 P7_MainPosCntctrStkClsd "电池包7的主正继电器粘连故障";
CM_ SG_ 2550923383 P7_MainPosCntctrStkOpn "电池包7的主正继电器常开故障";
CM_ SG_ 2550923383 P7_MainNegCntctr1StkClsd "电池包7的主负继电器1粘连故障";
CM_ SG_ 2550923383 P7_MainNegCntctr1StkOpn "电池包7的主负继电器1常开故障";
CM_ SG_ 2550923383 P7_MainNegCntctr2StkClsd "电池包7的主负继电器2粘连故障";
CM_ SG_ 2550923383 P7_MainNegCntctr2StkOpn "电池包7的主负继电器2常开故障";
CM_ SG_ 2550923383 P7_PrechargTmOut "电池包7的预充超时故障";
CM_ SG_ 2550923383 P7_PrechrgCrntHi "电池包7的预充过流故障";
CM_ SG_ 2550923383 P7_ChrgCplrPosTempHi "电池包7的充电正极接口温度过高故障";
CM_ SG_ 2550923383 P7_ChrgCplrNegTempHi "电池包7的充电负极接口温度过高故障";
CM_ SG_ 2550923383 P7_BMSPwrSuplVlt1Hi "电池包7的BMS供电电压1过高";
CM_ SG_ 2550923383 P7_BMSPwrSuplVlt1Lo "电池包7的BMS供电电压1过低";
CM_ SG_ 2550923383 P7_BMSPwrSuplVlt2Hi "电池包7的BMS供电电压2过高";
CM_ SG_ 2550923383 P7_BMSPwrSuplVlt2Lo "电池包7的BMS供电电压2过低";
CM_ SG_ 2550923383 P7_CntctrCirPwrSuplVltLo "电池包7的继电器驱动供电电压过低";
CM_ SG_ 2550923383 P7_CntctrCirPwrSuplVltHi "电池包7的继电器驱动供电电压过高";
CM_ SG_ 2550923383 P7_CAN1BusOff "电池包7的CAN1通信Bus off";
CM_ SG_ 2550923383 P7_CAN1BusTmOut "电池包7的CAN1报文超时（Timeout）";
CM_ SG_ 2550923383 P7_CAN2BusOff "电池包7的CAN2通信Bus off";
CM_ SG_ 2550923383 P7_CAN2BusTmOut "电池包7的CAN2报文超时（Timeout）";
CM_ SG_ 2550923383 P7_CellBalCircTempHi "电池包7的均衡电路过温";
CM_ SG_ 2550923383 P7_ClntInTempHi "电池包7的入水口温度过高";
CM_ SG_ 2550923383 P7_ClntOutTempHi "电池包7的出水口温度过高";
CM_ SG_ 2550923383 P7_CellExtrmUdrVolt "电池包7的单体极限欠压";
CM_ SG_ 2550923383 P7_CellExtrmOvrVolt "电池包7的单体极限过压";
CM_ SG_ 2550923383 P7_Branch1DischrgCrntHi  "电池包7的支路1放电过流";
CM_ SG_ 2550923383 P7_Branch2DischrgCrntHi  "电池包7的支路2放电过流";
CM_ SG_ 2550923383 P7_Branch1ChrgCrntHi  "电池包7的支路1充电过流";
CM_ SG_ 2550923383 P7_Branch2ChrgCrntHi  "电池包7的支路2充电过流";
CM_ SG_ 2550923383 P7_InitFailed "电池包7的BMS初始化失败";
CM_ SG_ 2550923383 P7_PackErrCode "电池包7的故障代码";
CM_ SG_ 2550988919 P7_PackTotCellNum "电池包7的单体电池总数";
CM_ SG_ 2550988919 P7_PackTotCellTempSnsrNum "电池包7的单体温度传感器总数";
CM_ SG_ 2552299639 P7_BMSASWMajVerNum "电池包7的BMS应用层软件主版本号";
CM_ SG_ 2552299639 P7_BMSASWMinVerNum "电池包7的BMS应用层软件子版本号";
CM_ SG_ 2552299639 P7_BMSASWPatchVerNum "电池包7的BMS应用层软件修订版本号";
CM_ SG_ 2552299639 P7_BMSBSWMajVerNum "电池包7的BMS底层软件主版本号";
CM_ SG_ 2552299639 P7_BMSBSWMinVerNum "电池包7的BMS底层软件子版本号";
CM_ SG_ 2552299639 P7_BMSBSWPatchVerNum "电池包7的BMS底层软件修订版本号";
CM_ SG_ 2554396791 P7_CellVoltage1 "电池包7的单体电压1";
CM_ SG_ 2554396791 P7_CellVoltage2 "电池包7的单体电压2";
CM_ SG_ 2554396791 P7_CellVoltage3 "电池包7的单体电压3";
CM_ SG_ 2554396791 P7_CellVoltage4 "电池包7的单体电压4";
CM_ SG_ 2554396791 P7_BalSwCell1 "电池包7的电芯1均衡状态";
CM_ SG_ 2554396791 P7_BalSwCell2 "电池包7的电芯2均衡状态";
CM_ SG_ 2554396791 P7_BalSwCell3 "电池包7的电芯3均衡状态";
CM_ SG_ 2554396791 P7_BalSwCell4 "电池包7的电芯4均衡状态";
CM_ SG_ 2554462327 P7_CellVoltage5 "电池包7的单体电压5";
CM_ SG_ 2554462327 P7_CellVoltage6 "电池包7的单体电压6";
CM_ SG_ 2554462327 P7_CellVoltage7 "电池包7的单体电压7";
CM_ SG_ 2554462327 P7_CellVoltage8 "电池包7的单体电压8";
CM_ SG_ 2554462327 P7_BalSwCell5 "电池包7的电芯5均衡状态";
CM_ SG_ 2554462327 P7_BalSwCell6 "电池包7的电芯6均衡状态";
CM_ SG_ 2554462327 P7_BalSwCell7 "电池包7的电芯7均衡状态";
CM_ SG_ 2554462327 P7_BalSwCell8 "电池包7的电芯8均衡状态";
CM_ SG_ 2554527863 P7_CellVoltage9 "电池包7的单体电压9";
CM_ SG_ 2554527863 P7_CellVoltage10 "电池包7的单体电压10";
CM_ SG_ 2554527863 P7_CellVoltage11 "电池包7的单体电压11";
CM_ SG_ 2554527863 P7_CellVoltage12 "电池包7的单体电压12";
CM_ SG_ 2554527863 P7_BalSwCell9 "电池包7的电芯9均衡状态";
CM_ SG_ 2554527863 P7_BalSwCell10 "电池包7的电芯10均衡状态";
CM_ SG_ 2554527863 P7_BalSwCell11 "电池包7的电芯11均衡状态";
CM_ SG_ 2554527863 P7_BalSwCell12 "电池包7的电芯12均衡状态";
CM_ SG_ 2554593399 P7_CellVoltage13 "电池包7的单体电压13";
CM_ SG_ 2554593399 P7_CellVoltage14 "电池包7的单体电压14";
CM_ SG_ 2554593399 P7_CellVoltage15 "电池包7的单体电压15";
CM_ SG_ 2554593399 P7_CellVoltage16 "电池包7的单体电压16";
CM_ SG_ 2554593399 P7_BalSwCell13 "电池包7的电芯13均衡状态";
CM_ SG_ 2554593399 P7_BalSwCell14 "电池包7的电芯14均衡状态";
CM_ SG_ 2554593399 P7_BalSwCell15 "电池包7的电芯15均衡状态";
CM_ SG_ 2554593399 P7_BalSwCell16 "电池包7的电芯16均衡状态";
CM_ SG_ 2554658935 P7_CellVoltage17 "电池包7的单体电压17";
CM_ SG_ 2554658935 P7_CellVoltage18 "电池包7的单体电压18";
CM_ SG_ 2554658935 P7_CellVoltage19 "电池包7的单体电压19";
CM_ SG_ 2554658935 P7_CellVoltage20 "电池包7的单体电压20";
CM_ SG_ 2554658935 P7_BalSwCell17 "电池包7的电芯17均衡状态";
CM_ SG_ 2554658935 P7_BalSwCell18 "电池包7的电芯18均衡状态";
CM_ SG_ 2554658935 P7_BalSwCell19 "电池包7的电芯19均衡状态";
CM_ SG_ 2554658935 P7_BalSwCell20 "电池包7的电芯20均衡状态";
CM_ SG_ 2554724471 P7_CellVoltage21 "电池包7的单体电压21";
CM_ SG_ 2554724471 P7_CellVoltage22 "电池包7的单体电压22";
CM_ SG_ 2554724471 P7_CellVoltage23 "电池包7的单体电压23";
CM_ SG_ 2554724471 P7_CellVoltage24 "电池包7的单体电压24";
CM_ SG_ 2554724471 P7_BalSwCell21 "电池包7的电芯21均衡状态";
CM_ SG_ 2554724471 P7_BalSwCell22 "电池包7的电芯22均衡状态";
CM_ SG_ 2554724471 P7_BalSwCell23 "电池包7的电芯23均衡状态";
CM_ SG_ 2554724471 P7_BalSwCell24 "电池包7的电芯24均衡状态";
CM_ SG_ 2554790007 P7_CellVoltage25 "电池包7的单体电压25";
CM_ SG_ 2554790007 P7_CellVoltage26 "电池包7的单体电压26";
CM_ SG_ 2554790007 P7_CellVoltage27 "电池包7的单体电压27";
CM_ SG_ 2554790007 P7_CellVoltage28 "电池包7的单体电压28";
CM_ SG_ 2554790007 P7_BalSwCell25 "电池包7的电芯25均衡状态";
CM_ SG_ 2554790007 P7_BalSwCell26 "电池包7的电芯26均衡状态";
CM_ SG_ 2554790007 P7_BalSwCell27 "电池包7的电芯27均衡状态";
CM_ SG_ 2554790007 P7_BalSwCell28 "电池包7的电芯28均衡状态";
CM_ SG_ 2554855543 P7_CellVoltage29 "电池包7的单体电压29";
CM_ SG_ 2554855543 P7_CellVoltage30 "电池包7的单体电压30";
CM_ SG_ 2554855543 P7_CellVoltage31 "电池包7的单体电压31";
CM_ SG_ 2554855543 P7_CellVoltage32 "电池包7的单体电压32";
CM_ SG_ 2554855543 P7_BalSwCell29 "电池包7的电芯29均衡状态";
CM_ SG_ 2554855543 P7_BalSwCell30 "电池包7的电芯30均衡状态";
CM_ SG_ 2554855543 P7_BalSwCell31 "电池包7的电芯31均衡状态";
CM_ SG_ 2554855543 P7_BalSwCell32 "电池包7的电芯32均衡状态";
CM_ SG_ 2554921079 P7_CellVoltage33 "电池包7的单体电压33";
CM_ SG_ 2554921079 P7_CellVoltage34 "电池包7的单体电压34";
CM_ SG_ 2554921079 P7_CellVoltage35 "电池包7的单体电压35";
CM_ SG_ 2554921079 P7_CellVoltage36 "电池包7的单体电压36";
CM_ SG_ 2554921079 P7_BalSwCell33 "电池包7的电芯33均衡状态";
CM_ SG_ 2554921079 P7_BalSwCell34 "电池包7的电芯34均衡状态";
CM_ SG_ 2554921079 P7_BalSwCell35 "电池包7的电芯35均衡状态";
CM_ SG_ 2554921079 P7_BalSwCell36 "电池包7的电芯36均衡状态";
CM_ SG_ 2554986615 P7_CellVoltage37 "电池包7的单体电压37";
CM_ SG_ 2554986615 P7_CellVoltage38 "电池包7的单体电压38";
CM_ SG_ 2554986615 P7_CellVoltage39 "电池包7的单体电压39";
CM_ SG_ 2554986615 P7_CellVoltage40 "电池包7的单体电压40";
CM_ SG_ 2554986615 P7_BalSwCell37 "电池包7的电芯37均衡状态";
CM_ SG_ 2554986615 P7_BalSwCell38 "电池包7的电芯38均衡状态";
CM_ SG_ 2554986615 P7_BalSwCell39 "电池包7的电芯39均衡状态";
CM_ SG_ 2554986615 P7_BalSwCell40 "电池包7的电芯40均衡状态";
CM_ SG_ 2555052151 P7_CellVoltage41 "电池包7的单体电压41";
CM_ SG_ 2555052151 P7_CellVoltage42 "电池包7的单体电压42";
CM_ SG_ 2555052151 P7_CellVoltage43 "电池包7的单体电压43";
CM_ SG_ 2555052151 P7_CellVoltage44 "电池包7的单体电压44";
CM_ SG_ 2555052151 P7_BalSwCell41 "电池包7的电芯41均衡状态";
CM_ SG_ 2555052151 P7_BalSwCell42 "电池包7的电芯42均衡状态";
CM_ SG_ 2555052151 P7_BalSwCell43 "电池包7的电芯43均衡状态";
CM_ SG_ 2555052151 P7_BalSwCell44 "电池包7的电芯44均衡状态";
CM_ SG_ 2555117687 P7_CellVoltage45 "电池包7的单体电压45";
CM_ SG_ 2555117687 P7_CellVoltage46 "电池包7的单体电压46";
CM_ SG_ 2555117687 P7_CellVoltage47 "电池包7的单体电压47";
CM_ SG_ 2555117687 P7_CellVoltage48 "电池包7的单体电压48";
CM_ SG_ 2555117687 P7_BalSwCell45 "电池包7的电芯45均衡状态";
CM_ SG_ 2555117687 P7_BalSwCell46 "电池包7的电芯46均衡状态";
CM_ SG_ 2555117687 P7_BalSwCell47 "电池包7的电芯47均衡状态";
CM_ SG_ 2555117687 P7_BalSwCell48 "电池包7的电芯48均衡状态";
CM_ SG_ 2555183223 P7_CellVoltage49 "电池包7的单体电压49";
CM_ SG_ 2555183223 P7_CellVoltage50 "电池包7的单体电压50";
CM_ SG_ 2555183223 P7_CellVoltage51 "电池包7的单体电压51";
CM_ SG_ 2555183223 P7_CellVoltage52 "电池包7的单体电压52";
CM_ SG_ 2555183223 P7_BalSwCell49 "电池包7的电芯49均衡状态";
CM_ SG_ 2555183223 P7_BalSwCell50 "电池包7的电芯50均衡状态";
CM_ SG_ 2555183223 P7_BalSwCell51 "电池包7的电芯51均衡状态";
CM_ SG_ 2555183223 P7_BalSwCell52 "电池包7的电芯52均衡状态";
CM_ SG_ 2555248759 P7_CellVoltage53 "电池包7的单体电压53";
CM_ SG_ 2555248759 P7_CellVoltage54 "电池包7的单体电压54";
CM_ SG_ 2555248759 P7_CellVoltage55 "电池包7的单体电压55";
CM_ SG_ 2555248759 P7_CellVoltage56 "电池包7的单体电压56";
CM_ SG_ 2555248759 P7_BalSwCell53 "电池包7的电芯53均衡状态";
CM_ SG_ 2555248759 P7_BalSwCell54 "电池包7的电芯54均衡状态";
CM_ SG_ 2555248759 P7_BalSwCell55 "电池包7的电芯55均衡状态";
CM_ SG_ 2555248759 P7_BalSwCell56 "电池包7的电芯56均衡状态";
CM_ SG_ 2555314295 P7_CellVoltage57 "电池包7的单体电压57";
CM_ SG_ 2555314295 P7_CellVoltage58 "电池包7的单体电压58";
CM_ SG_ 2555314295 P7_CellVoltage59 "电池包7的单体电压59";
CM_ SG_ 2555314295 P7_CellVoltage60 "电池包7的单体电压60";
CM_ SG_ 2555314295 P7_BalSwCell57 "电池包7的电芯57均衡状态";
CM_ SG_ 2555314295 P7_BalSwCell58 "电池包7的电芯58均衡状态";
CM_ SG_ 2555314295 P7_BalSwCell59 "电池包7的电芯59均衡状态";
CM_ SG_ 2555314295 P7_BalSwCell60 "电池包7的电芯60均衡状态";
CM_ SG_ 2555379831 P7_CellVoltage61 "电池包7的单体电压61";
CM_ SG_ 2555379831 P7_CellVoltage62 "电池包7的单体电压62";
CM_ SG_ 2555379831 P7_CellVoltage63 "电池包7的单体电压63";
CM_ SG_ 2555379831 P7_CellVoltage64 "电池包7的单体电压64";
CM_ SG_ 2555379831 P7_BalSwCell61 "电池包7的电芯61均衡状态";
CM_ SG_ 2555379831 P7_BalSwCell62 "电池包7的电芯62均衡状态";
CM_ SG_ 2555379831 P7_BalSwCell63 "电池包7的电芯63均衡状态";
CM_ SG_ 2555379831 P7_BalSwCell64 "电池包7的电芯64均衡状态";
CM_ SG_ 2555445367 P7_CellVoltage65 "电池包7的单体电压65";
CM_ SG_ 2555445367 P7_CellVoltage66 "电池包7的单体电压66";
CM_ SG_ 2555445367 P7_CellVoltage67 "电池包7的单体电压67";
CM_ SG_ 2555445367 P7_CellVoltage68 "电池包7的单体电压68";
CM_ SG_ 2555445367 P7_BalSwCell65 "电池包7的电芯65均衡状态";
CM_ SG_ 2555445367 P7_BalSwCell66 "电池包7的电芯66均衡状态";
CM_ SG_ 2555445367 P7_BalSwCell67 "电池包7的电芯67均衡状态";
CM_ SG_ 2555445367 P7_BalSwCell68 "电池包7的电芯68均衡状态";
CM_ SG_ 2555510903 P7_CellVoltage69 "电池包7的单体电压69";
CM_ SG_ 2555510903 P7_CellVoltage70 "电池包7的单体电压70";
CM_ SG_ 2555510903 P7_CellVoltage71 "电池包7的单体电压71";
CM_ SG_ 2555510903 P7_CellVoltage72 "电池包7的单体电压72";
CM_ SG_ 2555510903 P7_BalSwCell69 "电池包7的电芯69均衡状态";
CM_ SG_ 2555510903 P7_BalSwCell70 "电池包7的电芯70均衡状态";
CM_ SG_ 2555510903 P7_BalSwCell71 "电池包7的电芯71均衡状态";
CM_ SG_ 2555510903 P7_BalSwCell72 "电池包7的电芯72均衡状态";
CM_ SG_ 2555576439 P7_CellVoltage73 "电池包7的单体电压73";
CM_ SG_ 2555576439 P7_CellVoltage74 "电池包7的单体电压74";
CM_ SG_ 2555576439 P7_CellVoltage75 "电池包7的单体电压75";
CM_ SG_ 2555576439 P7_CellVoltage76 "电池包7的单体电压76";
CM_ SG_ 2555576439 P7_BalSwCell73 "电池包7的电芯73均衡状态";
CM_ SG_ 2555576439 P7_BalSwCell74 "电池包7的电芯74均衡状态";
CM_ SG_ 2555576439 P7_BalSwCell75 "电池包7的电芯75均衡状态";
CM_ SG_ 2555576439 P7_BalSwCell76 "电池包7的电芯76均衡状态";
CM_ SG_ 2555641975 P7_CellVoltage77 "电池包7的单体电压77";
CM_ SG_ 2555641975 P7_CellVoltage78 "电池包7的单体电压78";
CM_ SG_ 2555641975 P7_CellVoltage79 "电池包7的单体电压79";
CM_ SG_ 2555641975 P7_CellVoltage80 "电池包7的单体电压80";
CM_ SG_ 2555641975 P7_BalSwCell77 "电池包7的电芯77均衡状态";
CM_ SG_ 2555641975 P7_BalSwCell78 "电池包7的电芯78均衡状态";
CM_ SG_ 2555641975 P7_BalSwCell79 "电池包7的电芯79均衡状态";
CM_ SG_ 2555641975 P7_BalSwCell80 "电池包7的电芯80均衡状态";
CM_ SG_ 2555707511 P7_CellVoltage81 "电池包7的单体电压81";
CM_ SG_ 2555707511 P7_CellVoltage82 "电池包7的单体电压82";
CM_ SG_ 2555707511 P7_CellVoltage83 "电池包7的单体电压83";
CM_ SG_ 2555707511 P7_CellVoltage84 "电池包7的单体电压84";
CM_ SG_ 2555707511 P7_BalSwCell81 "电池包7的电芯81均衡状态";
CM_ SG_ 2555707511 P7_BalSwCell82 "电池包7的电芯82均衡状态";
CM_ SG_ 2555707511 P7_BalSwCell83 "电池包7的电芯83均衡状态";
CM_ SG_ 2555707511 P7_BalSwCell84 "电池包7的电芯84均衡状态";
CM_ SG_ 2555773047 P7_CellVoltage85 "电池包7的单体电压85";
CM_ SG_ 2555773047 P7_CellVoltage86 "电池包7的单体电压86";
CM_ SG_ 2555773047 P7_CellVoltage87 "电池包7的单体电压87";
CM_ SG_ 2555773047 P7_CellVoltage88 "电池包7的单体电压88";
CM_ SG_ 2555773047 P7_BalSwCell85 "电池包7的电芯85均衡状态";
CM_ SG_ 2555773047 P7_BalSwCell86 "电池包7的电芯86均衡状态";
CM_ SG_ 2555773047 P7_BalSwCell87 "电池包7的电芯87均衡状态";
CM_ SG_ 2555773047 P7_BalSwCell88 "电池包7的电芯88均衡状态";
CM_ SG_ 2555838583 P7_CellVoltage89 "电池包7的单体电压89";
CM_ SG_ 2555838583 P7_CellVoltage90 "电池包7的单体电压90";
CM_ SG_ 2555838583 P7_CellVoltage91 "电池包7的单体电压91";
CM_ SG_ 2555838583 P7_CellVoltage92 "电池包7的单体电压92";
CM_ SG_ 2555838583 P7_BalSwCell89 "电池包7的电芯89均衡状态";
CM_ SG_ 2555838583 P7_BalSwCell90 "电池包7的电芯90均衡状态";
CM_ SG_ 2555838583 P7_BalSwCell91 "电池包7的电芯91均衡状态";
CM_ SG_ 2555838583 P7_BalSwCell92 "电池包7的电芯92均衡状态";
CM_ SG_ 2555904119 P7_CellVoltage93 "电池包7的单体电压93";
CM_ SG_ 2555904119 P7_CellVoltage94 "电池包7的单体电压94";
CM_ SG_ 2555904119 P7_CellVoltage95 "电池包7的单体电压95";
CM_ SG_ 2555904119 P7_CellVoltage96 "电池包7的单体电压96";
CM_ SG_ 2555904119 P7_BalSwCell93 "电池包7的电芯93均衡状态";
CM_ SG_ 2555904119 P7_BalSwCell94 "电池包7的电芯94均衡状态";
CM_ SG_ 2555904119 P7_BalSwCell95 "电池包7的电芯95均衡状态";
CM_ SG_ 2555904119 P7_BalSwCell96 "电池包7的电芯96均衡状态";
CM_ SG_ 2555969655 P7_CellVoltage97 "电池包7的单体电压97";
CM_ SG_ 2555969655 P7_CellVoltage98 "电池包7的单体电压98";
CM_ SG_ 2555969655 P7_CellVoltage99 "电池包7的单体电压99";
CM_ SG_ 2555969655 P7_CellVoltage100 "电池包7的单体电压100";
CM_ SG_ 2555969655 P7_BalSwCell97 "电池包7的电芯97均衡状态";
CM_ SG_ 2555969655 P7_BalSwCell98 "电池包7的电芯98均衡状态";
CM_ SG_ 2555969655 P7_BalSwCell99 "电池包7的电芯99均衡状态";
CM_ SG_ 2555969655 P7_BalSwCell100 "电池包7的电芯100均衡状态";
CM_ SG_ 2556035191 P7_CellVoltage101 "电池包7的单体电压101";
CM_ SG_ 2556035191 P7_CellVoltage102 "电池包7的单体电压102";
CM_ SG_ 2556035191 P7_CellVoltage103 "电池包7的单体电压103";
CM_ SG_ 2556035191 P7_CellVoltage104 "电池包7的单体电压104";
CM_ SG_ 2556035191 P7_BalSwCell101 "电池包7的电芯101均衡状态";
CM_ SG_ 2556035191 P7_BalSwCell102 "电池包7的电芯102均衡状态";
CM_ SG_ 2556035191 P7_BalSwCell103 "电池包7的电芯103均衡状态";
CM_ SG_ 2556035191 P7_BalSwCell104 "电池包7的电芯104均衡状态";
CM_ SG_ 2556100727 P7_CellVoltage105 "电池包7的单体电压105";
CM_ SG_ 2556100727 P7_CellVoltage106 "电池包7的单体电压106";
CM_ SG_ 2556100727 P7_CellVoltage107 "电池包7的单体电压107";
CM_ SG_ 2556100727 P7_CellVoltage108 "电池包7的单体电压108";
CM_ SG_ 2556100727 P7_BalSwCell105 "电池包7的电芯105均衡状态";
CM_ SG_ 2556100727 P7_BalSwCell106 "电池包7的电芯106均衡状态";
CM_ SG_ 2556100727 P7_BalSwCell107 "电池包7的电芯107均衡状态";
CM_ SG_ 2556100727 P7_BalSwCell108 "电池包7的电芯108均衡状态";
CM_ SG_ 2556166263 P7_CellVoltage109 "电池包7的单体电压109";
CM_ SG_ 2556166263 P7_CellVoltage110 "电池包7的单体电压110";
CM_ SG_ 2556166263 P7_CellVoltage111 "电池包7的单体电压111";
CM_ SG_ 2556166263 P7_CellVoltage112 "电池包7的单体电压112";
CM_ SG_ 2556166263 P7_BalSwCell109 "电池包7的电芯109均衡状态";
CM_ SG_ 2556166263 P7_BalSwCell110 "电池包7的电芯110均衡状态";
CM_ SG_ 2556166263 P7_BalSwCell111 "电池包7的电芯111均衡状态";
CM_ SG_ 2556166263 P7_BalSwCell112 "电池包7的电芯112均衡状态";
CM_ SG_ 2556231799 P7_CellVoltage113 "电池包7的单体电压113";
CM_ SG_ 2556231799 P7_CellVoltage114 "电池包7的单体电压114";
CM_ SG_ 2556231799 P7_CellVoltage115 "电池包7的单体电压115";
CM_ SG_ 2556231799 P7_CellVoltage116 "电池包7的单体电压116";
CM_ SG_ 2556231799 P7_BalSwCell113 "电池包7的电芯113均衡状态";
CM_ SG_ 2556231799 P7_BalSwCell114 "电池包7的电芯114均衡状态";
CM_ SG_ 2556231799 P7_BalSwCell115 "电池包7的电芯115均衡状态";
CM_ SG_ 2556231799 P7_BalSwCell116 "电池包7的电芯116均衡状态";
CM_ SG_ 2556297335 P7_CellVoltage117 "电池包7的单体电压117";
CM_ SG_ 2556297335 P7_CellVoltage118 "电池包7的单体电压118";
CM_ SG_ 2556297335 P7_CellVoltage119 "电池包7的单体电压119";
CM_ SG_ 2556297335 P7_CellVoltage120 "电池包7的单体电压120";
CM_ SG_ 2556297335 P7_BalSwCell117 "电池包7的电芯117均衡状态";
CM_ SG_ 2556297335 P7_BalSwCell118 "电池包7的电芯118均衡状态";
CM_ SG_ 2556297335 P7_BalSwCell119 "电池包7的电芯119均衡状态";
CM_ SG_ 2556297335 P7_BalSwCell120 "电池包7的电芯120均衡状态";
CM_ SG_ 2556362871 P7_CellVoltage121 "电池包7的单体电压121";
CM_ SG_ 2556362871 P7_CellVoltage122 "电池包7的单体电压122";
CM_ SG_ 2556362871 P7_CellVoltage123 "电池包7的单体电压123";
CM_ SG_ 2556362871 P7_CellVoltage124 "电池包7的单体电压124";
CM_ SG_ 2556362871 P7_BalSwCell121 "电池包7的电芯121均衡状态";
CM_ SG_ 2556362871 P7_BalSwCell122 "电池包7的电芯122均衡状态";
CM_ SG_ 2556362871 P7_BalSwCell123 "电池包7的电芯123均衡状态";
CM_ SG_ 2556362871 P7_BalSwCell124 "电池包7的电芯124均衡状态";
CM_ SG_ 2556428407 P7_CellVoltage125 "电池包7的单体电压125";
CM_ SG_ 2556428407 P7_CellVoltage126 "电池包7的单体电压126";
CM_ SG_ 2556428407 P7_CellVoltage127 "电池包7的单体电压127";
CM_ SG_ 2556428407 P7_CellVoltage128 "电池包7的单体电压128";
CM_ SG_ 2556428407 P7_BalSwCell125 "电池包7的电芯125均衡状态";
CM_ SG_ 2556428407 P7_BalSwCell126 "电池包7的电芯126均衡状态";
CM_ SG_ 2556428407 P7_BalSwCell127 "电池包7的电芯127均衡状态";
CM_ SG_ 2556428407 P7_BalSwCell128 "电池包7的电芯128均衡状态";
CM_ SG_ 2556493943 P7_CellVoltage129 "电池包7的单体电压129";
CM_ SG_ 2556493943 P7_CellVoltage130 "电池包7的单体电压130";
CM_ SG_ 2556493943 P7_CellVoltage131 "电池包7的单体电压131";
CM_ SG_ 2556493943 P7_CellVoltage132 "电池包7的单体电压132";
CM_ SG_ 2556493943 P7_BalSwCell129 "电池包7的电芯129均衡状态";
CM_ SG_ 2556493943 P7_BalSwCell130 "电池包7的电芯130均衡状态";
CM_ SG_ 2556493943 P7_BalSwCell131 "电池包7的电芯131均衡状态";
CM_ SG_ 2556493943 P7_BalSwCell132 "电池包7的电芯132均衡状态";
CM_ SG_ 2556559479 P7_CellVoltage133 "电池包7的单体电压133";
CM_ SG_ 2556559479 P7_CellVoltage134 "电池包7的单体电压134";
CM_ SG_ 2556559479 P7_CellVoltage135 "电池包7的单体电压135";
CM_ SG_ 2556559479 P7_CellVoltage136 "电池包7的单体电压136";
CM_ SG_ 2556559479 P7_BalSwCell133 "电池包7的电芯133均衡状态";
CM_ SG_ 2556559479 P7_BalSwCell134 "电池包7的电芯134均衡状态";
CM_ SG_ 2556559479 P7_BalSwCell135 "电池包7的电芯135均衡状态";
CM_ SG_ 2556559479 P7_BalSwCell136 "电池包7的电芯136均衡状态";
CM_ SG_ 2556625015 P7_CellVoltage137 "电池包7的单体电压137";
CM_ SG_ 2556625015 P7_CellVoltage138 "电池包7的单体电压138";
CM_ SG_ 2556625015 P7_CellVoltage139 "电池包7的单体电压139";
CM_ SG_ 2556625015 P7_CellVoltage140 "电池包7的单体电压140";
CM_ SG_ 2556625015 P7_BalSwCell137 "电池包7的电芯137均衡状态";
CM_ SG_ 2556625015 P7_BalSwCell138 "电池包7的电芯138均衡状态";
CM_ SG_ 2556625015 P7_BalSwCell139 "电池包7的电芯139均衡状态";
CM_ SG_ 2556625015 P7_BalSwCell140 "电池包7的电芯140均衡状态";
CM_ SG_ 2556690551 P7_CellVoltage141 "电池包7的单体电压141";
CM_ SG_ 2556690551 P7_CellVoltage142 "电池包7的单体电压142";
CM_ SG_ 2556690551 P7_CellVoltage143 "电池包7的单体电压143";
CM_ SG_ 2556690551 P7_CellVoltage144 "电池包7的单体电压144";
CM_ SG_ 2556690551 P7_BalSwCell141 "电池包7的电芯141均衡状态";
CM_ SG_ 2556690551 P7_BalSwCell142 "电池包7的电芯142均衡状态";
CM_ SG_ 2556690551 P7_BalSwCell143 "电池包7的电芯143均衡状态";
CM_ SG_ 2556690551 P7_BalSwCell144 "电池包7的电芯144均衡状态";
CM_ SG_ 2556756087 P7_CellVoltage145 "电池包7的单体电压145";
CM_ SG_ 2556756087 P7_CellVoltage146 "电池包7的单体电压146";
CM_ SG_ 2556756087 P7_CellVoltage147 "电池包7的单体电压147";
CM_ SG_ 2556756087 P7_CellVoltage148 "电池包7的单体电压148";
CM_ SG_ 2556756087 P7_BalSwCell145 "电池包7的电芯145均衡状态";
CM_ SG_ 2556756087 P7_BalSwCell146 "电池包7的电芯146均衡状态";
CM_ SG_ 2556756087 P7_BalSwCell147 "电池包7的电芯147均衡状态";
CM_ SG_ 2556756087 P7_BalSwCell148 "电池包7的电芯148均衡状态";
CM_ SG_ 2556821623 P7_CellVoltage149 "电池包7的单体电压149";
CM_ SG_ 2556821623 P7_CellVoltage150 "电池包7的单体电压150";
CM_ SG_ 2556821623 P7_CellVoltage151 "电池包7的单体电压151";
CM_ SG_ 2556821623 P7_CellVoltage152 "电池包7的单体电压152";
CM_ SG_ 2556821623 P7_BalSwCell149 "电池包7的电芯149均衡状态";
CM_ SG_ 2556821623 P7_BalSwCell150 "电池包7的电芯150均衡状态";
CM_ SG_ 2556821623 P7_BalSwCell151 "电池包7的电芯151均衡状态";
CM_ SG_ 2556821623 P7_BalSwCell152 "电池包7的电芯152均衡状态";
CM_ SG_ 2556887159 P7_CellVoltage153 "电池包7的单体电压153";
CM_ SG_ 2556887159 P7_CellVoltage154 "电池包7的单体电压154";
CM_ SG_ 2556887159 P7_CellVoltage155 "电池包7的单体电压155";
CM_ SG_ 2556887159 P7_CellVoltage156 "电池包7的单体电压156";
CM_ SG_ 2556887159 P7_BalSwCell153 "电池包7的电芯153均衡状态";
CM_ SG_ 2556887159 P7_BalSwCell154 "电池包7的电芯154均衡状态";
CM_ SG_ 2556887159 P7_BalSwCell155 "电池包7的电芯155均衡状态";
CM_ SG_ 2556887159 P7_BalSwCell156 "电池包7的电芯156均衡状态";
CM_ SG_ 2556952695 P7_CellVoltage157 "电池包7的单体电压157";
CM_ SG_ 2556952695 P7_CellVoltage158 "电池包7的单体电压158";
CM_ SG_ 2556952695 P7_CellVoltage159 "电池包7的单体电压159";
CM_ SG_ 2556952695 P7_CellVoltage160 "电池包7的单体电压160";
CM_ SG_ 2556952695 P7_BalSwCell157 "电池包7的电芯157均衡状态";
CM_ SG_ 2556952695 P7_BalSwCell158 "电池包7的电芯158均衡状态";
CM_ SG_ 2556952695 P7_BalSwCell159 "电池包7的电芯159均衡状态";
CM_ SG_ 2556952695 P7_BalSwCell160 "电池包7的电芯160均衡状态";
CM_ SG_ 2557018231 P7_CellVoltage161 "电池包7的单体电压161";
CM_ SG_ 2557018231 P7_CellVoltage162 "电池包7的单体电压162";
CM_ SG_ 2557018231 P7_CellVoltage163 "电池包7的单体电压163";
CM_ SG_ 2557018231 P7_CellVoltage164 "电池包7的单体电压164";
CM_ SG_ 2557018231 P7_BalSwCell161 "电池包7的电芯161均衡状态";
CM_ SG_ 2557018231 P7_BalSwCell162 "电池包7的电芯162均衡状态";
CM_ SG_ 2557018231 P7_BalSwCell163 "电池包7的电芯163均衡状态";
CM_ SG_ 2557018231 P7_BalSwCell164 "电池包7的电芯164均衡状态";
CM_ SG_ 2557083767 P7_CellVoltage165 "电池包7的单体电压165";
CM_ SG_ 2557083767 P7_CellVoltage166 "电池包7的单体电压166";
CM_ SG_ 2557083767 P7_CellVoltage167 "电池包7的单体电压167";
CM_ SG_ 2557083767 P7_CellVoltage168 "电池包7的单体电压168";
CM_ SG_ 2557083767 P7_BalSwCell165 "电池包7的电芯165均衡状态";
CM_ SG_ 2557083767 P7_BalSwCell166 "电池包7的电芯166均衡状态";
CM_ SG_ 2557083767 P7_BalSwCell167 "电池包7的电芯167均衡状态";
CM_ SG_ 2557083767 P7_BalSwCell168 "电池包7的电芯168均衡状态";
CM_ SG_ 2557149303 P7_CellVoltage169 "电池包7的单体电压169";
CM_ SG_ 2557149303 P7_CellVoltage170 "电池包7的单体电压170";
CM_ SG_ 2557149303 P7_CellVoltage171 "电池包7的单体电压171";
CM_ SG_ 2557149303 P7_CellVoltage172 "电池包7的单体电压172";
CM_ SG_ 2557149303 P7_BalSwCell169 "电池包7的电芯169均衡状态";
CM_ SG_ 2557149303 P7_BalSwCell170 "电池包7的电芯170均衡状态";
CM_ SG_ 2557149303 P7_BalSwCell171 "电池包7的电芯171均衡状态";
CM_ SG_ 2557149303 P7_BalSwCell172 "电池包7的电芯172均衡状态";
CM_ SG_ 2557214839 P7_CellVoltage173 "电池包7的单体电压173";
CM_ SG_ 2557214839 P7_CellVoltage174 "电池包7的单体电压174";
CM_ SG_ 2557214839 P7_CellVoltage175 "电池包7的单体电压175";
CM_ SG_ 2557214839 P7_CellVoltage176 "电池包7的单体电压176";
CM_ SG_ 2557214839 P7_BalSwCell173 "电池包7的电芯173均衡状态";
CM_ SG_ 2557214839 P7_BalSwCell174 "电池包7的电芯174均衡状态";
CM_ SG_ 2557214839 P7_BalSwCell175 "电池包7的电芯175均衡状态";
CM_ SG_ 2557214839 P7_BalSwCell176 "电池包7的电芯176均衡状态";
CM_ SG_ 2557280375 P7_CellVoltage177 "电池包7的单体电压177";
CM_ SG_ 2557280375 P7_CellVoltage178 "电池包7的单体电压178";
CM_ SG_ 2557280375 P7_CellVoltage179 "电池包7的单体电压179";
CM_ SG_ 2557280375 P7_CellVoltage180 "电池包7的单体电压180";
CM_ SG_ 2557280375 P7_BalSwCell177 "电池包7的电芯177均衡状态";
CM_ SG_ 2557280375 P7_BalSwCell178 "电池包7的电芯178均衡状态";
CM_ SG_ 2557280375 P7_BalSwCell179 "电池包7的电芯179均衡状态";
CM_ SG_ 2557280375 P7_BalSwCell180 "电池包7的电芯180均衡状态";
CM_ SG_ 2557345911 P7_CellVoltage181 "电池包7的单体电压181";
CM_ SG_ 2557345911 P7_CellVoltage182 "电池包7的单体电压182";
CM_ SG_ 2557345911 P7_CellVoltage183 "电池包7的单体电压183";
CM_ SG_ 2557345911 P7_CellVoltage184 "电池包7的单体电压184";
CM_ SG_ 2557345911 P7_BalSwCell181 "电池包7的电芯181均衡状态";
CM_ SG_ 2557345911 P7_BalSwCell182 "电池包7的电芯182均衡状态";
CM_ SG_ 2557345911 P7_BalSwCell183 "电池包7的电芯183均衡状态";
CM_ SG_ 2557345911 P7_BalSwCell184 "电池包7的电芯184均衡状态";
CM_ SG_ 2557411447 P7_CellVoltage185 "电池包7的单体电压185";
CM_ SG_ 2557411447 P7_CellVoltage186 "电池包7的单体电压186";
CM_ SG_ 2557411447 P7_CellVoltage187 "电池包7的单体电压187";
CM_ SG_ 2557411447 P7_CellVoltage188 "电池包7的单体电压188";
CM_ SG_ 2557411447 P7_BalSwCell185 "电池包7的电芯185均衡状态";
CM_ SG_ 2557411447 P7_BalSwCell186 "电池包7的电芯186均衡状态";
CM_ SG_ 2557411447 P7_BalSwCell187 "电池包7的电芯187均衡状态";
CM_ SG_ 2557411447 P7_BalSwCell188 "电池包7的电芯188均衡状态";
CM_ SG_ 2557476983 P7_CellVoltage189 "电池包7的单体电压189";
CM_ SG_ 2557476983 P7_CellVoltage190 "电池包7的单体电压190";
CM_ SG_ 2557476983 P7_CellVoltage191 "电池包7的单体电压191";
CM_ SG_ 2557476983 P7_CellVoltage192 "电池包7的单体电压192";
CM_ SG_ 2557476983 P7_BalSwCell189 "电池包7的电芯189均衡状态";
CM_ SG_ 2557476983 P7_BalSwCell190 "电池包7的电芯190均衡状态";
CM_ SG_ 2557476983 P7_BalSwCell191 "电池包7的电芯191均衡状态";
CM_ SG_ 2557476983 P7_BalSwCell192 "电池包7的电芯192均衡状态";
CM_ SG_ 2558525559 P7_CellTemp1 "电池包7的单体温度1";
CM_ SG_ 2558525559 P7_CellTemp2 "电池包7的单体温度2";
CM_ SG_ 2558525559 P7_CellTemp3 "电池包7的单体温度3";
CM_ SG_ 2558525559 P7_CellTemp4 "电池包7的单体温度4";
CM_ SG_ 2558525559 P7_CellTemp5 "电池包7的单体温度5";
CM_ SG_ 2558591095 P7_CellTemp6 "电池包7的单体温度6";
CM_ SG_ 2558591095 P7_CellTemp7 "电池包7的单体温度7";
CM_ SG_ 2558591095 P7_CellTemp8 "电池包7的单体温度8";
CM_ SG_ 2558591095 P7_CellTemp9 "电池包7的单体温度9";
CM_ SG_ 2558591095 P7_CellTemp10 "电池包7的单体温度10";
CM_ SG_ 2558656631 P7_CellTemp11 "电池包7的单体温度11";
CM_ SG_ 2558656631 P7_CellTemp12 "电池包7的单体温度12";
CM_ SG_ 2558656631 P7_CellTemp13 "电池包7的单体温度13";
CM_ SG_ 2558656631 P7_CellTemp14 "电池包7的单体温度14";
CM_ SG_ 2558656631 P7_CellTemp15 "电池包7的单体温度15";
CM_ SG_ 2558722167 P7_CellTemp16 "电池包7的单体温度16";
CM_ SG_ 2558722167 P7_CellTemp17 "电池包7的单体温度17";
CM_ SG_ 2558722167 P7_CellTemp18 "电池包7的单体温度18";
CM_ SG_ 2558722167 P7_CellTemp19 "电池包7的单体温度19";
CM_ SG_ 2558722167 P7_CellTemp20 "电池包7的单体温度20";
CM_ SG_ 2558787703 P7_CellTemp21 "电池包7的单体温度21";
CM_ SG_ 2558787703 P7_CellTemp22 "电池包7的单体温度22";
CM_ SG_ 2558787703 P7_CellTemp23 "电池包7的单体温度23";
CM_ SG_ 2558787703 P7_CellTemp24 "电池包7的单体温度24";
CM_ SG_ 2558787703 P7_CellTemp25 "电池包7的单体温度25";
CM_ SG_ 2558853239 P7_CellTemp26 "电池包7的单体温度26";
CM_ SG_ 2558853239 P7_CellTemp27 "电池包7的单体温度27";
CM_ SG_ 2558853239 P7_CellTemp28 "电池包7的单体温度28";
CM_ SG_ 2558853239 P7_CellTemp29 "电池包7的单体温度29";
CM_ SG_ 2558853239 P7_CellTemp30 "电池包7的单体温度30";
CM_ SG_ 2558918775 P7_CellTemp31 "电池包7的单体温度31";
CM_ SG_ 2558918775 P7_CellTemp32 "电池包7的单体温度32";
CM_ SG_ 2558918775 P7_CellTemp33 "电池包7的单体温度33";
CM_ SG_ 2558918775 P7_CellTemp34 "电池包7的单体温度34";
CM_ SG_ 2558918775 P7_CellTemp35 "电池包7的单体温度35";
CM_ SG_ 2558984311 P7_CellTemp36 "电池包7的单体温度36";
CM_ SG_ 2558984311 P7_CellTemp37 "电池包7的单体温度37";
CM_ SG_ 2558984311 P7_CellTemp38 "电池包7的单体温度38";
CM_ SG_ 2558984311 P7_CellTemp39 "电池包7的单体温度39";
CM_ SG_ 2558984311 P7_CellTemp40 "电池包7的单体温度40";
CM_ SG_ 2559049847 P7_CellTemp41 "电池包7的单体温度41";
CM_ SG_ 2559049847 P7_CellTemp42 "电池包7的单体温度42";
CM_ SG_ 2559049847 P7_CellTemp43 "电池包7的单体温度43";
CM_ SG_ 2559049847 P7_CellTemp44 "电池包7的单体温度44";
CM_ SG_ 2559049847 P7_CellTemp45 "电池包7的单体温度45";
CM_ SG_ 2559115383 P7_CellTemp46 "电池包7的单体温度46";
CM_ SG_ 2559115383 P7_CellTemp47 "电池包7的单体温度47";
CM_ SG_ 2559115383 P7_CellTemp48 "电池包7的单体温度48";
CM_ SG_ 2559115383 P7_CellTemp49 "电池包7的单体温度49";
CM_ SG_ 2559115383 P7_CellTemp50 "电池包7的单体温度50";
CM_ SG_ 2559180919 P7_CellTemp51 "电池包7的单体温度51";
CM_ SG_ 2559180919 P7_CellTemp52 "电池包7的单体温度52";
CM_ SG_ 2559180919 P7_CellTemp53 "电池包7的单体温度53";
CM_ SG_ 2559180919 P7_CellTemp54 "电池包7的单体温度54";
CM_ SG_ 2559180919 P7_CellTemp55 "电池包7的单体温度55";
CM_ SG_ 2559246455 P7_CellTemp56 "电池包7的单体温度56";
CM_ SG_ 2559246455 P7_CellTemp57 "电池包7的单体温度57";
CM_ SG_ 2559246455 P7_CellTemp58 "电池包7的单体温度58";
CM_ SG_ 2559246455 P7_CellTemp59 "电池包7的单体温度59";
CM_ SG_ 2559246455 P7_CellTemp60 "电池包7的单体温度60";
CM_ SG_ 2559311991 P7_CellTemp61 "电池包7的单体温度61";
CM_ SG_ 2559311991 P7_CellTemp62 "电池包7的单体温度62";
CM_ SG_ 2559311991 P7_CellTemp63 "电池包7的单体温度63";
CM_ SG_ 2559311991 P7_CellTemp64 "电池包7的单体温度64";
CM_ SG_ 2559311991 P7_CellTemp65 "电池包7的单体温度65";
CM_ SG_ 2559377527 P7_CellTemp66 "电池包7的单体温度66";
CM_ SG_ 2559377527 P7_CellTemp67 "电池包7的单体温度67";
CM_ SG_ 2559377527 P7_CellTemp68 "电池包7的单体温度68";
CM_ SG_ 2559377527 P7_CellTemp69 "电池包7的单体温度69";
CM_ SG_ 2559377527 P7_CellTemp70 "电池包7的单体温度70";
CM_ SG_ 2559443063 P7_CellTemp71 "电池包7的单体温度71";
CM_ SG_ 2559443063 P7_CellTemp72 "电池包7的单体温度72";
CM_ SG_ 2559443063 P7_CellTemp73 "电池包7的单体温度73";
CM_ SG_ 2559443063 P7_CellTemp74 "电池包7的单体温度74";
CM_ SG_ 2559443063 P7_CellTemp75 "电池包7的单体温度75";
CM_ SG_ 2559508599 P7_CellTemp76 "电池包7的单体温度76";
CM_ SG_ 2559508599 P7_CellTemp77 "电池包7的单体温度77";
CM_ SG_ 2559508599 P7_CellTemp78 "电池包7的单体温度78";
CM_ SG_ 2559508599 P7_CellTemp79 "电池包7的单体温度79";
CM_ SG_ 2559508599 P7_CellTemp80 "电池包7的单体温度80";
CM_ SG_ 2559574135 P7_CellTemp81 "电池包7的单体温度81";
CM_ SG_ 2559574135 P7_CellTemp82 "电池包7的单体温度82";
CM_ SG_ 2559574135 P7_CellTemp83 "电池包7的单体温度83";
CM_ SG_ 2559574135 P7_CellTemp84 "电池包7的单体温度84";
CM_ SG_ 2559574135 P7_CellTemp85 "电池包7的单体温度85";
CM_ SG_ 2559639671 P7_CellTemp86 "电池包7的单体温度86";
CM_ SG_ 2559639671 P7_CellTemp87 "电池包7的单体温度87";
CM_ SG_ 2559639671 P7_CellTemp88 "电池包7的单体温度88";
CM_ SG_ 2559639671 P7_CellTemp89 "电池包7的单体温度89";
CM_ SG_ 2559639671 P7_CellTemp90 "电池包7的单体温度90";
CM_ SG_ 2559705207 P7_CellTemp91 "电池包7的单体温度91";
CM_ SG_ 2559705207 P7_CellTemp92 "电池包7的单体温度92";
CM_ SG_ 2559705207 P7_CellTemp93 "电池包7的单体温度93";
CM_ SG_ 2559705207 P7_CellTemp94 "电池包7的单体温度94";
CM_ SG_ 2559705207 P7_CellTemp95 "电池包7的单体温度95";
CM_ SG_ 2559770743 P7_CellTemp96 "电池包7的单体温度96";
CM_ SG_ 2559770743 P7_CellTemp97 "电池包7的单体温度97";
CM_ SG_ 2559770743 P7_CellTemp98 "电池包7的单体温度98";
CM_ SG_ 2559770743 P7_CellTemp99 "电池包7的单体温度99";
CM_ SG_ 2559770743 P7_CellTemp100 "电池包7的单体温度100";
CM_ SG_ 2559836279 P7_CellTemp101 "电池包7的单体温度101";
CM_ SG_ 2559836279 P7_CellTemp102 "电池包7的单体温度102";
CM_ SG_ 2559836279 P7_CellTemp103 "电池包7的单体温度103";
CM_ SG_ 2559836279 P7_CellTemp104 "电池包7的单体温度104";
CM_ SG_ 2559836279 P7_CellTemp105 "电池包7的单体温度105";
CM_ SG_ 2559901815 P7_CellTemp106 "电池包7的单体温度106";
CM_ SG_ 2559901815 P7_CellTemp107 "电池包7的单体温度107";
CM_ SG_ 2559901815 P7_CellTemp108 "电池包7的单体温度108";
CM_ SG_ 2559901815 P7_CellTemp109 "电池包7的单体温度109";
CM_ SG_ 2559901815 P7_CellTemp110 "电池包7的单体温度110";
CM_ SG_ 2559967351 P7_CellTemp111 "电池包7的单体温度111";
CM_ SG_ 2559967351 P7_CellTemp112 "电池包7的单体温度112";
CM_ SG_ 2559967351 P7_CellTemp113 "电池包7的单体温度113";
CM_ SG_ 2559967351 P7_CellTemp114 "电池包7的单体温度114";
CM_ SG_ 2559967351 P7_CellTemp115 "电池包7的单体温度115";
CM_ SG_ 2560032887 P7_CellTemp116 "电池包7的单体温度116";
CM_ SG_ 2560032887 P7_CellTemp117 "电池包7的单体温度117";
CM_ SG_ 2560032887 P7_CellTemp118 "电池包7的单体温度118";
CM_ SG_ 2560032887 P7_CellTemp119 "电池包7的单体温度119";
CM_ SG_ 2560032887 P7_CellTemp120 "电池包7的单体温度120";
CM_ SG_ 2560098423 P7_CellTemp121 "电池包7的单体温度121";
CM_ SG_ 2560098423 P7_CellTemp122 "电池包7的单体温度122";
CM_ SG_ 2560098423 P7_CellTemp123 "电池包7的单体温度123";
CM_ SG_ 2560098423 P7_CellTemp124 "电池包7的单体温度124";
CM_ SG_ 2560098423 P7_CellTemp125 "电池包7的单体温度125";
CM_ SG_ 2560163959 P7_CellTemp126 "电池包7的单体温度126";
CM_ SG_ 2560163959 P7_CellTemp127 "电池包7的单体温度127";
CM_ SG_ 2560163959 P7_CellTemp128 "电池包7的单体温度128";
CM_ SG_ 2560163959 P7_CellTemp129 "电池包7的单体温度129";
CM_ SG_ 2560163959 P7_CellTemp130 "电池包7的单体温度130";
CM_ SG_ 2560229495 P7_CellTemp131 "电池包7的单体温度131";
CM_ SG_ 2560229495 P7_CellTemp132 "电池包7的单体温度132";
CM_ SG_ 2560229495 P7_CellTemp133 "电池包7的单体温度133";
CM_ SG_ 2560229495 P7_CellTemp134 "电池包7的单体温度134";
CM_ SG_ 2560229495 P7_CellTemp135 "电池包7的单体温度135";
CM_ SG_ 2560295031 P7_CellTemp136 "电池包7的单体温度136";
CM_ SG_ 2560295031 P7_CellTemp137 "电池包7的单体温度137";
CM_ SG_ 2560295031 P7_CellTemp138 "电池包7的单体温度138";
CM_ SG_ 2560295031 P7_CellTemp139 "电池包7的单体温度139";
CM_ SG_ 2560295031 P7_CellTemp140 "电池包7的单体温度140";
CM_ SG_ 2560360567 P7_CellTemp141 "电池包7的单体温度141";
CM_ SG_ 2560360567 P7_CellTemp142 "电池包7的单体温度142";
CM_ SG_ 2560360567 P7_CellTemp143 "电池包7的单体温度143";
CM_ SG_ 2560360567 P7_CellTemp144 "电池包7的单体温度144";
CM_ SG_ 2560360567 P7_CellTemp145 "电池包7的单体温度145";
CM_ SG_ 2560426103 P7_CellTemp146 "电池包7的单体温度146";
CM_ SG_ 2560426103 P7_CellTemp147 "电池包7的单体温度147";
CM_ SG_ 2560426103 P7_CellTemp148 "电池包7的单体温度148";
CM_ SG_ 2560426103 P7_CellTemp149 "电池包7的单体温度149";
CM_ SG_ 2560426103 P7_CellTemp150 "电池包7的单体温度150";
CM_ SG_ 2560491639 P7_CellTemp151 "电池包7的单体温度151";
CM_ SG_ 2560491639 P7_CellTemp152 "电池包7的单体温度152";
CM_ SG_ 2560491639 P7_CellTemp153 "电池包7的单体温度153";
CM_ SG_ 2560491639 P7_CellTemp154 "电池包7的单体温度154";
CM_ SG_ 2560491639 P7_CellTemp155 "电池包7的单体温度155";
CM_ SG_ 2560557175 P7_CellTemp156 "电池包7的单体温度156";
CM_ SG_ 2560557175 P7_CellTemp157 "电池包7的单体温度157";
CM_ SG_ 2560557175 P7_CellTemp158 "电池包7的单体温度158";
CM_ SG_ 2560557175 P7_CellTemp159 "电池包7的单体温度159";
CM_ SG_ 2560557175 P7_CellTemp160 "电池包7的单体温度160";
CM_ SG_ 2560622711 P7_CellTemp161 "电池包7的单体温度161";
CM_ SG_ 2560622711 P7_CellTemp162 "电池包7的单体温度162";
CM_ SG_ 2560622711 P7_CellTemp163 "电池包7的单体温度163";
CM_ SG_ 2560622711 P7_CellTemp164 "电池包7的单体温度164";
CM_ SG_ 2560622711 P7_CellTemp165 "电池包7的单体温度165";
CM_ SG_ 2560688247 P7_CellTemp166 "电池包7的单体温度166";
CM_ SG_ 2560688247 P7_CellTemp167 "电池包7的单体温度167";
CM_ SG_ 2560688247 P7_CellTemp168 "电池包7的单体温度168";
CM_ SG_ 2560688247 P7_CellTemp169 "电池包7的单体温度169";
CM_ SG_ 2560688247 P7_CellTemp170 "电池包7的单体温度170";
CM_ SG_ 2560753783 P7_CellTemp171 "电池包7的单体温度171";
CM_ SG_ 2560753783 P7_CellTemp172 "电池包7的单体温度172";
CM_ SG_ 2560753783 P7_CellTemp173 "电池包7的单体温度173";
CM_ SG_ 2560753783 P7_CellTemp174 "电池包7的单体温度174";
CM_ SG_ 2560753783 P7_CellTemp175 "电池包7的单体温度175";
CM_ SG_ 2560819319 P7_CellTemp176 "电池包7的单体温度176";
CM_ SG_ 2560819319 P7_CellTemp177 "电池包7的单体温度177";
CM_ SG_ 2560819319 P7_CellTemp178 "电池包7的单体温度178";
CM_ SG_ 2560819319 P7_CellTemp179 "电池包7的单体温度179";
CM_ SG_ 2560819319 P7_CellTemp180 "电池包7的单体温度180";
CM_ SG_ 2560884855 P7_CellTemp181 "电池包7的单体温度181";
CM_ SG_ 2560884855 P7_CellTemp182 "电池包7的单体温度182";
CM_ SG_ 2560884855 P7_CellTemp183 "电池包7的单体温度183";
CM_ SG_ 2560884855 P7_CellTemp184 "电池包7的单体温度184";
CM_ SG_ 2560884855 P7_CellTemp185 "电池包7的单体温度185";
CM_ SG_ 2560950391 P7_CellTemp186 "电池包7的单体温度186";
CM_ SG_ 2560950391 P7_CellTemp187 "电池包7的单体温度187";
CM_ SG_ 2560950391 P7_CellTemp188 "电池包7的单体温度188";
CM_ SG_ 2560950391 P7_CellTemp189 "电池包7的单体温度189";
CM_ SG_ 2560950391 P7_CellTemp190 "电池包7的单体温度190";
CM_ SG_ 2561015927 P7_CellTemp191 "电池包7的单体温度191";
CM_ SG_ 2561015927 P7_CellTemp192 "电池包7的单体温度192";
CM_ SG_ 2561015927 P7_DatLen16DbgInfo1 "长度为16的调试信息1";
CM_ SG_ 2561015927 P7_DatLen16DbgInfo2 "长度为16的调试信息2";
CM_ SG_ 2561015927 P7_DatLen16DbgInfo3 "长度为16的调试信息3";
CM_ SG_ 2561015927 P7_DatLen16DbgInfo4 "长度为16的调试信息4";
CM_ SG_ 2550399112 P8_BMSPwrSuplVlt1 "电池包8的BMS供电电源电压1";
CM_ SG_ 2550399112 P8_BMSPwrSuplVlt2 "电池包8的BMS供电电源电压2";
CM_ SG_ 2550399112 P8_ChrgStationAuxPwrSuplVlt "电池包8的快充桩A+电压";
CM_ SG_ 2550399112 P8_BMSKL15ON "电池包8的BMS唤醒信号";
CM_ SG_ 2550399112 P8_DCStepState "电池包8的充电状态机";
CM_ SG_ 2550399112 P8_ExtLvWakeup_28VOnly "电池包8的外部唤醒";
CM_ SG_ 2550464648 P8_PackVltUprLmt "电池包8的电压使用上限";
CM_ SG_ 2550464648 P8_PackVltLoLmt "电池包8的电压使用下限";
CM_ SG_ 2550464648 P8_PackMaxDschrgCrnt "电池包8的最大允许放电电流";
CM_ SG_ 2550464648 P8_PackMaxChrgCrnt "电池包8的最大允许充电电流";
CM_ SG_ 2550530184 P8_PackDschrgPwrLmt "电池包8的放电功率限值";
CM_ SG_ 2550530184 P8_PackDschrgPwrStat "电池包8的放电功率状态";
CM_ SG_ 2550530184 P8_PackChrgPwrLmt "电池包8的充电功率限值";
CM_ SG_ 2550530184 P8_PackChrgPwrStat "电池包8的充电功率状态";
CM_ SG_ 2550595720 P8_ChrgrCplrStat "电池包8的充电枪连接状态";
CM_ SG_ 2550595720 P8_HVBattChrgSysStatus "电池包8的充电系统状态";
CM_ SG_ 2550595720 P8_DCChrgCrntCmd "电池包8的直流充电请求电流";
CM_ SG_ 2550595720 P8_CC2Vlt "电池包8的CC2电压值";
CM_ SG_ 2550595720 P8_DCRcptPosTemp "电池包8的快充充电插座正极温度";
CM_ SG_ 2550595720 P8_DCRcptNegTemp "电池包8的快充充电插座负极温度";
CM_ SG_ 2550595720 P8_Tm2FullChrg "电池包8满充剩余时间";
CM_ SG_ 2550661256 P8_Inlet1ClntTemp "进水口1冷却液温度";
CM_ SG_ 2550661256 P8_Inlet2ClntTemp "进水口2冷却液温度";
CM_ SG_ 2550661256 P8_Outlet1ClntTemp "出水口1冷却液温度";
CM_ SG_ 2550661256 P8_Outlet2ClntTemp "出水口2冷却液温度";
CM_ SG_ 2550661256 P8_TrgtClntTemp "冷却水目标温度";
CM_ SG_ 2550661256 P8_TrgtClntFlowRate "冷却水目标流量";
CM_ SG_ 2550726792 P8_MaxCellVlt "电池包8的最大单体电压";
CM_ SG_ 2550726792 P8_MaxCellVltNum "电池包8的最大单体电压编号";
CM_ SG_ 2550726792 P8_MinCellVlt "电池包8的最小单体电压";
CM_ SG_ 2550726792 P8_MinCellVltNum "电池包8的最小单体电压编号";
CM_ SG_ 2550726792 P8_AvgCellVlt "电池包8的平均单体电压";
CM_ SG_ 2550792328 P8_MaxCellTemp "电池包8的最高单体温度";
CM_ SG_ 2550792328 P8_MaxCellTempNum "电池包8的最高单体温度编号";
CM_ SG_ 2550792328 P8_MinCellTemp "电池包8的最低单体温度";
CM_ SG_ 2550792328 P8_MinCellTempNum "电池包8的最低单体温度编号";
CM_ SG_ 2550792328 P8_AvgCellTemp "电池包8的单体平均温度";
CM_ SG_ 2550857864 P8_PackTotFltNum "电池包8的电池故障总数";
CM_ SG_ 2550857864 P8_CellOverVoltage "电池包8的单体过压";
CM_ SG_ 2550857864 P8_CellUnderVoltage "电池包8的单体欠压";
CM_ SG_ 2550857864 P8_CellVoltageDiffHi "电池包8的单体压差过大";
CM_ SG_ 2550857864 P8_PackOverVoltage "电池包8的电压过高";
CM_ SG_ 2550857864 P8_PackUnderVoltage "电池包8的电压过低";
CM_ SG_ 2550857864 P8_CellOverTemp "电池包8的单体过温";
CM_ SG_ 2550857864 P8_CellTempLow "电池包8的单体温度过低";
CM_ SG_ 2550857864 P8_CellTempDiffHi "电池包8的单体温度差异过大";
CM_ SG_ 2550857864 P8_PackDschrgCrntHi "电池包8的放电电流过流";
CM_ SG_ 2550857864 P8_PackChrgCrntHi "电池包8的充电电流过流";
CM_ SG_ 2550857864 P8_PackCrnSnsr1OffsetHi "电池包8的电流传感器1零漂过大";
CM_ SG_ 2550857864 P8_HVIsolFlt "电池包8的高压绝缘故障";
CM_ SG_ 2550857864 P8_HVILFlt "电池包8的高压互锁故障";
CM_ SG_ 2550857864 P8_ThrmlRunaway "电池包8的热失控故障";
CM_ SG_ 2550857864 P8_CellVoltInvalid "电池包8的单体电压采样失效";
CM_ SG_ 2550857864 P8_CellTempInvalid "电池包8的电芯温度采样失效";
CM_ SG_ 2550857864 P8_DaisyChainComFlt "电池包8的菊花链通信故障";
CM_ SG_ 2550857864 P8_PackVoltRatFlt "电池包8的总电压与单体电压总和偏差过大";
CM_ SG_ 2550857864 P8_CrntSnsr1Invalid "电池包8的电流传感器1电流采样失效";
CM_ SG_ 2550857864 P8_CrntSnsr1OOR "电池包8的电流传感器1电流超出采样范围";
CM_ SG_ 2550857864 P8_CrntSnsr2Invalid "电池包8的电流传感器2电流采样失效";
CM_ SG_ 2550857864 P8_CrntSnsr2OOR "电池包8的电流传感器2电流超出采样范围";
CM_ SG_ 2550857864 P8_PackCrnSnsr2OffsetHi "电池包8的电流传感器2零漂过大";
CM_ SG_ 2550857864 P8_OutofEnergy "电池包8的电池剩余电量低";
CM_ SG_ 2550857864 P8_IsolDetCircErr "电池包8的绝缘检测电路失效";
CM_ SG_ 2550857864 P8_HVILCircShortToGND "电池包8的高压互锁对地短路";
CM_ SG_ 2550857864 P8_HVILCircShortToPwr "电池包8的高压互锁对电源短路";
CM_ SG_ 2550923400 P8_MainPosCntctrStkClsd "电池包8的主正继电器粘连故障";
CM_ SG_ 2550923400 P8_MainPosCntctrStkOpn "电池包8的主正继电器常开故障";
CM_ SG_ 2550923400 P8_MainNegCntctr1StkClsd "电池包8的主负继电器1粘连故障";
CM_ SG_ 2550923400 P8_MainNegCntctr1StkOpn "电池包8的主负继电器1常开故障";
CM_ SG_ 2550923400 P8_MainNegCntctr2StkClsd "电池包8的主负继电器2粘连故障";
CM_ SG_ 2550923400 P8_MainNegCntctr2StkOpn "电池包8的主负继电器2常开故障";
CM_ SG_ 2550923400 P8_PrechargTmOut "电池包8的预充超时故障";
CM_ SG_ 2550923400 P8_PrechrgCrntHi "电池包8的预充过流故障";
CM_ SG_ 2550923400 P8_ChrgCplrPosTempHi "电池包8的充电正极接口温度过高故障";
CM_ SG_ 2550923400 P8_ChrgCplrNegTempHi "电池包8的充电负极接口温度过高故障";
CM_ SG_ 2550923400 P8_BMSPwrSuplVlt1Hi "电池包8的BMS供电电压1过高";
CM_ SG_ 2550923400 P8_BMSPwrSuplVlt1Lo "电池包8的BMS供电电压1过低";
CM_ SG_ 2550923400 P8_BMSPwrSuplVlt2Hi "电池包8的BMS供电电压2过高";
CM_ SG_ 2550923400 P8_BMSPwrSuplVlt2Lo "电池包8的BMS供电电压2过低";
CM_ SG_ 2550923400 P8_CntctrCirPwrSuplVltLo "电池包8的继电器驱动供电电压过低";
CM_ SG_ 2550923400 P8_CntctrCirPwrSuplVltHi "电池包8的继电器驱动供电电压过高";
CM_ SG_ 2550923400 P8_CAN1BusOff "电池包8的CAN1通信Bus off";
CM_ SG_ 2550923400 P8_CAN1BusTmOut "电池包8的CAN1报文超时（Timeout）";
CM_ SG_ 2550923400 P8_CAN2BusOff "电池包8的CAN2通信Bus off";
CM_ SG_ 2550923400 P8_CAN2BusTmOut "电池包8的CAN2报文超时（Timeout）";
CM_ SG_ 2550923400 P8_CellBalCircTempHi "电池包8的均衡电路过温";
CM_ SG_ 2550923400 P8_ClntInTempHi "电池包8的入水口温度过高";
CM_ SG_ 2550923400 P8_ClntOutTempHi "电池包8的出水口温度过高";
CM_ SG_ 2550923400 P8_CellExtrmUdrVolt "电池包8的单体极限欠压";
CM_ SG_ 2550923400 P8_CellExtrmOvrVolt "电池包8的单体极限过压";
CM_ SG_ 2550923400 P8_Branch1DischrgCrntHi  "电池包8的支路1放电过流";
CM_ SG_ 2550923400 P8_Branch2DischrgCrntHi  "电池包8的支路2放电过流";
CM_ SG_ 2550923400 P8_Branch1ChrgCrntHi  "电池包8的支路1充电过流";
CM_ SG_ 2550923400 P8_Branch2ChrgCrntHi  "电池包8的支路2充电过流";
CM_ SG_ 2550923400 P8_InitFailed "电池包8的BMS初始化失败";
CM_ SG_ 2550923400 P8_PackErrCode "电池包8的故障代码";
CM_ SG_ 2550988936 P8_PackTotCellNum "电池包8的单体电池总数";
CM_ SG_ 2550988936 P8_PackTotCellTempSnsrNum "电池包8的单体温度传感器总数";
CM_ SG_ 2552299656 P8_BMSASWMajVerNum "电池包8的BMS应用层软件主版本号";
CM_ SG_ 2552299656 P8_BMSASWMinVerNum "电池包8的BMS应用层软件子版本号";
CM_ SG_ 2552299656 P8_BMSASWPatchVerNum "电池包8的BMS应用层软件修订版本号";
CM_ SG_ 2552299656 P8_BMSBSWMajVerNum "电池包8的BMS底层软件主版本号";
CM_ SG_ 2552299656 P8_BMSBSWMinVerNum "电池包8的BMS底层软件子版本号";
CM_ SG_ 2552299656 P8_BMSBSWPatchVerNum "电池包8的BMS底层软件修订版本号";
CM_ SG_ 2554396808 P8_CellVoltage1 "电池包8的单体电压1";
CM_ SG_ 2554396808 P8_CellVoltage2 "电池包8的单体电压2";
CM_ SG_ 2554396808 P8_CellVoltage3 "电池包8的单体电压3";
CM_ SG_ 2554396808 P8_CellVoltage4 "电池包8的单体电压4";
CM_ SG_ 2554396808 P8_BalSwCell1 "电池包8的电芯1均衡状态";
CM_ SG_ 2554396808 P8_BalSwCell2 "电池包8的电芯2均衡状态";
CM_ SG_ 2554396808 P8_BalSwCell3 "电池包8的电芯3均衡状态";
CM_ SG_ 2554396808 P8_BalSwCell4 "电池包8的电芯4均衡状态";
CM_ SG_ 2554462344 P8_CellVoltage5 "电池包8的单体电压5";
CM_ SG_ 2554462344 P8_CellVoltage6 "电池包8的单体电压6";
CM_ SG_ 2554462344 P8_CellVoltage7 "电池包8的单体电压7";
CM_ SG_ 2554462344 P8_CellVoltage8 "电池包8的单体电压8";
CM_ SG_ 2554462344 P8_BalSwCell5 "电池包8的电芯5均衡状态";
CM_ SG_ 2554462344 P8_BalSwCell6 "电池包8的电芯6均衡状态";
CM_ SG_ 2554462344 P8_BalSwCell7 "电池包8的电芯7均衡状态";
CM_ SG_ 2554462344 P8_BalSwCell8 "电池包8的电芯8均衡状态";
CM_ SG_ 2554527880 P8_CellVoltage9 "电池包8的单体电压9";
CM_ SG_ 2554527880 P8_CellVoltage10 "电池包8的单体电压10";
CM_ SG_ 2554527880 P8_CellVoltage11 "电池包8的单体电压11";
CM_ SG_ 2554527880 P8_CellVoltage12 "电池包8的单体电压12";
CM_ SG_ 2554527880 P8_BalSwCell9 "电池包8的电芯9均衡状态";
CM_ SG_ 2554527880 P8_BalSwCell10 "电池包8的电芯10均衡状态";
CM_ SG_ 2554527880 P8_BalSwCell11 "电池包8的电芯11均衡状态";
CM_ SG_ 2554527880 P8_BalSwCell12 "电池包8的电芯12均衡状态";
CM_ SG_ 2554593416 P8_CellVoltage13 "电池包8的单体电压13";
CM_ SG_ 2554593416 P8_CellVoltage14 "电池包8的单体电压14";
CM_ SG_ 2554593416 P8_CellVoltage15 "电池包8的单体电压15";
CM_ SG_ 2554593416 P8_CellVoltage16 "电池包8的单体电压16";
CM_ SG_ 2554593416 P8_BalSwCell13 "电池包8的电芯13均衡状态";
CM_ SG_ 2554593416 P8_BalSwCell14 "电池包8的电芯14均衡状态";
CM_ SG_ 2554593416 P8_BalSwCell15 "电池包8的电芯15均衡状态";
CM_ SG_ 2554593416 P8_BalSwCell16 "电池包8的电芯16均衡状态";
CM_ SG_ 2554658952 P8_CellVoltage17 "电池包8的单体电压17";
CM_ SG_ 2554658952 P8_CellVoltage18 "电池包8的单体电压18";
CM_ SG_ 2554658952 P8_CellVoltage19 "电池包8的单体电压19";
CM_ SG_ 2554658952 P8_CellVoltage20 "电池包8的单体电压20";
CM_ SG_ 2554658952 P8_BalSwCell17 "电池包8的电芯17均衡状态";
CM_ SG_ 2554658952 P8_BalSwCell18 "电池包8的电芯18均衡状态";
CM_ SG_ 2554658952 P8_BalSwCell19 "电池包8的电芯19均衡状态";
CM_ SG_ 2554658952 P8_BalSwCell20 "电池包8的电芯20均衡状态";
CM_ SG_ 2554724488 P8_CellVoltage21 "电池包8的单体电压21";
CM_ SG_ 2554724488 P8_CellVoltage22 "电池包8的单体电压22";
CM_ SG_ 2554724488 P8_CellVoltage23 "电池包8的单体电压23";
CM_ SG_ 2554724488 P8_CellVoltage24 "电池包8的单体电压24";
CM_ SG_ 2554724488 P8_BalSwCell21 "电池包8的电芯21均衡状态";
CM_ SG_ 2554724488 P8_BalSwCell22 "电池包8的电芯22均衡状态";
CM_ SG_ 2554724488 P8_BalSwCell23 "电池包8的电芯23均衡状态";
CM_ SG_ 2554724488 P8_BalSwCell24 "电池包8的电芯24均衡状态";
CM_ SG_ 2554790024 P8_CellVoltage25 "电池包8的单体电压25";
CM_ SG_ 2554790024 P8_CellVoltage26 "电池包8的单体电压26";
CM_ SG_ 2554790024 P8_CellVoltage27 "电池包8的单体电压27";
CM_ SG_ 2554790024 P8_CellVoltage28 "电池包8的单体电压28";
CM_ SG_ 2554790024 P8_BalSwCell25 "电池包8的电芯25均衡状态";
CM_ SG_ 2554790024 P8_BalSwCell26 "电池包8的电芯26均衡状态";
CM_ SG_ 2554790024 P8_BalSwCell27 "电池包8的电芯27均衡状态";
CM_ SG_ 2554790024 P8_BalSwCell28 "电池包8的电芯28均衡状态";
CM_ SG_ 2554855560 P8_CellVoltage29 "电池包8的单体电压29";
CM_ SG_ 2554855560 P8_CellVoltage30 "电池包8的单体电压30";
CM_ SG_ 2554855560 P8_CellVoltage31 "电池包8的单体电压31";
CM_ SG_ 2554855560 P8_CellVoltage32 "电池包8的单体电压32";
CM_ SG_ 2554855560 P8_BalSwCell29 "电池包8的电芯29均衡状态";
CM_ SG_ 2554855560 P8_BalSwCell30 "电池包8的电芯30均衡状态";
CM_ SG_ 2554855560 P8_BalSwCell31 "电池包8的电芯31均衡状态";
CM_ SG_ 2554855560 P8_BalSwCell32 "电池包8的电芯32均衡状态";
CM_ SG_ 2554921096 P8_CellVoltage33 "电池包8的单体电压33";
CM_ SG_ 2554921096 P8_CellVoltage34 "电池包8的单体电压34";
CM_ SG_ 2554921096 P8_CellVoltage35 "电池包8的单体电压35";
CM_ SG_ 2554921096 P8_CellVoltage36 "电池包8的单体电压36";
CM_ SG_ 2554921096 P8_BalSwCell33 "电池包8的电芯33均衡状态";
CM_ SG_ 2554921096 P8_BalSwCell34 "电池包8的电芯34均衡状态";
CM_ SG_ 2554921096 P8_BalSwCell35 "电池包8的电芯35均衡状态";
CM_ SG_ 2554921096 P8_BalSwCell36 "电池包8的电芯36均衡状态";
CM_ SG_ 2554986632 P8_CellVoltage37 "电池包8的单体电压37";
CM_ SG_ 2554986632 P8_CellVoltage38 "电池包8的单体电压38";
CM_ SG_ 2554986632 P8_CellVoltage39 "电池包8的单体电压39";
CM_ SG_ 2554986632 P8_CellVoltage40 "电池包8的单体电压40";
CM_ SG_ 2554986632 P8_BalSwCell37 "电池包8的电芯37均衡状态";
CM_ SG_ 2554986632 P8_BalSwCell38 "电池包8的电芯38均衡状态";
CM_ SG_ 2554986632 P8_BalSwCell39 "电池包8的电芯39均衡状态";
CM_ SG_ 2554986632 P8_BalSwCell40 "电池包8的电芯40均衡状态";
CM_ SG_ 2555052168 P8_CellVoltage41 "电池包8的单体电压41";
CM_ SG_ 2555052168 P8_CellVoltage42 "电池包8的单体电压42";
CM_ SG_ 2555052168 P8_CellVoltage43 "电池包8的单体电压43";
CM_ SG_ 2555052168 P8_CellVoltage44 "电池包8的单体电压44";
CM_ SG_ 2555052168 P8_BalSwCell41 "电池包8的电芯41均衡状态";
CM_ SG_ 2555052168 P8_BalSwCell42 "电池包8的电芯42均衡状态";
CM_ SG_ 2555052168 P8_BalSwCell43 "电池包8的电芯43均衡状态";
CM_ SG_ 2555052168 P8_BalSwCell44 "电池包8的电芯44均衡状态";
CM_ SG_ 2555117704 P8_CellVoltage45 "电池包8的单体电压45";
CM_ SG_ 2555117704 P8_CellVoltage46 "电池包8的单体电压46";
CM_ SG_ 2555117704 P8_CellVoltage47 "电池包8的单体电压47";
CM_ SG_ 2555117704 P8_CellVoltage48 "电池包8的单体电压48";
CM_ SG_ 2555117704 P8_BalSwCell45 "电池包8的电芯45均衡状态";
CM_ SG_ 2555117704 P8_BalSwCell46 "电池包8的电芯46均衡状态";
CM_ SG_ 2555117704 P8_BalSwCell47 "电池包8的电芯47均衡状态";
CM_ SG_ 2555117704 P8_BalSwCell48 "电池包8的电芯48均衡状态";
CM_ SG_ 2555183240 P8_CellVoltage49 "电池包8的单体电压49";
CM_ SG_ 2555183240 P8_CellVoltage50 "电池包8的单体电压50";
CM_ SG_ 2555183240 P8_CellVoltage51 "电池包8的单体电压51";
CM_ SG_ 2555183240 P8_CellVoltage52 "电池包8的单体电压52";
CM_ SG_ 2555183240 P8_BalSwCell49 "电池包8的电芯49均衡状态";
CM_ SG_ 2555183240 P8_BalSwCell50 "电池包8的电芯50均衡状态";
CM_ SG_ 2555183240 P8_BalSwCell51 "电池包8的电芯51均衡状态";
CM_ SG_ 2555183240 P8_BalSwCell52 "电池包8的电芯52均衡状态";
CM_ SG_ 2555248776 P8_CellVoltage53 "电池包8的单体电压53";
CM_ SG_ 2555248776 P8_CellVoltage54 "电池包8的单体电压54";
CM_ SG_ 2555248776 P8_CellVoltage55 "电池包8的单体电压55";
CM_ SG_ 2555248776 P8_CellVoltage56 "电池包8的单体电压56";
CM_ SG_ 2555248776 P8_BalSwCell53 "电池包8的电芯53均衡状态";
CM_ SG_ 2555248776 P8_BalSwCell54 "电池包8的电芯54均衡状态";
CM_ SG_ 2555248776 P8_BalSwCell55 "电池包8的电芯55均衡状态";
CM_ SG_ 2555248776 P8_BalSwCell56 "电池包8的电芯56均衡状态";
CM_ SG_ 2555314312 P8_CellVoltage57 "电池包8的单体电压57";
CM_ SG_ 2555314312 P8_CellVoltage58 "电池包8的单体电压58";
CM_ SG_ 2555314312 P8_CellVoltage59 "电池包8的单体电压59";
CM_ SG_ 2555314312 P8_CellVoltage60 "电池包8的单体电压60";
CM_ SG_ 2555314312 P8_BalSwCell57 "电池包8的电芯57均衡状态";
CM_ SG_ 2555314312 P8_BalSwCell58 "电池包8的电芯58均衡状态";
CM_ SG_ 2555314312 P8_BalSwCell59 "电池包8的电芯59均衡状态";
CM_ SG_ 2555314312 P8_BalSwCell60 "电池包8的电芯60均衡状态";
CM_ SG_ 2555379848 P8_CellVoltage61 "电池包8的单体电压61";
CM_ SG_ 2555379848 P8_CellVoltage62 "电池包8的单体电压62";
CM_ SG_ 2555379848 P8_CellVoltage63 "电池包8的单体电压63";
CM_ SG_ 2555379848 P8_CellVoltage64 "电池包8的单体电压64";
CM_ SG_ 2555379848 P8_BalSwCell61 "电池包8的电芯61均衡状态";
CM_ SG_ 2555379848 P8_BalSwCell62 "电池包8的电芯62均衡状态";
CM_ SG_ 2555379848 P8_BalSwCell63 "电池包8的电芯63均衡状态";
CM_ SG_ 2555379848 P8_BalSwCell64 "电池包8的电芯64均衡状态";
CM_ SG_ 2555445384 P8_CellVoltage65 "电池包8的单体电压65";
CM_ SG_ 2555445384 P8_CellVoltage66 "电池包8的单体电压66";
CM_ SG_ 2555445384 P8_CellVoltage67 "电池包8的单体电压67";
CM_ SG_ 2555445384 P8_CellVoltage68 "电池包8的单体电压68";
CM_ SG_ 2555445384 P8_BalSwCell65 "电池包8的电芯65均衡状态";
CM_ SG_ 2555445384 P8_BalSwCell66 "电池包8的电芯66均衡状态";
CM_ SG_ 2555445384 P8_BalSwCell67 "电池包8的电芯67均衡状态";
CM_ SG_ 2555445384 P8_BalSwCell68 "电池包8的电芯68均衡状态";
CM_ SG_ 2555510920 P8_CellVoltage69 "电池包8的单体电压69";
CM_ SG_ 2555510920 P8_CellVoltage70 "电池包8的单体电压70";
CM_ SG_ 2555510920 P8_CellVoltage71 "电池包8的单体电压71";
CM_ SG_ 2555510920 P8_CellVoltage72 "电池包8的单体电压72";
CM_ SG_ 2555510920 P8_BalSwCell69 "电池包8的电芯69均衡状态";
CM_ SG_ 2555510920 P8_BalSwCell70 "电池包8的电芯70均衡状态";
CM_ SG_ 2555510920 P8_BalSwCell71 "电池包8的电芯71均衡状态";
CM_ SG_ 2555510920 P8_BalSwCell72 "电池包8的电芯72均衡状态";
CM_ SG_ 2555576456 P8_CellVoltage73 "电池包8的单体电压73";
CM_ SG_ 2555576456 P8_CellVoltage74 "电池包8的单体电压74";
CM_ SG_ 2555576456 P8_CellVoltage75 "电池包8的单体电压75";
CM_ SG_ 2555576456 P8_CellVoltage76 "电池包8的单体电压76";
CM_ SG_ 2555576456 P8_BalSwCell73 "电池包8的电芯73均衡状态";
CM_ SG_ 2555576456 P8_BalSwCell74 "电池包8的电芯74均衡状态";
CM_ SG_ 2555576456 P8_BalSwCell75 "电池包8的电芯75均衡状态";
CM_ SG_ 2555576456 P8_BalSwCell76 "电池包8的电芯76均衡状态";
CM_ SG_ 2555641992 P8_CellVoltage77 "电池包8的单体电压77";
CM_ SG_ 2555641992 P8_CellVoltage78 "电池包8的单体电压78";
CM_ SG_ 2555641992 P8_CellVoltage79 "电池包8的单体电压79";
CM_ SG_ 2555641992 P8_CellVoltage80 "电池包8的单体电压80";
CM_ SG_ 2555641992 P8_BalSwCell77 "电池包8的电芯77均衡状态";
CM_ SG_ 2555641992 P8_BalSwCell78 "电池包8的电芯78均衡状态";
CM_ SG_ 2555641992 P8_BalSwCell79 "电池包8的电芯79均衡状态";
CM_ SG_ 2555641992 P8_BalSwCell80 "电池包8的电芯80均衡状态";
CM_ SG_ 2555707528 P8_CellVoltage81 "电池包8的单体电压81";
CM_ SG_ 2555707528 P8_CellVoltage82 "电池包8的单体电压82";
CM_ SG_ 2555707528 P8_CellVoltage83 "电池包8的单体电压83";
CM_ SG_ 2555707528 P8_CellVoltage84 "电池包8的单体电压84";
CM_ SG_ 2555707528 P8_BalSwCell81 "电池包8的电芯81均衡状态";
CM_ SG_ 2555707528 P8_BalSwCell82 "电池包8的电芯82均衡状态";
CM_ SG_ 2555707528 P8_BalSwCell83 "电池包8的电芯83均衡状态";
CM_ SG_ 2555707528 P8_BalSwCell84 "电池包8的电芯84均衡状态";
CM_ SG_ 2555773064 P8_CellVoltage85 "电池包8的单体电压85";
CM_ SG_ 2555773064 P8_CellVoltage86 "电池包8的单体电压86";
CM_ SG_ 2555773064 P8_CellVoltage87 "电池包8的单体电压87";
CM_ SG_ 2555773064 P8_CellVoltage88 "电池包8的单体电压88";
CM_ SG_ 2555773064 P8_BalSwCell85 "电池包8的电芯85均衡状态";
CM_ SG_ 2555773064 P8_BalSwCell86 "电池包8的电芯86均衡状态";
CM_ SG_ 2555773064 P8_BalSwCell87 "电池包8的电芯87均衡状态";
CM_ SG_ 2555773064 P8_BalSwCell88 "电池包8的电芯88均衡状态";
CM_ SG_ 2555838600 P8_CellVoltage89 "电池包8的单体电压89";
CM_ SG_ 2555838600 P8_CellVoltage90 "电池包8的单体电压90";
CM_ SG_ 2555838600 P8_CellVoltage91 "电池包8的单体电压91";
CM_ SG_ 2555838600 P8_CellVoltage92 "电池包8的单体电压92";
CM_ SG_ 2555838600 P8_BalSwCell89 "电池包8的电芯89均衡状态";
CM_ SG_ 2555838600 P8_BalSwCell90 "电池包8的电芯90均衡状态";
CM_ SG_ 2555838600 P8_BalSwCell91 "电池包8的电芯91均衡状态";
CM_ SG_ 2555838600 P8_BalSwCell92 "电池包8的电芯92均衡状态";
CM_ SG_ 2555904136 P8_CellVoltage93 "电池包8的单体电压93";
CM_ SG_ 2555904136 P8_CellVoltage94 "电池包8的单体电压94";
CM_ SG_ 2555904136 P8_CellVoltage95 "电池包8的单体电压95";
CM_ SG_ 2555904136 P8_CellVoltage96 "电池包8的单体电压96";
CM_ SG_ 2555904136 P8_BalSwCell93 "电池包8的电芯93均衡状态";
CM_ SG_ 2555904136 P8_BalSwCell94 "电池包8的电芯94均衡状态";
CM_ SG_ 2555904136 P8_BalSwCell95 "电池包8的电芯95均衡状态";
CM_ SG_ 2555904136 P8_BalSwCell96 "电池包8的电芯96均衡状态";
CM_ SG_ 2555969672 P8_CellVoltage97 "电池包8的单体电压97";
CM_ SG_ 2555969672 P8_CellVoltage98 "电池包8的单体电压98";
CM_ SG_ 2555969672 P8_CellVoltage99 "电池包8的单体电压99";
CM_ SG_ 2555969672 P8_CellVoltage100 "电池包8的单体电压100";
CM_ SG_ 2555969672 P8_BalSwCell97 "电池包8的电芯97均衡状态";
CM_ SG_ 2555969672 P8_BalSwCell98 "电池包8的电芯98均衡状态";
CM_ SG_ 2555969672 P8_BalSwCell99 "电池包8的电芯99均衡状态";
CM_ SG_ 2555969672 P8_BalSwCell100 "电池包8的电芯100均衡状态";
CM_ SG_ 2556035208 P8_CellVoltage101 "电池包8的单体电压101";
CM_ SG_ 2556035208 P8_CellVoltage102 "电池包8的单体电压102";
CM_ SG_ 2556035208 P8_CellVoltage103 "电池包8的单体电压103";
CM_ SG_ 2556035208 P8_CellVoltage104 "电池包8的单体电压104";
CM_ SG_ 2556035208 P8_BalSwCell101 "电池包8的电芯101均衡状态";
CM_ SG_ 2556035208 P8_BalSwCell102 "电池包8的电芯102均衡状态";
CM_ SG_ 2556035208 P8_BalSwCell103 "电池包8的电芯103均衡状态";
CM_ SG_ 2556035208 P8_BalSwCell104 "电池包8的电芯104均衡状态";
CM_ SG_ 2556100744 P8_CellVoltage105 "电池包8的单体电压105";
CM_ SG_ 2556100744 P8_CellVoltage106 "电池包8的单体电压106";
CM_ SG_ 2556100744 P8_CellVoltage107 "电池包8的单体电压107";
CM_ SG_ 2556100744 P8_CellVoltage108 "电池包8的单体电压108";
CM_ SG_ 2556100744 P8_BalSwCell105 "电池包8的电芯105均衡状态";
CM_ SG_ 2556100744 P8_BalSwCell106 "电池包8的电芯106均衡状态";
CM_ SG_ 2556100744 P8_BalSwCell107 "电池包8的电芯107均衡状态";
CM_ SG_ 2556100744 P8_BalSwCell108 "电池包8的电芯108均衡状态";
CM_ SG_ 2556166280 P8_CellVoltage109 "电池包8的单体电压109";
CM_ SG_ 2556166280 P8_CellVoltage110 "电池包8的单体电压110";
CM_ SG_ 2556166280 P8_CellVoltage111 "电池包8的单体电压111";
CM_ SG_ 2556166280 P8_CellVoltage112 "电池包8的单体电压112";
CM_ SG_ 2556166280 P8_BalSwCell109 "电池包8的电芯109均衡状态";
CM_ SG_ 2556166280 P8_BalSwCell110 "电池包8的电芯110均衡状态";
CM_ SG_ 2556166280 P8_BalSwCell111 "电池包8的电芯111均衡状态";
CM_ SG_ 2556166280 P8_BalSwCell112 "电池包8的电芯112均衡状态";
CM_ SG_ 2556231816 P8_CellVoltage113 "电池包8的单体电压113";
CM_ SG_ 2556231816 P8_CellVoltage114 "电池包8的单体电压114";
CM_ SG_ 2556231816 P8_CellVoltage115 "电池包8的单体电压115";
CM_ SG_ 2556231816 P8_CellVoltage116 "电池包8的单体电压116";
CM_ SG_ 2556231816 P8_BalSwCell113 "电池包8的电芯113均衡状态";
CM_ SG_ 2556231816 P8_BalSwCell114 "电池包8的电芯114均衡状态";
CM_ SG_ 2556231816 P8_BalSwCell115 "电池包8的电芯115均衡状态";
CM_ SG_ 2556231816 P8_BalSwCell116 "电池包8的电芯116均衡状态";
CM_ SG_ 2556297352 P8_CellVoltage117 "电池包8的单体电压117";
CM_ SG_ 2556297352 P8_CellVoltage118 "电池包8的单体电压118";
CM_ SG_ 2556297352 P8_CellVoltage119 "电池包8的单体电压119";
CM_ SG_ 2556297352 P8_CellVoltage120 "电池包8的单体电压120";
CM_ SG_ 2556297352 P8_BalSwCell117 "电池包8的电芯117均衡状态";
CM_ SG_ 2556297352 P8_BalSwCell118 "电池包8的电芯118均衡状态";
CM_ SG_ 2556297352 P8_BalSwCell119 "电池包8的电芯119均衡状态";
CM_ SG_ 2556297352 P8_BalSwCell120 "电池包8的电芯120均衡状态";
CM_ SG_ 2556362888 P8_CellVoltage121 "电池包8的单体电压121";
CM_ SG_ 2556362888 P8_CellVoltage122 "电池包8的单体电压122";
CM_ SG_ 2556362888 P8_CellVoltage123 "电池包8的单体电压123";
CM_ SG_ 2556362888 P8_CellVoltage124 "电池包8的单体电压124";
CM_ SG_ 2556362888 P8_BalSwCell121 "电池包8的电芯121均衡状态";
CM_ SG_ 2556362888 P8_BalSwCell122 "电池包8的电芯122均衡状态";
CM_ SG_ 2556362888 P8_BalSwCell123 "电池包8的电芯123均衡状态";
CM_ SG_ 2556362888 P8_BalSwCell124 "电池包8的电芯124均衡状态";
CM_ SG_ 2556428424 P8_CellVoltage125 "电池包8的单体电压125";
CM_ SG_ 2556428424 P8_CellVoltage126 "电池包8的单体电压126";
CM_ SG_ 2556428424 P8_CellVoltage127 "电池包8的单体电压127";
CM_ SG_ 2556428424 P8_CellVoltage128 "电池包8的单体电压128";
CM_ SG_ 2556428424 P8_BalSwCell125 "电池包8的电芯125均衡状态";
CM_ SG_ 2556428424 P8_BalSwCell126 "电池包8的电芯126均衡状态";
CM_ SG_ 2556428424 P8_BalSwCell127 "电池包8的电芯127均衡状态";
CM_ SG_ 2556428424 P8_BalSwCell128 "电池包8的电芯128均衡状态";
CM_ SG_ 2556493960 P8_CellVoltage129 "电池包8的单体电压129";
CM_ SG_ 2556493960 P8_CellVoltage130 "电池包8的单体电压130";
CM_ SG_ 2556493960 P8_CellVoltage131 "电池包8的单体电压131";
CM_ SG_ 2556493960 P8_CellVoltage132 "电池包8的单体电压132";
CM_ SG_ 2556493960 P8_BalSwCell129 "电池包8的电芯129均衡状态";
CM_ SG_ 2556493960 P8_BalSwCell130 "电池包8的电芯130均衡状态";
CM_ SG_ 2556493960 P8_BalSwCell131 "电池包8的电芯131均衡状态";
CM_ SG_ 2556493960 P8_BalSwCell132 "电池包8的电芯132均衡状态";
CM_ SG_ 2556559496 P8_CellVoltage133 "电池包8的单体电压133";
CM_ SG_ 2556559496 P8_CellVoltage134 "电池包8的单体电压134";
CM_ SG_ 2556559496 P8_CellVoltage135 "电池包8的单体电压135";
CM_ SG_ 2556559496 P8_CellVoltage136 "电池包8的单体电压136";
CM_ SG_ 2556559496 P8_BalSwCell133 "电池包8的电芯133均衡状态";
CM_ SG_ 2556559496 P8_BalSwCell134 "电池包8的电芯134均衡状态";
CM_ SG_ 2556559496 P8_BalSwCell135 "电池包8的电芯135均衡状态";
CM_ SG_ 2556559496 P8_BalSwCell136 "电池包8的电芯136均衡状态";
CM_ SG_ 2556625032 P8_CellVoltage137 "电池包8的单体电压137";
CM_ SG_ 2556625032 P8_CellVoltage138 "电池包8的单体电压138";
CM_ SG_ 2556625032 P8_CellVoltage139 "电池包8的单体电压139";
CM_ SG_ 2556625032 P8_CellVoltage140 "电池包8的单体电压140";
CM_ SG_ 2556625032 P8_BalSwCell137 "电池包8的电芯137均衡状态";
CM_ SG_ 2556625032 P8_BalSwCell138 "电池包8的电芯138均衡状态";
CM_ SG_ 2556625032 P8_BalSwCell139 "电池包8的电芯139均衡状态";
CM_ SG_ 2556625032 P8_BalSwCell140 "电池包8的电芯140均衡状态";
CM_ SG_ 2556690568 P8_CellVoltage141 "电池包8的单体电压141";
CM_ SG_ 2556690568 P8_CellVoltage142 "电池包8的单体电压142";
CM_ SG_ 2556690568 P8_CellVoltage143 "电池包8的单体电压143";
CM_ SG_ 2556690568 P8_CellVoltage144 "电池包8的单体电压144";
CM_ SG_ 2556690568 P8_BalSwCell141 "电池包8的电芯141均衡状态";
CM_ SG_ 2556690568 P8_BalSwCell142 "电池包8的电芯142均衡状态";
CM_ SG_ 2556690568 P8_BalSwCell143 "电池包8的电芯143均衡状态";
CM_ SG_ 2556690568 P8_BalSwCell144 "电池包8的电芯144均衡状态";
CM_ SG_ 2556756104 P8_CellVoltage145 "电池包8的单体电压145";
CM_ SG_ 2556756104 P8_CellVoltage146 "电池包8的单体电压146";
CM_ SG_ 2556756104 P8_CellVoltage147 "电池包8的单体电压147";
CM_ SG_ 2556756104 P8_CellVoltage148 "电池包8的单体电压148";
CM_ SG_ 2556756104 P8_BalSwCell145 "电池包8的电芯145均衡状态";
CM_ SG_ 2556756104 P8_BalSwCell146 "电池包8的电芯146均衡状态";
CM_ SG_ 2556756104 P8_BalSwCell147 "电池包8的电芯147均衡状态";
CM_ SG_ 2556756104 P8_BalSwCell148 "电池包8的电芯148均衡状态";
CM_ SG_ 2556821640 P8_CellVoltage149 "电池包8的单体电压149";
CM_ SG_ 2556821640 P8_CellVoltage150 "电池包8的单体电压150";
CM_ SG_ 2556821640 P8_CellVoltage151 "电池包8的单体电压151";
CM_ SG_ 2556821640 P8_CellVoltage152 "电池包8的单体电压152";
CM_ SG_ 2556821640 P8_BalSwCell149 "电池包8的电芯149均衡状态";
CM_ SG_ 2556821640 P8_BalSwCell150 "电池包8的电芯150均衡状态";
CM_ SG_ 2556821640 P8_BalSwCell151 "电池包8的电芯151均衡状态";
CM_ SG_ 2556821640 P8_BalSwCell152 "电池包8的电芯152均衡状态";
CM_ SG_ 2556887176 P8_CellVoltage153 "电池包8的单体电压153";
CM_ SG_ 2556887176 P8_CellVoltage154 "电池包8的单体电压154";
CM_ SG_ 2556887176 P8_CellVoltage155 "电池包8的单体电压155";
CM_ SG_ 2556887176 P8_CellVoltage156 "电池包8的单体电压156";
CM_ SG_ 2556887176 P8_BalSwCell153 "电池包8的电芯153均衡状态";
CM_ SG_ 2556887176 P8_BalSwCell154 "电池包8的电芯154均衡状态";
CM_ SG_ 2556887176 P8_BalSwCell155 "电池包8的电芯155均衡状态";
CM_ SG_ 2556887176 P8_BalSwCell156 "电池包8的电芯156均衡状态";
CM_ SG_ 2556952712 P8_CellVoltage157 "电池包8的单体电压157";
CM_ SG_ 2556952712 P8_CellVoltage158 "电池包8的单体电压158";
CM_ SG_ 2556952712 P8_CellVoltage159 "电池包8的单体电压159";
CM_ SG_ 2556952712 P8_CellVoltage160 "电池包8的单体电压160";
CM_ SG_ 2556952712 P8_BalSwCell157 "电池包8的电芯157均衡状态";
CM_ SG_ 2556952712 P8_BalSwCell158 "电池包8的电芯158均衡状态";
CM_ SG_ 2556952712 P8_BalSwCell159 "电池包8的电芯159均衡状态";
CM_ SG_ 2556952712 P8_BalSwCell160 "电池包8的电芯160均衡状态";
CM_ SG_ 2557018248 P8_CellVoltage161 "电池包8的单体电压161";
CM_ SG_ 2557018248 P8_CellVoltage162 "电池包8的单体电压162";
CM_ SG_ 2557018248 P8_CellVoltage163 "电池包8的单体电压163";
CM_ SG_ 2557018248 P8_CellVoltage164 "电池包8的单体电压164";
CM_ SG_ 2557018248 P8_BalSwCell161 "电池包8的电芯161均衡状态";
CM_ SG_ 2557018248 P8_BalSwCell162 "电池包8的电芯162均衡状态";
CM_ SG_ 2557018248 P8_BalSwCell163 "电池包8的电芯163均衡状态";
CM_ SG_ 2557018248 P8_BalSwCell164 "电池包8的电芯164均衡状态";
CM_ SG_ 2557083784 P8_CellVoltage165 "电池包8的单体电压165";
CM_ SG_ 2557083784 P8_CellVoltage166 "电池包8的单体电压166";
CM_ SG_ 2557083784 P8_CellVoltage167 "电池包8的单体电压167";
CM_ SG_ 2557083784 P8_CellVoltage168 "电池包8的单体电压168";
CM_ SG_ 2557083784 P8_BalSwCell165 "电池包8的电芯165均衡状态";
CM_ SG_ 2557083784 P8_BalSwCell166 "电池包8的电芯166均衡状态";
CM_ SG_ 2557083784 P8_BalSwCell167 "电池包8的电芯167均衡状态";
CM_ SG_ 2557083784 P8_BalSwCell168 "电池包8的电芯168均衡状态";
CM_ SG_ 2557149320 P8_CellVoltage169 "电池包8的单体电压169";
CM_ SG_ 2557149320 P8_CellVoltage170 "电池包8的单体电压170";
CM_ SG_ 2557149320 P8_CellVoltage171 "电池包8的单体电压171";
CM_ SG_ 2557149320 P8_CellVoltage172 "电池包8的单体电压172";
CM_ SG_ 2557149320 P8_BalSwCell169 "电池包8的电芯169均衡状态";
CM_ SG_ 2557149320 P8_BalSwCell170 "电池包8的电芯170均衡状态";
CM_ SG_ 2557149320 P8_BalSwCell171 "电池包8的电芯171均衡状态";
CM_ SG_ 2557149320 P8_BalSwCell172 "电池包8的电芯172均衡状态";
CM_ SG_ 2557214856 P8_CellVoltage173 "电池包8的单体电压173";
CM_ SG_ 2557214856 P8_CellVoltage174 "电池包8的单体电压174";
CM_ SG_ 2557214856 P8_CellVoltage175 "电池包8的单体电压175";
CM_ SG_ 2557214856 P8_CellVoltage176 "电池包8的单体电压176";
CM_ SG_ 2557214856 P8_BalSwCell173 "电池包8的电芯173均衡状态";
CM_ SG_ 2557214856 P8_BalSwCell174 "电池包8的电芯174均衡状态";
CM_ SG_ 2557214856 P8_BalSwCell175 "电池包8的电芯175均衡状态";
CM_ SG_ 2557214856 P8_BalSwCell176 "电池包8的电芯176均衡状态";
CM_ SG_ 2557280392 P8_CellVoltage177 "电池包8的单体电压177";
CM_ SG_ 2557280392 P8_CellVoltage178 "电池包8的单体电压178";
CM_ SG_ 2557280392 P8_CellVoltage179 "电池包8的单体电压179";
CM_ SG_ 2557280392 P8_CellVoltage180 "电池包8的单体电压180";
CM_ SG_ 2557280392 P8_BalSwCell177 "电池包8的电芯177均衡状态";
CM_ SG_ 2557280392 P8_BalSwCell178 "电池包8的电芯178均衡状态";
CM_ SG_ 2557280392 P8_BalSwCell179 "电池包8的电芯179均衡状态";
CM_ SG_ 2557280392 P8_BalSwCell180 "电池包8的电芯180均衡状态";
CM_ SG_ 2557345928 P8_CellVoltage181 "电池包8的单体电压181";
CM_ SG_ 2557345928 P8_CellVoltage182 "电池包8的单体电压182";
CM_ SG_ 2557345928 P8_CellVoltage183 "电池包8的单体电压183";
CM_ SG_ 2557345928 P8_CellVoltage184 "电池包8的单体电压184";
CM_ SG_ 2557345928 P8_BalSwCell181 "电池包8的电芯181均衡状态";
CM_ SG_ 2557345928 P8_BalSwCell182 "电池包8的电芯182均衡状态";
CM_ SG_ 2557345928 P8_BalSwCell183 "电池包8的电芯183均衡状态";
CM_ SG_ 2557345928 P8_BalSwCell184 "电池包8的电芯184均衡状态";
CM_ SG_ 2557411464 P8_CellVoltage185 "电池包8的单体电压185";
CM_ SG_ 2557411464 P8_CellVoltage186 "电池包8的单体电压186";
CM_ SG_ 2557411464 P8_CellVoltage187 "电池包8的单体电压187";
CM_ SG_ 2557411464 P8_CellVoltage188 "电池包8的单体电压188";
CM_ SG_ 2557411464 P8_BalSwCell185 "电池包8的电芯185均衡状态";
CM_ SG_ 2557411464 P8_BalSwCell186 "电池包8的电芯186均衡状态";
CM_ SG_ 2557411464 P8_BalSwCell187 "电池包8的电芯187均衡状态";
CM_ SG_ 2557411464 P8_BalSwCell188 "电池包8的电芯188均衡状态";
CM_ SG_ 2557477000 P8_CellVoltage189 "电池包8的单体电压189";
CM_ SG_ 2557477000 P8_CellVoltage190 "电池包8的单体电压190";
CM_ SG_ 2557477000 P8_CellVoltage191 "电池包8的单体电压191";
CM_ SG_ 2557477000 P8_CellVoltage192 "电池包8的单体电压192";
CM_ SG_ 2557477000 P8_BalSwCell189 "电池包8的电芯189均衡状态";
CM_ SG_ 2557477000 P8_BalSwCell190 "电池包8的电芯190均衡状态";
CM_ SG_ 2557477000 P8_BalSwCell191 "电池包8的电芯191均衡状态";
CM_ SG_ 2557477000 P8_BalSwCell192 "电池包8的电芯192均衡状态";
CM_ SG_ 2558525576 P8_CellTemp1 "电池包8的单体温度1";
CM_ SG_ 2558525576 P8_CellTemp2 "电池包8的单体温度2";
CM_ SG_ 2558525576 P8_CellTemp3 "电池包8的单体温度3";
CM_ SG_ 2558525576 P8_CellTemp4 "电池包8的单体温度4";
CM_ SG_ 2558525576 P8_CellTemp5 "电池包8的单体温度5";
CM_ SG_ 2558591112 P8_CellTemp6 "电池包8的单体温度6";
CM_ SG_ 2558591112 P8_CellTemp7 "电池包8的单体温度7";
CM_ SG_ 2558591112 P8_CellTemp8 "电池包8的单体温度8";
CM_ SG_ 2558591112 P8_CellTemp9 "电池包8的单体温度9";
CM_ SG_ 2558591112 P8_CellTemp10 "电池包8的单体温度10";
CM_ SG_ 2558656648 P8_CellTemp11 "电池包8的单体温度11";
CM_ SG_ 2558656648 P8_CellTemp12 "电池包8的单体温度12";
CM_ SG_ 2558656648 P8_CellTemp13 "电池包8的单体温度13";
CM_ SG_ 2558656648 P8_CellTemp14 "电池包8的单体温度14";
CM_ SG_ 2558656648 P8_CellTemp15 "电池包8的单体温度15";
CM_ SG_ 2558722184 P8_CellTemp16 "电池包8的单体温度16";
CM_ SG_ 2558722184 P8_CellTemp17 "电池包8的单体温度17";
CM_ SG_ 2558722184 P8_CellTemp18 "电池包8的单体温度18";
CM_ SG_ 2558722184 P8_CellTemp19 "电池包8的单体温度19";
CM_ SG_ 2558722184 P8_CellTemp20 "电池包8的单体温度20";
CM_ SG_ 2558787720 P8_CellTemp21 "电池包8的单体温度21";
CM_ SG_ 2558787720 P8_CellTemp22 "电池包8的单体温度22";
CM_ SG_ 2558787720 P8_CellTemp23 "电池包8的单体温度23";
CM_ SG_ 2558787720 P8_CellTemp24 "电池包8的单体温度24";
CM_ SG_ 2558787720 P8_CellTemp25 "电池包8的单体温度25";
CM_ SG_ 2558853256 P8_CellTemp26 "电池包8的单体温度26";
CM_ SG_ 2558853256 P8_CellTemp27 "电池包8的单体温度27";
CM_ SG_ 2558853256 P8_CellTemp28 "电池包8的单体温度28";
CM_ SG_ 2558853256 P8_CellTemp29 "电池包8的单体温度29";
CM_ SG_ 2558853256 P8_CellTemp30 "电池包8的单体温度30";
CM_ SG_ 2558918792 P8_CellTemp31 "电池包8的单体温度31";
CM_ SG_ 2558918792 P8_CellTemp32 "电池包8的单体温度32";
CM_ SG_ 2558918792 P8_CellTemp33 "电池包8的单体温度33";
CM_ SG_ 2558918792 P8_CellTemp34 "电池包8的单体温度34";
CM_ SG_ 2558918792 P8_CellTemp35 "电池包8的单体温度35";
CM_ SG_ 2558984328 P8_CellTemp36 "电池包8的单体温度36";
CM_ SG_ 2558984328 P8_CellTemp37 "电池包8的单体温度37";
CM_ SG_ 2558984328 P8_CellTemp38 "电池包8的单体温度38";
CM_ SG_ 2558984328 P8_CellTemp39 "电池包8的单体温度39";
CM_ SG_ 2558984328 P8_CellTemp40 "电池包8的单体温度40";
CM_ SG_ 2559049864 P8_CellTemp41 "电池包8的单体温度41";
CM_ SG_ 2559049864 P8_CellTemp42 "电池包8的单体温度42";
CM_ SG_ 2559049864 P8_CellTemp43 "电池包8的单体温度43";
CM_ SG_ 2559049864 P8_CellTemp44 "电池包8的单体温度44";
CM_ SG_ 2559049864 P8_CellTemp45 "电池包8的单体温度45";
CM_ SG_ 2559115400 P8_CellTemp46 "电池包8的单体温度46";
CM_ SG_ 2559115400 P8_CellTemp47 "电池包8的单体温度47";
CM_ SG_ 2559115400 P8_CellTemp48 "电池包8的单体温度48";
CM_ SG_ 2559115400 P8_CellTemp49 "电池包8的单体温度49";
CM_ SG_ 2559115400 P8_CellTemp50 "电池包8的单体温度50";
CM_ SG_ 2559180936 P8_CellTemp51 "电池包8的单体温度51";
CM_ SG_ 2559180936 P8_CellTemp52 "电池包8的单体温度52";
CM_ SG_ 2559180936 P8_CellTemp53 "电池包8的单体温度53";
CM_ SG_ 2559180936 P8_CellTemp54 "电池包8的单体温度54";
CM_ SG_ 2559180936 P8_CellTemp55 "电池包8的单体温度55";
CM_ SG_ 2559246472 P8_CellTemp56 "电池包8的单体温度56";
CM_ SG_ 2559246472 P8_CellTemp57 "电池包8的单体温度57";
CM_ SG_ 2559246472 P8_CellTemp58 "电池包8的单体温度58";
CM_ SG_ 2559246472 P8_CellTemp59 "电池包8的单体温度59";
CM_ SG_ 2559246472 P8_CellTemp60 "电池包8的单体温度60";
CM_ SG_ 2559312008 P8_CellTemp61 "电池包8的单体温度61";
CM_ SG_ 2559312008 P8_CellTemp62 "电池包8的单体温度62";
CM_ SG_ 2559312008 P8_CellTemp63 "电池包8的单体温度63";
CM_ SG_ 2559312008 P8_CellTemp64 "电池包8的单体温度64";
CM_ SG_ 2559312008 P8_CellTemp65 "电池包8的单体温度65";
CM_ SG_ 2559377544 P8_CellTemp66 "电池包8的单体温度66";
CM_ SG_ 2559377544 P8_CellTemp67 "电池包8的单体温度67";
CM_ SG_ 2559377544 P8_CellTemp68 "电池包8的单体温度68";
CM_ SG_ 2559377544 P8_CellTemp69 "电池包8的单体温度69";
CM_ SG_ 2559377544 P8_CellTemp70 "电池包8的单体温度70";
CM_ SG_ 2559443080 P8_CellTemp71 "电池包8的单体温度71";
CM_ SG_ 2559443080 P8_CellTemp72 "电池包8的单体温度72";
CM_ SG_ 2559443080 P8_CellTemp73 "电池包8的单体温度73";
CM_ SG_ 2559443080 P8_CellTemp74 "电池包8的单体温度74";
CM_ SG_ 2559443080 P8_CellTemp75 "电池包8的单体温度75";
CM_ SG_ 2559508616 P8_CellTemp76 "电池包8的单体温度76";
CM_ SG_ 2559508616 P8_CellTemp77 "电池包8的单体温度77";
CM_ SG_ 2559508616 P8_CellTemp78 "电池包8的单体温度78";
CM_ SG_ 2559508616 P8_CellTemp79 "电池包8的单体温度79";
CM_ SG_ 2559508616 P8_CellTemp80 "电池包8的单体温度80";
CM_ SG_ 2559574152 P8_CellTemp81 "电池包8的单体温度81";
CM_ SG_ 2559574152 P8_CellTemp82 "电池包8的单体温度82";
CM_ SG_ 2559574152 P8_CellTemp83 "电池包8的单体温度83";
CM_ SG_ 2559574152 P8_CellTemp84 "电池包8的单体温度84";
CM_ SG_ 2559574152 P8_CellTemp85 "电池包8的单体温度85";
CM_ SG_ 2559639688 P8_CellTemp86 "电池包8的单体温度86";
CM_ SG_ 2559639688 P8_CellTemp87 "电池包8的单体温度87";
CM_ SG_ 2559639688 P8_CellTemp88 "电池包8的单体温度88";
CM_ SG_ 2559639688 P8_CellTemp89 "电池包8的单体温度89";
CM_ SG_ 2559639688 P8_CellTemp90 "电池包8的单体温度90";
CM_ SG_ 2559705224 P8_CellTemp91 "电池包8的单体温度91";
CM_ SG_ 2559705224 P8_CellTemp92 "电池包8的单体温度92";
CM_ SG_ 2559705224 P8_CellTemp93 "电池包8的单体温度93";
CM_ SG_ 2559705224 P8_CellTemp94 "电池包8的单体温度94";
CM_ SG_ 2559705224 P8_CellTemp95 "电池包8的单体温度95";
CM_ SG_ 2559770760 P8_CellTemp96 "电池包8的单体温度96";
CM_ SG_ 2559770760 P8_CellTemp97 "电池包8的单体温度97";
CM_ SG_ 2559770760 P8_CellTemp98 "电池包8的单体温度98";
CM_ SG_ 2559770760 P8_CellTemp99 "电池包8的单体温度99";
CM_ SG_ 2559770760 P8_CellTemp100 "电池包8的单体温度100";
CM_ SG_ 2559836296 P8_CellTemp101 "电池包8的单体温度101";
CM_ SG_ 2559836296 P8_CellTemp102 "电池包8的单体温度102";
CM_ SG_ 2559836296 P8_CellTemp103 "电池包8的单体温度103";
CM_ SG_ 2559836296 P8_CellTemp104 "电池包8的单体温度104";
CM_ SG_ 2559836296 P8_CellTemp105 "电池包8的单体温度105";
CM_ SG_ 2559901832 P8_CellTemp106 "电池包8的单体温度106";
CM_ SG_ 2559901832 P8_CellTemp107 "电池包8的单体温度107";
CM_ SG_ 2559901832 P8_CellTemp108 "电池包8的单体温度108";
CM_ SG_ 2559901832 P8_CellTemp109 "电池包8的单体温度109";
CM_ SG_ 2559901832 P8_CellTemp110 "电池包8的单体温度110";
CM_ SG_ 2559967368 P8_CellTemp111 "电池包8的单体温度111";
CM_ SG_ 2559967368 P8_CellTemp112 "电池包8的单体温度112";
CM_ SG_ 2559967368 P8_CellTemp113 "电池包8的单体温度113";
CM_ SG_ 2559967368 P8_CellTemp114 "电池包8的单体温度114";
CM_ SG_ 2559967368 P8_CellTemp115 "电池包8的单体温度115";
CM_ SG_ 2560032904 P8_CellTemp116 "电池包8的单体温度116";
CM_ SG_ 2560032904 P8_CellTemp117 "电池包8的单体温度117";
CM_ SG_ 2560032904 P8_CellTemp118 "电池包8的单体温度118";
CM_ SG_ 2560032904 P8_CellTemp119 "电池包8的单体温度119";
CM_ SG_ 2560032904 P8_CellTemp120 "电池包8的单体温度120";
CM_ SG_ 2560098440 P8_CellTemp121 "电池包8的单体温度121";
CM_ SG_ 2560098440 P8_CellTemp122 "电池包8的单体温度122";
CM_ SG_ 2560098440 P8_CellTemp123 "电池包8的单体温度123";
CM_ SG_ 2560098440 P8_CellTemp124 "电池包8的单体温度124";
CM_ SG_ 2560098440 P8_CellTemp125 "电池包8的单体温度125";
CM_ SG_ 2560163976 P8_CellTemp126 "电池包8的单体温度126";
CM_ SG_ 2560163976 P8_CellTemp127 "电池包8的单体温度127";
CM_ SG_ 2560163976 P8_CellTemp128 "电池包8的单体温度128";
CM_ SG_ 2560163976 P8_CellTemp129 "电池包8的单体温度129";
CM_ SG_ 2560163976 P8_CellTemp130 "电池包8的单体温度130";
CM_ SG_ 2560229512 P8_CellTemp131 "电池包8的单体温度131";
CM_ SG_ 2560229512 P8_CellTemp132 "电池包8的单体温度132";
CM_ SG_ 2560229512 P8_CellTemp133 "电池包8的单体温度133";
CM_ SG_ 2560229512 P8_CellTemp134 "电池包8的单体温度134";
CM_ SG_ 2560229512 P8_CellTemp135 "电池包8的单体温度135";
CM_ SG_ 2560295048 P8_CellTemp136 "电池包8的单体温度136";
CM_ SG_ 2560295048 P8_CellTemp137 "电池包8的单体温度137";
CM_ SG_ 2560295048 P8_CellTemp138 "电池包8的单体温度138";
CM_ SG_ 2560295048 P8_CellTemp139 "电池包8的单体温度139";
CM_ SG_ 2560295048 P8_CellTemp140 "电池包8的单体温度140";
CM_ SG_ 2560360584 P8_CellTemp141 "电池包8的单体温度141";
CM_ SG_ 2560360584 P8_CellTemp142 "电池包8的单体温度142";
CM_ SG_ 2560360584 P8_CellTemp143 "电池包8的单体温度143";
CM_ SG_ 2560360584 P8_CellTemp144 "电池包8的单体温度144";
CM_ SG_ 2560360584 P8_CellTemp145 "电池包8的单体温度145";
CM_ SG_ 2560426120 P8_CellTemp146 "电池包8的单体温度146";
CM_ SG_ 2560426120 P8_CellTemp147 "电池包8的单体温度147";
CM_ SG_ 2560426120 P8_CellTemp148 "电池包8的单体温度148";
CM_ SG_ 2560426120 P8_CellTemp149 "电池包8的单体温度149";
CM_ SG_ 2560426120 P8_CellTemp150 "电池包8的单体温度150";
CM_ SG_ 2560491656 P8_CellTemp151 "电池包8的单体温度151";
CM_ SG_ 2560491656 P8_CellTemp152 "电池包8的单体温度152";
CM_ SG_ 2560491656 P8_CellTemp153 "电池包8的单体温度153";
CM_ SG_ 2560491656 P8_CellTemp154 "电池包8的单体温度154";
CM_ SG_ 2560491656 P8_CellTemp155 "电池包8的单体温度155";
CM_ SG_ 2560557192 P8_CellTemp156 "电池包8的单体温度156";
CM_ SG_ 2560557192 P8_CellTemp157 "电池包8的单体温度157";
CM_ SG_ 2560557192 P8_CellTemp158 "电池包8的单体温度158";
CM_ SG_ 2560557192 P8_CellTemp159 "电池包8的单体温度159";
CM_ SG_ 2560557192 P8_CellTemp160 "电池包8的单体温度160";
CM_ SG_ 2560622728 P8_CellTemp161 "电池包8的单体温度161";
CM_ SG_ 2560622728 P8_CellTemp162 "电池包8的单体温度162";
CM_ SG_ 2560622728 P8_CellTemp163 "电池包8的单体温度163";
CM_ SG_ 2560622728 P8_CellTemp164 "电池包8的单体温度164";
CM_ SG_ 2560622728 P8_CellTemp165 "电池包8的单体温度165";
CM_ SG_ 2560688264 P8_CellTemp166 "电池包8的单体温度166";
CM_ SG_ 2560688264 P8_CellTemp167 "电池包8的单体温度167";
CM_ SG_ 2560688264 P8_CellTemp168 "电池包8的单体温度168";
CM_ SG_ 2560688264 P8_CellTemp169 "电池包8的单体温度169";
CM_ SG_ 2560688264 P8_CellTemp170 "电池包8的单体温度170";
CM_ SG_ 2560753800 P8_CellTemp171 "电池包8的单体温度171";
CM_ SG_ 2560753800 P8_CellTemp172 "电池包8的单体温度172";
CM_ SG_ 2560753800 P8_CellTemp173 "电池包8的单体温度173";
CM_ SG_ 2560753800 P8_CellTemp174 "电池包8的单体温度174";
CM_ SG_ 2560753800 P8_CellTemp175 "电池包8的单体温度175";
CM_ SG_ 2560819336 P8_CellTemp176 "电池包8的单体温度176";
CM_ SG_ 2560819336 P8_CellTemp177 "电池包8的单体温度177";
CM_ SG_ 2560819336 P8_CellTemp178 "电池包8的单体温度178";
CM_ SG_ 2560819336 P8_CellTemp179 "电池包8的单体温度179";
CM_ SG_ 2560819336 P8_CellTemp180 "电池包8的单体温度180";
CM_ SG_ 2560884872 P8_CellTemp181 "电池包8的单体温度181";
CM_ SG_ 2560884872 P8_CellTemp182 "电池包8的单体温度182";
CM_ SG_ 2560884872 P8_CellTemp183 "电池包8的单体温度183";
CM_ SG_ 2560884872 P8_CellTemp184 "电池包8的单体温度184";
CM_ SG_ 2560884872 P8_CellTemp185 "电池包8的单体温度185";
CM_ SG_ 2560950408 P8_CellTemp186 "电池包8的单体温度186";
CM_ SG_ 2560950408 P8_CellTemp187 "电池包8的单体温度187";
CM_ SG_ 2560950408 P8_CellTemp188 "电池包8的单体温度188";
CM_ SG_ 2560950408 P8_CellTemp189 "电池包8的单体温度189";
CM_ SG_ 2560950408 P8_CellTemp190 "电池包8的单体温度190";
CM_ SG_ 2561015944 P8_CellTemp191 "电池包8的单体温度191";
CM_ SG_ 2561015944 P8_CellTemp192 "电池包8的单体温度192";
CM_ SG_ 2561015944 P8_DatLen16DbgInfo1 "长度为16的调试信息1";
CM_ SG_ 2561015944 P8_DatLen16DbgInfo2 "长度为16的调试信息2";
CM_ SG_ 2561015944 P8_DatLen16DbgInfo3 "长度为16的调试信息3";
CM_ SG_ 2561015944 P8_DatLen16DbgInfo4 "长度为16的调试信息4";
CM_ SG_ 2550399129 P9_BMSPwrSuplVlt1 "电池包9的BMS供电电源电压1";
CM_ SG_ 2550399129 P9_BMSPwrSuplVlt2 "电池包9的BMS供电电源电压2";
CM_ SG_ 2550399129 P9_ChrgStationAuxPwrSuplVlt "电池包9的快充桩A+电压";
CM_ SG_ 2550399129 P9_BMSKL15ON "电池包9的BMS唤醒信号";
CM_ SG_ 2550399129 P9_DCStepState "电池包9的充电状态机";
CM_ SG_ 2550399129 P9_ExtLvWakeup_28VOnly "电池包9的外部唤醒";
CM_ SG_ 2550464665 P9_PackVltUprLmt "电池包9的电压使用上限";
CM_ SG_ 2550464665 P9_PackVltLoLmt "电池包9的电压使用下限";
CM_ SG_ 2550464665 P9_PackMaxDschrgCrnt "电池包9的最大允许放电电流";
CM_ SG_ 2550464665 P9_PackMaxChrgCrnt "电池包9的最大允许充电电流";
CM_ SG_ 2550530201 P9_PackDschrgPwrLmt "电池包9的放电功率限值";
CM_ SG_ 2550530201 P9_PackDschrgPwrStat "电池包9的放电功率状态";
CM_ SG_ 2550530201 P9_PackChrgPwrLmt "电池包9的充电功率限值";
CM_ SG_ 2550530201 P9_PackChrgPwrStat "电池包9的充电功率状态";
BA_DEF_ BO_  "GenMsgSendType" ENUM  "Cyclic","IfActive","Event";
BA_DEF_ BO_  "GenMsgCycleTime" INT 0 5000;
BA_DEF_ BO_  "VFrameFormat" ENUM  "StandardCAN","ExtendedCAN","reserved","reserved","reserved","reserved","reserved","reserved","reserved","reserved","reserved","reserved","reserved","reserved","StandardCAN_FD","ExtendedCAN_FD";
BA_DEF_ SG_  "GenSigSendType" ENUM  "Cyclic","OnWrite","OnChange","NoSigSendType";
BA_DEF_DEF_  "GenMsgSendType" "Cyclic";
BA_DEF_DEF_  "GenMsgCycleTime" 0;
BA_DEF_DEF_  "GenSigSendType" "Cyclic";
BA_DEF_DEF_  "VFrameFormat" "ExtendedCAN";
BA_ "GenMsgCycleTime" BO_ 2550595703 500;
BA_ "GenMsgCycleTime" BO_ 2550661239 500;
BA_ "GenMsgCycleTime" BO_ 2550726775 500;
BA_ "GenMsgCycleTime" BO_ 2550792311 500;
BA_ "GenMsgCycleTime" BO_ 2550857847 500;
BA_ "GenMsgCycleTime" BO_ 2550923383 500;
BA_ "GenMsgCycleTime" BO_ 2550988919 1000;
BA_ "GenMsgCycleTime" BO_ 2552299639 1000;
BA_ "GenMsgCycleTime" BO_ 2554396791 1000;
BA_ "GenMsgCycleTime" BO_ 2554462327 1000;
BA_ "GenMsgCycleTime" BO_ 2554527863 1000;
BA_ "GenMsgCycleTime" BO_ 2554593399 1000;
BA_ "GenMsgCycleTime" BO_ 2554658935 1000;
BA_ "GenMsgCycleTime" BO_ 2554724471 1000;
BA_ "GenMsgCycleTime" BO_ 2554790007 1000;
BA_ "GenMsgCycleTime" BO_ 2554855543 1000;
BA_ "GenMsgCycleTime" BO_ 2554921079 1000;
BA_ "GenMsgCycleTime" BO_ 2554986615 1000;
BA_ "GenMsgCycleTime" BO_ 2555052151 1000;
BA_ "GenMsgCycleTime" BO_ 2555117687 1000;
BA_ "GenMsgCycleTime" BO_ 2555183223 1000;
BA_ "GenMsgCycleTime" BO_ 2555248759 1000;
BA_ "GenMsgCycleTime" BO_ 2555314295 1000;
BA_ "GenMsgCycleTime" BO_ 2555379831 1000;
BA_ "GenMsgCycleTime" BO_ 2555445367 1000;
BA_ "GenMsgCycleTime" BO_ 2555510903 1000;
BA_ "GenMsgCycleTime" BO_ 2555576439 1000;
BA_ "GenMsgCycleTime" BO_ 2555641975 1000;
BA_ "GenMsgCycleTime" BO_ 2555707511 1000;
BA_ "GenMsgCycleTime" BO_ 2555773047 1000;
BA_ "GenMsgCycleTime" BO_ 2555838583 1000;
BA_ "GenMsgCycleTime" BO_ 2555904119 1000;
BA_ "GenMsgCycleTime" BO_ 2555969655 1000;
BA_ "GenMsgCycleTime" BO_ 2556035191 1000;
BA_ "GenMsgCycleTime" BO_ 2556100727 1000;
BA_ "GenMsgCycleTime" BO_ 2556166263 1000;
BA_ "GenMsgCycleTime" BO_ 2556231799 1000;
BA_ "GenMsgCycleTime" BO_ 2556297335 1000;
BA_ "GenMsgCycleTime" BO_ 2556362871 1000;
BA_ "GenMsgCycleTime" BO_ 2556428407 1000;
BA_ "GenMsgCycleTime" BO_ 2556493943 1000;
BA_ "GenMsgCycleTime" BO_ 2556559479 1000;
BA_ "GenMsgCycleTime" BO_ 2556625015 1000;
BA_ "GenMsgCycleTime" BO_ 2556690551 1000;
BA_ "GenMsgCycleTime" BO_ 2556756087 1000;
BA_ "GenMsgCycleTime" BO_ 2556821623 1000;
BA_ "GenMsgCycleTime" BO_ 2556887159 1000;
BA_ "GenMsgCycleTime" BO_ 2556952695 1000;
BA_ "GenMsgCycleTime" BO_ 2557018231 1000;
BA_ "GenMsgCycleTime" BO_ 2557083767 1000;
BA_ "GenMsgCycleTime" BO_ 2557149303 1000;
BA_ "GenMsgCycleTime" BO_ 2557214839 1000;
BA_ "GenMsgCycleTime" BO_ 2557280375 1000;
BA_ "GenMsgCycleTime" BO_ 2557345911 1000;
BA_ "GenMsgCycleTime" BO_ 2557411447 1000;
BA_ "GenMsgCycleTime" BO_ 2557476983 1000;
BA_ "GenMsgCycleTime" BO_ 2558525559 1000;
BA_ "GenMsgCycleTime" BO_ 2558591095 1000;
BA_ "GenMsgCycleTime" BO_ 2558656631 1000;
BA_ "GenMsgCycleTime" BO_ 2558722167 1000;
BA_ "GenMsgCycleTime" BO_ 2558787703 1000;
BA_ "GenMsgCycleTime" BO_ 2558853239 1000;
BA_ "GenMsgCycleTime" BO_ 2558918775 1000;
BA_ "GenMsgCycleTime" BO_ 2558984311 1000;
BA_ "GenMsgCycleTime" BO_ 2559049847 1000;
BA_ "GenMsgCycleTime" BO_ 2559115383 1000;
BA_ "GenMsgCycleTime" BO_ 2559180919 1000;
BA_ "GenMsgCycleTime" BO_ 2559246455 1000;
BA_ "GenMsgCycleTime" BO_ 2559311991 1000;
BA_ "GenMsgCycleTime" BO_ 2559377527 1000;
BA_ "GenMsgCycleTime" BO_ 2559443063 1000;
BA_ "GenMsgCycleTime" BO_ 2559508599 1000;
BA_ "GenMsgCycleTime" BO_ 2559574135 1000;
BA_ "GenMsgCycleTime" BO_ 2559639671 1000;
BA_ "GenMsgCycleTime" BO_ 2559705207 1000;
BA_ "GenMsgCycleTime" BO_ 2559770743 1000;
BA_ "GenMsgCycleTime" BO_ 2559836279 1000;
BA_ "GenMsgCycleTime" BO_ 2559901815 1000;
BA_ "GenMsgCycleTime" BO_ 2559967351 1000;
BA_ "GenMsgCycleTime" BO_ 2560032887 1000;
BA_ "GenMsgCycleTime" BO_ 2560098423 1000;
BA_ "GenMsgCycleTime" BO_ 2560163959 1000;
BA_ "GenMsgCycleTime" BO_ 2560229495 1000;
BA_ "GenMsgCycleTime" BO_ 2560295031 1000;
BA_ "GenMsgCycleTime" BO_ 2560360567 1000;
BA_ "GenMsgCycleTime" BO_ 2560426103 1000;
BA_ "GenMsgCycleTime" BO_ 2560491639 1000;
BA_ "GenMsgCycleTime" BO_ 2560557175 1000;
BA_ "GenMsgCycleTime" BO_ 2560622711 1000;
BA_ "GenMsgCycleTime" BO_ 2560688247 1000;
BA_ "GenMsgCycleTime" BO_ 2560753783 1000;
BA_ "GenMsgCycleTime" BO_ 2560819319 1000;
BA_ "GenMsgCycleTime" BO_ 2560884855 1000;
BA_ "GenMsgCycleTime" BO_ 2560950391 1000;
BA_ "GenMsgCycleTime" BO_ 2561015927 1000;
BA_ "GenMsgCycleTime" BO_ 2550399112 500;
BA_ "GenMsgCycleTime" BO_ 2550464648 500;
BA_ "GenMsgCycleTime" BO_ 2550530184 500;
BA_ "GenMsgCycleTime" BO_ 2550595720 500;
BA_ "GenMsgCycleTime" BO_ 2550661256 500;
BA_ "GenMsgCycleTime" BO_ 2550726792 500;
BA_ "GenMsgCycleTime" BO_ 2550792328 500;
BA_ "GenMsgCycleTime" BO_ 2550857864 500;
BA_ "GenMsgCycleTime" BO_ 2550923400 500;
BA_ "GenMsgCycleTime" BO_ 2550988936 1000;
BA_ "GenMsgCycleTime" BO_ 2552299656 1000;
BA_ "GenMsgCycleTime" BO_ 2554396808 1000;
BA_ "GenMsgCycleTime" BO_ 2554462344 1000;
BA_ "GenMsgCycleTime" BO_ 2554527880 1000;
BA_ "GenMsgCycleTime" BO_ 2554593416 1000;
BA_ "GenMsgCycleTime" BO_ 2554658952 1000;
BA_ "GenMsgCycleTime" BO_ 2554724488 1000;
BA_ "GenMsgCycleTime" BO_ 2554790024 1000;
BA_ "GenMsgCycleTime" BO_ 2554855560 1000;
BA_ "GenMsgCycleTime" BO_ 2554921096 1000;
BA_ "GenMsgCycleTime" BO_ 2554986632 1000;
BA_ "GenMsgCycleTime" BO_ 2555052168 1000;
BA_ "GenMsgCycleTime" BO_ 2555117704 1000;
BA_ "GenMsgCycleTime" BO_ 2555183240 1000;
BA_ "GenMsgCycleTime" BO_ 2555248776 1000;
BA_ "GenMsgCycleTime" BO_ 2555314312 1000;
BA_ "GenMsgCycleTime" BO_ 2555379848 1000;
BA_ "GenMsgCycleTime" BO_ 2555445384 1000;
BA_ "GenMsgCycleTime" BO_ 2555510920 1000;
BA_ "GenMsgCycleTime" BO_ 2555576456 1000;
BA_ "GenMsgCycleTime" BO_ 2555641992 1000;
BA_ "GenMsgCycleTime" BO_ 2555707528 1000;
BA_ "GenMsgCycleTime" BO_ 2555773064 1000;
BA_ "GenMsgCycleTime" BO_ 2555838600 1000;
BA_ "GenMsgCycleTime" BO_ 2555904136 1000;
BA_ "GenMsgCycleTime" BO_ 2555969672 1000;
BA_ "GenMsgCycleTime" BO_ 2556035208 1000;
BA_ "GenMsgCycleTime" BO_ 2556100744 1000;
BA_ "GenMsgCycleTime" BO_ 2556166280 1000;
BA_ "GenMsgCycleTime" BO_ 2556231816 1000;
BA_ "GenMsgCycleTime" BO_ 2556297352 1000;
BA_ "GenMsgCycleTime" BO_ 2556362888 1000;
BA_ "GenMsgCycleTime" BO_ 2556428424 1000;
BA_ "GenMsgCycleTime" BO_ 2556493960 1000;
BA_ "GenMsgCycleTime" BO_ 2556559496 1000;
BA_ "GenMsgCycleTime" BO_ 2556625032 1000;
BA_ "GenMsgCycleTime" BO_ 2556690568 1000;
BA_ "GenMsgCycleTime" BO_ 2556756104 1000;
BA_ "GenMsgCycleTime" BO_ 2556821640 1000;
BA_ "GenMsgCycleTime" BO_ 2556887176 1000;
BA_ "GenMsgCycleTime" BO_ 2556952712 1000;
BA_ "GenMsgCycleTime" BO_ 2557018248 1000;
BA_ "GenMsgCycleTime" BO_ 2557083784 1000;
BA_ "GenMsgCycleTime" BO_ 2557149320 1000;
BA_ "GenMsgCycleTime" BO_ 2557214856 1000;
BA_ "GenMsgCycleTime" BO_ 2557280392 1000;
BA_ "GenMsgCycleTime" BO_ 2557345928 1000;
BA_ "GenMsgCycleTime" BO_ 2557411464 1000;
BA_ "GenMsgCycleTime" BO_ 2557477000 1000;
BA_ "GenMsgCycleTime" BO_ 2558525576 1000;
BA_ "GenMsgCycleTime" BO_ 2558591112 1000;
BA_ "GenMsgCycleTime" BO_ 2558656648 1000;
BA_ "GenMsgCycleTime" BO_ 2558722184 1000;
BA_ "GenMsgCycleTime" BO_ 2558787720 1000;
BA_ "GenMsgCycleTime" BO_ 2558853256 1000;
BA_ "GenMsgCycleTime" BO_ 2558918792 1000;
BA_ "GenMsgCycleTime" BO_ 2558984328 1000;
BA_ "GenMsgCycleTime" BO_ 2559049864 1000;
BA_ "GenMsgCycleTime" BO_ 2559115400 1000;
BA_ "GenMsgCycleTime" BO_ 2559180936 1000;
BA_ "GenMsgCycleTime" BO_ 2559246472 1000;
BA_ "GenMsgCycleTime" BO_ 2559312008 1000;
BA_ "GenMsgCycleTime" BO_ 2559377544 1000;
BA_ "GenMsgCycleTime" BO_ 2559443080 1000;
BA_ "GenMsgCycleTime" BO_ 2559508616 1000;
BA_ "GenMsgCycleTime" BO_ 2559574152 1000;
BA_ "GenMsgCycleTime" BO_ 2559639688 1000;
BA_ "GenMsgCycleTime" BO_ 2559705224 1000;
BA_ "GenMsgCycleTime" BO_ 2559770760 1000;
BA_ "GenMsgCycleTime" BO_ 2559836296 1000;
BA_ "GenMsgCycleTime" BO_ 2559901832 1000;
BA_ "GenMsgCycleTime" BO_ 2559967368 1000;
BA_ "GenMsgCycleTime" BO_ 2560032904 1000;
BA_ "GenMsgCycleTime" BO_ 2560098440 1000;
BA_ "GenMsgCycleTime" BO_ 2560163976 1000;
BA_ "GenMsgCycleTime" BO_ 2560229512 1000;
BA_ "GenMsgCycleTime" BO_ 2560295048 1000;
BA_ "GenMsgCycleTime" BO_ 2560360584 1000;
BA_ "GenMsgCycleTime" BO_ 2560426120 1000;
BA_ "GenMsgCycleTime" BO_ 2560491656 1000;
BA_ "GenMsgCycleTime" BO_ 2560557192 1000;
BA_ "GenMsgCycleTime" BO_ 2560622728 1000;
BA_ "GenMsgCycleTime" BO_ 2560688264 1000;
BA_ "GenMsgCycleTime" BO_ 2560753800 1000;
BA_ "GenMsgCycleTime" BO_ 2560819336 1000;
BA_ "GenMsgCycleTime" BO_ 2560884872 1000;
BA_ "GenMsgCycleTime" BO_ 2560950408 1000;
BA_ "GenMsgCycleTime" BO_ 2561015944 1000;
BA_ "GenMsgCycleTime" BO_ 2550399129 500;
BA_ "GenMsgCycleTime" BO_ 2550464665 500;
BA_ "GenMsgCycleTime" BO_ 2550530201 500;
VAL_ 2550595703 P7_ChrgrCplrStat 01 "Connected" 00 "Disconnected" ;
VAL_ 2550595703 P7_HVBattChrgSysStatus 04 "Aborted" 03 "Complete" 02 "Active" 01 "Initialization" 00 "Default" ;
VAL_ 2550857847 P7_CellOverVoltage 03 "Level 3" 02 "Level 2" 01 "Level 1" 00 "No Fault" ;
VAL_ 2550857847 P7_CellUnderVoltage 03 "Level 3" 02 "Level 2" 01 "Level 1" 00 "No Fault" ;
VAL_ 2550857847 P7_CellVoltageDiffHi 01 "Fault" 00 "No Fault" ;
VAL_ 2550857847 P7_PackOverVoltage 03 "Level 3" 02 "Level 2" 01 "Level 1" 00 "No Fault" ;
VAL_ 2550857847 P7_PackUnderVoltage 03 "Level 3" 02 "Level 2" 01 "Level 1" 00 "No Fault" ;
VAL_ 2550857847 P7_CellOverTemp 03 "Level 3" 02 "Level 2" 01 "Level 1" 00 "No Fault" ;
VAL_ 2550857847 P7_CellTempLow 01 "Fault" 00 "No Fault" ;
VAL_ 2550857847 P7_CellTempDiffHi 01 "Fault" 00 "No Fault" ;
VAL_ 2550857847 P7_PackDschrgCrntHi 03 "Level 3" 02 "Level 2" 01 "Level 1" 00 "No Fault" ;
VAL_ 2550857847 P7_PackChrgCrntHi 03 "Level 3" 02 "Level 2" 01 "Level 1" 00 "No Fault" ;
VAL_ 2550857847 P7_PackCrnSnsr1OffsetHi 01 "Fault" 00 "No Fault" ;
VAL_ 2550857847 P7_HVIsolFlt 03 "Level 3" 02 "Level 2" 01 "Level 1" 00 "No Fault" ;
VAL_ 2550857847 P7_HVILFlt 01 "Fault" 00 "No Fault" ;
VAL_ 2550857847 P7_ThrmlRunaway 01 "Fault" 00 "No Fault" ;
VAL_ 2550857847 P7_CellVoltInvalid 01 "Fault" 00 "No Fault" ;
VAL_ 2550857847 P7_CellTempInvalid 01 "Fault" 00 "No Fault" ;
VAL_ 2550857847 P7_DaisyChainComFlt 01 "Fault" 00 "No Fault" ;
VAL_ 2550857847 P7_PackVoltRatFlt 01 "Fault" 00 "No Fault" ;
VAL_ 2550857847 P7_CrntSnsr1Invalid 01 "Fault" 00 "No Fault" ;
VAL_ 2550857847 P7_CrntSnsr1OOR 01 "Fault" 00 "No Fault" ;
VAL_ 2550857847 P7_CrntSnsr2Invalid 01 "Fault" 00 "No Fault" ;
VAL_ 2550857847 P7_CrntSnsr2OOR 01 "Fault" 00 "No Fault" ;
VAL_ 2550857847 P7_PackCrnSnsr2OffsetHi 01 "Fault" 00 "No Fault" ;
VAL_ 2550857847 P7_OutofEnergy 01 "Fault" 00 "No Fault" ;
VAL_ 2550857847 P7_IsolDetCircErr 01 "Fault" 00 "No Fault" ;
VAL_ 2550857847 P7_HVILCircShortToGND 01 "Fault" 00 "No Fault" ;
VAL_ 2550857847 P7_HVILCircShortToPwr 01 "Fault" 00 "No Fault" ;
VAL_ 2550923383 P7_MainPosCntctrStkClsd 01 "Fault" 00 "No Fault" ;
VAL_ 2550923383 P7_MainPosCntctrStkOpn 01 "Fault" 00 "No Fault" ;
VAL_ 2550923383 P7_MainNegCntctr1StkClsd 01 "Fault" 00 "No Fault" ;
VAL_ 2550923383 P7_MainNegCntctr1StkOpn 01 "Fault" 00 "No Fault" ;
VAL_ 2550923383 P7_MainNegCntctr2StkClsd 01 "Fault" 00 "No Fault" ;
VAL_ 2550923383 P7_MainNegCntctr2StkOpn 01 "Fault" 00 "No Fault" ;
VAL_ 2550923383 P7_PrechargTmOut 01 "Fault" 00 "No Fault" ;
VAL_ 2550923383 P7_PrechrgCrntHi 01 "Fault" 00 "No Fault" ;
VAL_ 2550923383 P7_ChrgCplrPosTempHi 01 "Fault" 00 "No Fault" ;
VAL_ 2550923383 P7_ChrgCplrNegTempHi 01 "Fault" 00 "No Fault" ;
VAL_ 2550923383 P7_BMSPwrSuplVlt1Hi 01 "Fault" 00 "No Fault" ;
VAL_ 2550923383 P7_BMSPwrSuplVlt1Lo 01 "Fault" 00 "No Fault" ;
VAL_ 2550923383 P7_BMSPwrSuplVlt2Hi 01 "Fault" 00 "No Fault" ;
VAL_ 2550923383 P7_BMSPwrSuplVlt2Lo 01 "Fault" 00 "No Fault" ;
VAL_ 2550923383 P7_CntctrCirPwrSuplVltLo 01 "Fault" 00 "No Fault" ;
VAL_ 2550923383 P7_CntctrCirPwrSuplVltHi 01 "Fault" 00 "No Fault" ;
VAL_ 2550923383 P7_CAN1BusOff 01 "Fault" 00 "No Fault" ;
VAL_ 2550923383 P7_CAN1BusTmOut 01 "Fault" 00 "No Fault" ;
VAL_ 2550923383 P7_CAN2BusOff 01 "Fault" 00 "No Fault" ;
VAL_ 2550923383 P7_CAN2BusTmOut 01 "Fault" 00 "No Fault" ;
VAL_ 2550923383 P7_CellBalCircTempHi 01 "Fault" 00 "No Fault" ;
VAL_ 2550923383 P7_ClntInTempHi 01 "Fault" 00 "No Fault" ;
VAL_ 2550923383 P7_ClntOutTempHi 01 "Fault" 00 "No Fault" ;
VAL_ 2550923383 P7_CellExtrmUdrVolt 01 "Fault" 00 "No Fault" ;
VAL_ 2550923383 P7_CellExtrmOvrVolt 01 "Fault" 00 "No Fault" ;
VAL_ 2550923383 P7_Branch1DischrgCrntHi  01 "Fault" 00 "No Fault" ;
VAL_ 2550923383 P7_Branch2DischrgCrntHi  01 "Fault" 00 "No Fault" ;
VAL_ 2550923383 P7_Branch1ChrgCrntHi  01 "Fault" 00 "No Fault" ;
VAL_ 2550923383 P7_Branch2ChrgCrntHi  01 "Fault" 00 "No Fault" ;
VAL_ 2550923383 P7_InitFailed 01 "Fault" 00 "No Fault" ;
VAL_ 2554396791 P7_BalSwCell1 01 "Active" 00 "Inactive" ;
VAL_ 2554396791 P7_BalSwCell2 01 "Active" 00 "Inactive" ;
VAL_ 2554396791 P7_BalSwCell3 01 "Active" 00 "Inactive" ;
VAL_ 2554396791 P7_BalSwCell4 01 "Active" 00 "Inactive" ;
VAL_ 2554462327 P7_BalSwCell5 01 "Active" 00 "Inactive" ;
VAL_ 2554462327 P7_BalSwCell6 01 "Active" 00 "Inactive" ;
VAL_ 2554462327 P7_BalSwCell7 01 "Active" 00 "Inactive" ;
VAL_ 2554462327 P7_BalSwCell8 01 "Active" 00 "Inactive" ;
VAL_ 2554527863 P7_BalSwCell9 01 "Active" 00 "Inactive" ;
VAL_ 2554527863 P7_BalSwCell10 01 "Active" 00 "Inactive" ;
VAL_ 2554527863 P7_BalSwCell11 01 "Active" 00 "Inactive" ;
VAL_ 2554527863 P7_BalSwCell12 01 "Active" 00 "Inactive" ;
VAL_ 2554593399 P7_BalSwCell13 01 "Active" 00 "Inactive" ;
VAL_ 2554593399 P7_BalSwCell14 01 "Active" 00 "Inactive" ;
VAL_ 2554593399 P7_BalSwCell15 01 "Active" 00 "Inactive" ;
VAL_ 2554593399 P7_BalSwCell16 01 "Active" 00 "Inactive" ;
VAL_ 2554658935 P7_BalSwCell17 01 "Active" 00 "Inactive" ;
VAL_ 2554658935 P7_BalSwCell18 01 "Active" 00 "Inactive" ;
VAL_ 2554658935 P7_BalSwCell19 01 "Active" 00 "Inactive" ;
VAL_ 2554658935 P7_BalSwCell20 01 "Active" 00 "Inactive" ;
VAL_ 2554724471 P7_BalSwCell21 01 "Active" 00 "Inactive" ;
VAL_ 2554724471 P7_BalSwCell22 01 "Active" 00 "Inactive" ;
VAL_ 2554724471 P7_BalSwCell23 01 "Active" 00 "Inactive" ;
VAL_ 2554724471 P7_BalSwCell24 01 "Active" 00 "Inactive" ;
VAL_ 2554790007 P7_BalSwCell25 01 "Active" 00 "Inactive" ;
VAL_ 2554790007 P7_BalSwCell26 01 "Active" 00 "Inactive" ;
VAL_ 2554790007 P7_BalSwCell27 01 "Active" 00 "Inactive" ;
VAL_ 2554790007 P7_BalSwCell28 01 "Active" 00 "Inactive" ;
VAL_ 2554855543 P7_BalSwCell29 01 "Active" 00 "Inactive" ;
VAL_ 2554855543 P7_BalSwCell30 01 "Active" 00 "Inactive" ;
VAL_ 2554855543 P7_BalSwCell31 01 "Active" 00 "Inactive" ;
VAL_ 2554855543 P7_BalSwCell32 01 "Active" 00 "Inactive" ;
VAL_ 2554921079 P7_BalSwCell33 01 "Active" 00 "Inactive" ;
VAL_ 2554921079 P7_BalSwCell34 01 "Active" 00 "Inactive" ;
VAL_ 2554921079 P7_BalSwCell35 01 "Active" 00 "Inactive" ;
VAL_ 2554921079 P7_BalSwCell36 01 "Active" 00 "Inactive" ;
VAL_ 2554986615 P7_BalSwCell37 01 "Active" 00 "Inactive" ;
VAL_ 2554986615 P7_BalSwCell38 01 "Active" 00 "Inactive" ;
VAL_ 2554986615 P7_BalSwCell39 01 "Active" 00 "Inactive" ;
VAL_ 2554986615 P7_BalSwCell40 01 "Active" 00 "Inactive" ;
VAL_ 2555052151 P7_BalSwCell41 01 "Active" 00 "Inactive" ;
VAL_ 2555052151 P7_BalSwCell42 01 "Active" 00 "Inactive" ;
VAL_ 2555052151 P7_BalSwCell43 01 "Active" 00 "Inactive" ;
VAL_ 2555052151 P7_BalSwCell44 01 "Active" 00 "Inactive" ;
VAL_ 2555117687 P7_BalSwCell45 01 "Active" 00 "Inactive" ;
VAL_ 2555117687 P7_BalSwCell46 01 "Active" 00 "Inactive" ;
VAL_ 2555117687 P7_BalSwCell47 01 "Active" 00 "Inactive" ;
VAL_ 2555117687 P7_BalSwCell48 01 "Active" 00 "Inactive" ;
VAL_ 2555183223 P7_BalSwCell49 01 "Active" 00 "Inactive" ;
VAL_ 2555183223 P7_BalSwCell50 01 "Active" 00 "Inactive" ;
VAL_ 2555183223 P7_BalSwCell51 01 "Active" 00 "Inactive" ;
VAL_ 2555183223 P7_BalSwCell52 01 "Active" 00 "Inactive" ;
VAL_ 2555248759 P7_BalSwCell53 01 "Active" 00 "Inactive" ;
VAL_ 2555248759 P7_BalSwCell54 01 "Active" 00 "Inactive" ;
VAL_ 2555248759 P7_BalSwCell55 01 "Active" 00 "Inactive" ;
VAL_ 2555248759 P7_BalSwCell56 01 "Active" 00 "Inactive" ;
VAL_ 2555314295 P7_BalSwCell57 01 "Active" 00 "Inactive" ;
VAL_ 2555314295 P7_BalSwCell58 01 "Active" 00 "Inactive" ;
VAL_ 2555314295 P7_BalSwCell59 01 "Active" 00 "Inactive" ;
VAL_ 2555314295 P7_BalSwCell60 01 "Active" 00 "Inactive" ;
VAL_ 2555379831 P7_BalSwCell61 01 "Active" 00 "Inactive" ;
VAL_ 2555379831 P7_BalSwCell62 01 "Active" 00 "Inactive" ;
VAL_ 2555379831 P7_BalSwCell63 01 "Active" 00 "Inactive" ;
VAL_ 2555379831 P7_BalSwCell64 01 "Active" 00 "Inactive" ;
VAL_ 2555445367 P7_BalSwCell65 01 "Active" 00 "Inactive" ;
VAL_ 2555445367 P7_BalSwCell66 01 "Active" 00 "Inactive" ;
VAL_ 2555445367 P7_BalSwCell67 01 "Active" 00 "Inactive" ;
VAL_ 2555445367 P7_BalSwCell68 01 "Active" 00 "Inactive" ;
VAL_ 2555510903 P7_BalSwCell69 01 "Active" 00 "Inactive" ;
VAL_ 2555510903 P7_BalSwCell70 01 "Active" 00 "Inactive" ;
VAL_ 2555510903 P7_BalSwCell71 01 "Active" 00 "Inactive" ;
VAL_ 2555510903 P7_BalSwCell72 01 "Active" 00 "Inactive" ;
VAL_ 2555576439 P7_BalSwCell73 01 "Active" 00 "Inactive" ;
VAL_ 2555576439 P7_BalSwCell74 01 "Active" 00 "Inactive" ;
VAL_ 2555576439 P7_BalSwCell75 01 "Active" 00 "Inactive" ;
VAL_ 2555576439 P7_BalSwCell76 01 "Active" 00 "Inactive" ;
VAL_ 2555641975 P7_BalSwCell77 01 "Active" 00 "Inactive" ;
VAL_ 2555641975 P7_BalSwCell78 01 "Active" 00 "Inactive" ;
VAL_ 2555641975 P7_BalSwCell79 01 "Active" 00 "Inactive" ;
VAL_ 2555641975 P7_BalSwCell80 01 "Active" 00 "Inactive" ;
VAL_ 2555707511 P7_BalSwCell81 01 "Active" 00 "Inactive" ;
VAL_ 2555707511 P7_BalSwCell82 01 "Active" 00 "Inactive" ;
VAL_ 2555707511 P7_BalSwCell83 01 "Active" 00 "Inactive" ;
VAL_ 2555707511 P7_BalSwCell84 01 "Active" 00 "Inactive" ;
VAL_ 2555773047 P7_BalSwCell85 01 "Active" 00 "Inactive" ;
VAL_ 2555773047 P7_BalSwCell86 01 "Active" 00 "Inactive" ;
VAL_ 2555773047 P7_BalSwCell87 01 "Active" 00 "Inactive" ;
VAL_ 2555773047 P7_BalSwCell88 01 "Active" 00 "Inactive" ;
VAL_ 2555838583 P7_BalSwCell89 01 "Active" 00 "Inactive" ;
VAL_ 2555838583 P7_BalSwCell90 01 "Active" 00 "Inactive" ;
VAL_ 2555838583 P7_BalSwCell91 01 "Active" 00 "Inactive" ;
VAL_ 2555838583 P7_BalSwCell92 01 "Active" 00 "Inactive" ;
VAL_ 2555904119 P7_BalSwCell93 01 "Active" 00 "Inactive" ;
VAL_ 2555904119 P7_BalSwCell94 01 "Active" 00 "Inactive" ;
VAL_ 2555904119 P7_BalSwCell95 01 "Active" 00 "Inactive" ;
VAL_ 2555904119 P7_BalSwCell96 01 "Active" 00 "Inactive" ;
VAL_ 2555969655 P7_BalSwCell97 01 "Active" 00 "Inactive" ;
VAL_ 2555969655 P7_BalSwCell98 01 "Active" 00 "Inactive" ;
VAL_ 2555969655 P7_BalSwCell99 01 "Active" 00 "Inactive" ;
VAL_ 2555969655 P7_BalSwCell100 01 "Active" 00 "Inactive" ;
VAL_ 2556035191 P7_BalSwCell101 01 "Active" 00 "Inactive" ;
VAL_ 2556035191 P7_BalSwCell102 01 "Active" 00 "Inactive" ;
VAL_ 2556035191 P7_BalSwCell103 01 "Active" 00 "Inactive" ;
VAL_ 2556035191 P7_BalSwCell104 01 "Active" 00 "Inactive" ;
VAL_ 2556100727 P7_BalSwCell105 01 "Active" 00 "Inactive" ;
VAL_ 2556100727 P7_BalSwCell106 01 "Active" 00 "Inactive" ;
VAL_ 2556100727 P7_BalSwCell107 01 "Active" 00 "Inactive" ;
VAL_ 2556100727 P7_BalSwCell108 01 "Active" 00 "Inactive" ;
VAL_ 2556166263 P7_BalSwCell109 01 "Active" 00 "Inactive" ;
VAL_ 2556166263 P7_BalSwCell110 01 "Active" 00 "Inactive" ;
VAL_ 2556166263 P7_BalSwCell111 01 "Active" 00 "Inactive" ;
VAL_ 2556166263 P7_BalSwCell112 01 "Active" 00 "Inactive" ;
VAL_ 2556231799 P7_BalSwCell113 01 "Active" 00 "Inactive" ;
VAL_ 2556231799 P7_BalSwCell114 01 "Active" 00 "Inactive" ;
VAL_ 2556231799 P7_BalSwCell115 01 "Active" 00 "Inactive" ;
VAL_ 2556231799 P7_BalSwCell116 01 "Active" 00 "Inactive" ;
VAL_ 2556297335 P7_BalSwCell117 01 "Active" 00 "Inactive" ;
VAL_ 2556297335 P7_BalSwCell118 01 "Active" 00 "Inactive" ;
VAL_ 2556297335 P7_BalSwCell119 01 "Active" 00 "Inactive" ;
VAL_ 2556297335 P7_BalSwCell120 01 "Active" 00 "Inactive" ;
VAL_ 2556362871 P7_BalSwCell121 01 "Active" 00 "Inactive" ;
VAL_ 2556362871 P7_BalSwCell122 01 "Active" 00 "Inactive" ;
VAL_ 2556362871 P7_BalSwCell123 01 "Active" 00 "Inactive" ;
VAL_ 2556362871 P7_BalSwCell124 01 "Active" 00 "Inactive" ;
VAL_ 2556428407 P7_BalSwCell125 01 "Active" 00 "Inactive" ;
VAL_ 2556428407 P7_BalSwCell126 01 "Active" 00 "Inactive" ;
VAL_ 2556428407 P7_BalSwCell127 01 "Active" 00 "Inactive" ;
VAL_ 2556428407 P7_BalSwCell128 01 "Active" 00 "Inactive" ;
VAL_ 2556493943 P7_BalSwCell129 01 "Active" 00 "Inactive" ;
VAL_ 2556493943 P7_BalSwCell130 01 "Active" 00 "Inactive" ;
VAL_ 2556493943 P7_BalSwCell131 01 "Active" 00 "Inactive" ;
VAL_ 2556493943 P7_BalSwCell132 01 "Active" 00 "Inactive" ;
VAL_ 2556559479 P7_BalSwCell133 01 "Active" 00 "Inactive" ;
VAL_ 2556559479 P7_BalSwCell134 01 "Active" 00 "Inactive" ;
VAL_ 2556559479 P7_BalSwCell135 01 "Active" 00 "Inactive" ;
VAL_ 2556559479 P7_BalSwCell136 01 "Active" 00 "Inactive" ;
VAL_ 2556625015 P7_BalSwCell137 01 "Active" 00 "Inactive" ;
VAL_ 2556625015 P7_BalSwCell138 01 "Active" 00 "Inactive" ;
VAL_ 2556625015 P7_BalSwCell139 01 "Active" 00 "Inactive" ;
VAL_ 2556625015 P7_BalSwCell140 01 "Active" 00 "Inactive" ;
VAL_ 2556690551 P7_BalSwCell141 01 "Active" 00 "Inactive" ;
VAL_ 2556690551 P7_BalSwCell142 01 "Active" 00 "Inactive" ;
VAL_ 2556690551 P7_BalSwCell143 01 "Active" 00 "Inactive" ;
VAL_ 2556690551 P7_BalSwCell144 01 "Active" 00 "Inactive" ;
VAL_ 2556756087 P7_BalSwCell145 01 "Active" 00 "Inactive" ;
VAL_ 2556756087 P7_BalSwCell146 01 "Active" 00 "Inactive" ;
VAL_ 2556756087 P7_BalSwCell147 01 "Active" 00 "Inactive" ;
VAL_ 2556756087 P7_BalSwCell148 01 "Active" 00 "Inactive" ;
VAL_ 2556821623 P7_BalSwCell149 01 "Active" 00 "Inactive" ;
VAL_ 2556821623 P7_BalSwCell150 01 "Active" 00 "Inactive" ;
VAL_ 2556821623 P7_BalSwCell151 01 "Active" 00 "Inactive" ;
VAL_ 2556821623 P7_BalSwCell152 01 "Active" 00 "Inactive" ;
VAL_ 2556887159 P7_BalSwCell153 01 "Active" 00 "Inactive" ;
VAL_ 2556887159 P7_BalSwCell154 01 "Active" 00 "Inactive" ;
VAL_ 2556887159 P7_BalSwCell155 01 "Active" 00 "Inactive" ;
VAL_ 2556887159 P7_BalSwCell156 01 "Active" 00 "Inactive" ;
VAL_ 2556952695 P7_BalSwCell157 01 "Active" 00 "Inactive" ;
VAL_ 2556952695 P7_BalSwCell158 01 "Active" 00 "Inactive" ;
VAL_ 2556952695 P7_BalSwCell159 01 "Active" 00 "Inactive" ;
VAL_ 2556952695 P7_BalSwCell160 01 "Active" 00 "Inactive" ;
VAL_ 2557018231 P7_BalSwCell161 01 "Active" 00 "Inactive" ;
VAL_ 2557018231 P7_BalSwCell162 01 "Active" 00 "Inactive" ;
VAL_ 2557018231 P7_BalSwCell163 01 "Active" 00 "Inactive" ;
VAL_ 2557018231 P7_BalSwCell164 01 "Active" 00 "Inactive" ;
VAL_ 2557083767 P7_BalSwCell165 01 "Active" 00 "Inactive" ;
VAL_ 2557083767 P7_BalSwCell166 01 "Active" 00 "Inactive" ;
VAL_ 2557083767 P7_BalSwCell167 01 "Active" 00 "Inactive" ;
VAL_ 2557083767 P7_BalSwCell168 01 "Active" 00 "Inactive" ;
VAL_ 2557149303 P7_BalSwCell169 01 "Active" 00 "Inactive" ;
VAL_ 2557149303 P7_BalSwCell170 01 "Active" 00 "Inactive" ;
VAL_ 2557149303 P7_BalSwCell171 01 "Active" 00 "Inactive" ;
VAL_ 2557149303 P7_BalSwCell172 01 "Active" 00 "Inactive" ;
VAL_ 2557214839 P7_BalSwCell173 01 "Active" 00 "Inactive" ;
VAL_ 2557214839 P7_BalSwCell174 01 "Active" 00 "Inactive" ;
VAL_ 2557214839 P7_BalSwCell175 01 "Active" 00 "Inactive" ;
VAL_ 2557214839 P7_BalSwCell176 01 "Active" 00 "Inactive" ;
VAL_ 2557280375 P7_BalSwCell177 01 "Active" 00 "Inactive" ;
VAL_ 2557280375 P7_BalSwCell178 01 "Active" 00 "Inactive" ;
VAL_ 2557280375 P7_BalSwCell179 01 "Active" 00 "Inactive" ;
VAL_ 2557280375 P7_BalSwCell180 01 "Active" 00 "Inactive" ;
VAL_ 2557345911 P7_BalSwCell181 01 "Active" 00 "Inactive" ;
VAL_ 2557345911 P7_BalSwCell182 01 "Active" 00 "Inactive" ;
VAL_ 2557345911 P7_BalSwCell183 01 "Active" 00 "Inactive" ;
VAL_ 2557345911 P7_BalSwCell184 01 "Active" 00 "Inactive" ;
VAL_ 2557411447 P7_BalSwCell185 01 "Active" 00 "Inactive" ;
VAL_ 2557411447 P7_BalSwCell186 01 "Active" 00 "Inactive" ;
VAL_ 2557411447 P7_BalSwCell187 01 "Active" 00 "Inactive" ;
VAL_ 2557411447 P7_BalSwCell188 01 "Active" 00 "Inactive" ;
VAL_ 2557476983 P7_BalSwCell189 01 "Active" 00 "Inactive" ;
VAL_ 2557476983 P7_BalSwCell190 01 "Active" 00 "Inactive" ;
VAL_ 2557476983 P7_BalSwCell191 01 "Active" 00 "Inactive" ;
VAL_ 2557476983 P7_BalSwCell192 01 "Active" 00 "Inactive" ;
VAL_ 2550399112 P8_BMSKL15ON 01 "On" 00 "Off" ;
VAL_ 2550530184 P8_PackDschrgPwrStat 02 "鎸佺画鏀剧數鍔熺巼" 01 "30s鏀剧數鍔熺巼" 00 "10s鏀剧數鍔熺巼" ;
VAL_ 2550530184 P8_PackChrgPwrStat 02 "鎸佺画鍏呯數鍔熺巼" 01 "30s鍏呯數鍔熺巼" 00 "10s鍏呯數鍔熺巼" ;
VAL_ 2550595720 P8_ChrgrCplrStat 01 "Connected" 00 "Disconnected" ;
VAL_ 2550595720 P8_HVBattChrgSysStatus 04 "Aborted" 03 "Complete" 02 "Active" 01 "Initialization" 00 "Default" ;
VAL_ 2550857864 P8_CellOverVoltage 03 "Level 3" 02 "Level 2" 01 "Level 1" 00 "No Fault" ;
VAL_ 2550857864 P8_CellUnderVoltage 03 "Level 3" 02 "Level 2" 01 "Level 1" 00 "No Fault" ;
VAL_ 2550857864 P8_CellVoltageDiffHi 01 "Fault" 00 "No Fault" ;
VAL_ 2550857864 P8_PackOverVoltage 03 "Level 3" 02 "Level 2" 01 "Level 1" 00 "No Fault" ;
VAL_ 2550857864 P8_PackUnderVoltage 03 "Level 3" 02 "Level 2" 01 "Level 1" 00 "No Fault" ;
VAL_ 2550857864 P8_CellOverTemp 03 "Level 3" 02 "Level 2" 01 "Level 1" 00 "No Fault" ;
VAL_ 2550857864 P8_CellTempLow 01 "Fault" 00 "No Fault" ;
VAL_ 2550857864 P8_CellTempDiffHi 01 "Fault" 00 "No Fault" ;
VAL_ 2550857864 P8_PackDschrgCrntHi 03 "Level 3" 02 "Level 2" 01 "Level 1" 00 "No Fault" ;
VAL_ 2550857864 P8_PackChrgCrntHi 03 "Level 3" 02 "Level 2" 01 "Level 1" 00 "No Fault" ;
VAL_ 2550857864 P8_PackCrnSnsr1OffsetHi 01 "Fault" 00 "No Fault" ;
VAL_ 2550857864 P8_HVIsolFlt 03 "Level 3" 02 "Level 2" 01 "Level 1" 00 "No Fault" ;
VAL_ 2550857864 P8_HVILFlt 01 "Fault" 00 "No Fault" ;
VAL_ 2550857864 P8_ThrmlRunaway 01 "Fault" 00 "No Fault" ;
VAL_ 2550857864 P8_CellVoltInvalid 01 "Fault" 00 "No Fault" ;
VAL_ 2550857864 P8_CellTempInvalid 01 "Fault" 00 "No Fault" ;
VAL_ 2550857864 P8_DaisyChainComFlt 01 "Fault" 00 "No Fault" ;
VAL_ 2550857864 P8_PackVoltRatFlt 01 "Fault" 00 "No Fault" ;
VAL_ 2550857864 P8_CrntSnsr1Invalid 01 "Fault" 00 "No Fault" ;
VAL_ 2550857864 P8_CrntSnsr1OOR 01 "Fault" 00 "No Fault" ;
VAL_ 2550857864 P8_CrntSnsr2Invalid 01 "Fault" 00 "No Fault" ;
VAL_ 2550857864 P8_CrntSnsr2OOR 01 "Fault" 00 "No Fault" ;
VAL_ 2550857864 P8_PackCrnSnsr2OffsetHi 01 "Fault" 00 "No Fault" ;
VAL_ 2550857864 P8_OutofEnergy 01 "Fault" 00 "No Fault" ;
VAL_ 2550857864 P8_IsolDetCircErr 01 "Fault" 00 "No Fault" ;
VAL_ 2550857864 P8_HVILCircShortToGND 01 "Fault" 00 "No Fault" ;
VAL_ 2550857864 P8_HVILCircShortToPwr 01 "Fault" 00 "No Fault" ;
VAL_ 2550923400 P8_MainPosCntctrStkClsd 01 "Fault" 00 "No Fault" ;
VAL_ 2550923400 P8_MainPosCntctrStkOpn 01 "Fault" 00 "No Fault" ;
VAL_ 2550923400 P8_MainNegCntctr1StkClsd 01 "Fault" 00 "No Fault" ;
VAL_ 2550923400 P8_MainNegCntctr1StkOpn 01 "Fault" 00 "No Fault" ;
VAL_ 2550923400 P8_MainNegCntctr2StkClsd 01 "Fault" 00 "No Fault" ;
VAL_ 2550923400 P8_MainNegCntctr2StkOpn 01 "Fault" 00 "No Fault" ;
VAL_ 2550923400 P8_PrechargTmOut 01 "Fault" 00 "No Fault" ;
VAL_ 2550923400 P8_PrechrgCrntHi 01 "Fault" 00 "No Fault" ;
VAL_ 2550923400 P8_ChrgCplrPosTempHi 01 "Fault" 00 "No Fault" ;
VAL_ 2550923400 P8_ChrgCplrNegTempHi 01 "Fault" 00 "No Fault" ;
VAL_ 2550923400 P8_BMSPwrSuplVlt1Hi 01 "Fault" 00 "No Fault" ;
VAL_ 2550923400 P8_BMSPwrSuplVlt1Lo 01 "Fault" 00 "No Fault" ;
VAL_ 2550923400 P8_BMSPwrSuplVlt2Hi 01 "Fault" 00 "No Fault" ;
VAL_ 2550923400 P8_BMSPwrSuplVlt2Lo 01 "Fault" 00 "No Fault" ;
VAL_ 2550923400 P8_CntctrCirPwrSuplVltLo 01 "Fault" 00 "No Fault" ;
VAL_ 2550923400 P8_CntctrCirPwrSuplVltHi 01 "Fault" 00 "No Fault" ;
VAL_ 2550923400 P8_CAN1BusOff 01 "Fault" 00 "No Fault" ;
VAL_ 2550923400 P8_CAN1BusTmOut 01 "Fault" 00 "No Fault" ;
VAL_ 2550923400 P8_CAN2BusOff 01 "Fault" 00 "No Fault" ;
VAL_ 2550923400 P8_CAN2BusTmOut 01 "Fault" 00 "No Fault" ;
VAL_ 2550923400 P8_CellBalCircTempHi 01 "Fault" 00 "No Fault" ;
VAL_ 2550923400 P8_ClntInTempHi 01 "Fault" 00 "No Fault" ;
VAL_ 2550923400 P8_ClntOutTempHi 01 "Fault" 00 "No Fault" ;
VAL_ 2550923400 P8_CellExtrmUdrVolt 01 "Fault" 00 "No Fault" ;
VAL_ 2550923400 P8_CellExtrmOvrVolt 01 "Fault" 00 "No Fault" ;
VAL_ 2550923400 P8_Branch1DischrgCrntHi  01 "Fault" 00 "No Fault" ;
VAL_ 2550923400 P8_Branch2DischrgCrntHi  01 "Fault" 00 "No Fault" ;
VAL_ 2550923400 P8_Branch1ChrgCrntHi  01 "Fault" 00 "No Fault" ;
VAL_ 2550923400 P8_Branch2ChrgCrntHi  01 "Fault" 00 "No Fault" ;
VAL_ 2550923400 P8_InitFailed 01 "Fault" 00 "No Fault" ;
VAL_ 2554396808 P8_BalSwCell1 01 "Active" 00 "Inactive" ;
VAL_ 2554396808 P8_BalSwCell2 01 "Active" 00 "Inactive" ;
VAL_ 2554396808 P8_BalSwCell3 01 "Active" 00 "Inactive" ;
VAL_ 2554396808 P8_BalSwCell4 01 "Active" 00 "Inactive" ;
VAL_ 2554462344 P8_BalSwCell5 01 "Active" 00 "Inactive" ;
VAL_ 2554462344 P8_BalSwCell6 01 "Active" 00 "Inactive" ;
VAL_ 2554462344 P8_BalSwCell7 01 "Active" 00 "Inactive" ;
VAL_ 2554462344 P8_BalSwCell8 01 "Active" 00 "Inactive" ;
VAL_ 2554527880 P8_BalSwCell9 01 "Active" 00 "Inactive" ;
VAL_ 2554527880 P8_BalSwCell10 01 "Active" 00 "Inactive" ;
VAL_ 2554527880 P8_BalSwCell11 01 "Active" 00 "Inactive" ;
VAL_ 2554527880 P8_BalSwCell12 01 "Active" 00 "Inactive" ;
VAL_ 2554593416 P8_BalSwCell13 01 "Active" 00 "Inactive" ;
VAL_ 2554593416 P8_BalSwCell14 01 "Active" 00 "Inactive" ;
VAL_ 2554593416 P8_BalSwCell15 01 "Active" 00 "Inactive" ;
VAL_ 2554593416 P8_BalSwCell16 01 "Active" 00 "Inactive" ;
VAL_ 2554658952 P8_BalSwCell17 01 "Active" 00 "Inactive" ;
VAL_ 2554658952 P8_BalSwCell18 01 "Active" 00 "Inactive" ;
VAL_ 2554658952 P8_BalSwCell19 01 "Active" 00 "Inactive" ;
VAL_ 2554658952 P8_BalSwCell20 01 "Active" 00 "Inactive" ;
VAL_ 2554724488 P8_BalSwCell21 01 "Active" 00 "Inactive" ;
VAL_ 2554724488 P8_BalSwCell22 01 "Active" 00 "Inactive" ;
VAL_ 2554724488 P8_BalSwCell23 01 "Active" 00 "Inactive" ;
VAL_ 2554724488 P8_BalSwCell24 01 "Active" 00 "Inactive" ;
VAL_ 2554790024 P8_BalSwCell25 01 "Active" 00 "Inactive" ;
VAL_ 2554790024 P8_BalSwCell26 01 "Active" 00 "Inactive" ;
VAL_ 2554790024 P8_BalSwCell27 01 "Active" 00 "Inactive" ;
VAL_ 2554790024 P8_BalSwCell28 01 "Active" 00 "Inactive" ;
VAL_ 2554855560 P8_BalSwCell29 01 "Active" 00 "Inactive" ;
VAL_ 2554855560 P8_BalSwCell30 01 "Active" 00 "Inactive" ;
VAL_ 2554855560 P8_BalSwCell31 01 "Active" 00 "Inactive" ;
VAL_ 2554855560 P8_BalSwCell32 01 "Active" 00 "Inactive" ;
VAL_ 2554921096 P8_BalSwCell33 01 "Active" 00 "Inactive" ;
VAL_ 2554921096 P8_BalSwCell34 01 "Active" 00 "Inactive" ;
VAL_ 2554921096 P8_BalSwCell35 01 "Active" 00 "Inactive" ;
VAL_ 2554921096 P8_BalSwCell36 01 "Active" 00 "Inactive" ;
VAL_ 2554986632 P8_BalSwCell37 01 "Active" 00 "Inactive" ;
VAL_ 2554986632 P8_BalSwCell38 01 "Active" 00 "Inactive" ;
VAL_ 2554986632 P8_BalSwCell39 01 "Active" 00 "Inactive" ;
VAL_ 2554986632 P8_BalSwCell40 01 "Active" 00 "Inactive" ;
VAL_ 2555052168 P8_BalSwCell41 01 "Active" 00 "Inactive" ;
VAL_ 2555052168 P8_BalSwCell42 01 "Active" 00 "Inactive" ;
VAL_ 2555052168 P8_BalSwCell43 01 "Active" 00 "Inactive" ;
VAL_ 2555052168 P8_BalSwCell44 01 "Active" 00 "Inactive" ;
VAL_ 2555117704 P8_BalSwCell45 01 "Active" 00 "Inactive" ;
VAL_ 2555117704 P8_BalSwCell46 01 "Active" 00 "Inactive" ;
VAL_ 2555117704 P8_BalSwCell47 01 "Active" 00 "Inactive" ;
VAL_ 2555117704 P8_BalSwCell48 01 "Active" 00 "Inactive" ;
VAL_ 2555183240 P8_BalSwCell49 01 "Active" 00 "Inactive" ;
VAL_ 2555183240 P8_BalSwCell50 01 "Active" 00 "Inactive" ;
VAL_ 2555183240 P8_BalSwCell51 01 "Active" 00 "Inactive" ;
VAL_ 2555183240 P8_BalSwCell52 01 "Active" 00 "Inactive" ;
VAL_ 2555248776 P8_BalSwCell53 01 "Active" 00 "Inactive" ;
VAL_ 2555248776 P8_BalSwCell54 01 "Active" 00 "Inactive" ;
VAL_ 2555248776 P8_BalSwCell55 01 "Active" 00 "Inactive" ;
VAL_ 2555248776 P8_BalSwCell56 01 "Active" 00 "Inactive" ;
VAL_ 2555314312 P8_BalSwCell57 01 "Active" 00 "Inactive" ;
VAL_ 2555314312 P8_BalSwCell58 01 "Active" 00 "Inactive" ;
VAL_ 2555314312 P8_BalSwCell59 01 "Active" 00 "Inactive" ;
VAL_ 2555314312 P8_BalSwCell60 01 "Active" 00 "Inactive" ;
VAL_ 2555379848 P8_BalSwCell61 01 "Active" 00 "Inactive" ;
VAL_ 2555379848 P8_BalSwCell62 01 "Active" 00 "Inactive" ;
VAL_ 2555379848 P8_BalSwCell63 01 "Active" 00 "Inactive" ;
VAL_ 2555379848 P8_BalSwCell64 01 "Active" 00 "Inactive" ;
VAL_ 2555445384 P8_BalSwCell65 01 "Active" 00 "Inactive" ;
VAL_ 2555445384 P8_BalSwCell66 01 "Active" 00 "Inactive" ;
VAL_ 2555445384 P8_BalSwCell67 01 "Active" 00 "Inactive" ;
VAL_ 2555445384 P8_BalSwCell68 01 "Active" 00 "Inactive" ;
VAL_ 2555510920 P8_BalSwCell69 01 "Active" 00 "Inactive" ;
VAL_ 2555510920 P8_BalSwCell70 01 "Active" 00 "Inactive" ;
VAL_ 2555510920 P8_BalSwCell71 01 "Active" 00 "Inactive" ;
VAL_ 2555510920 P8_BalSwCell72 01 "Active" 00 "Inactive" ;
VAL_ 2555576456 P8_BalSwCell73 01 "Active" 00 "Inactive" ;
VAL_ 2555576456 P8_BalSwCell74 01 "Active" 00 "Inactive" ;
VAL_ 2555576456 P8_BalSwCell75 01 "Active" 00 "Inactive" ;
VAL_ 2555576456 P8_BalSwCell76 01 "Active" 00 "Inactive" ;
VAL_ 2555641992 P8_BalSwCell77 01 "Active" 00 "Inactive" ;
VAL_ 2555641992 P8_BalSwCell78 01 "Active" 00 "Inactive" ;
VAL_ 2555641992 P8_BalSwCell79 01 "Active" 00 "Inactive" ;
VAL_ 2555641992 P8_BalSwCell80 01 "Active" 00 "Inactive" ;
VAL_ 2555707528 P8_BalSwCell81 01 "Active" 00 "Inactive" ;
VAL_ 2555707528 P8_BalSwCell82 01 "Active" 00 "Inactive" ;
VAL_ 2555707528 P8_BalSwCell83 01 "Active" 00 "Inactive" ;
VAL_ 2555707528 P8_BalSwCell84 01 "Active" 00 "Inactive" ;
VAL_ 2555773064 P8_BalSwCell85 01 "Active" 00 "Inactive" ;
VAL_ 2555773064 P8_BalSwCell86 01 "Active" 00 "Inactive" ;
VAL_ 2555773064 P8_BalSwCell87 01 "Active" 00 "Inactive" ;
VAL_ 2555773064 P8_BalSwCell88 01 "Active" 00 "Inactive" ;
VAL_ 2555838600 P8_BalSwCell89 01 "Active" 00 "Inactive" ;
VAL_ 2555838600 P8_BalSwCell90 01 "Active" 00 "Inactive" ;
VAL_ 2555838600 P8_BalSwCell91 01 "Active" 00 "Inactive" ;
VAL_ 2555838600 P8_BalSwCell92 01 "Active" 00 "Inactive" ;
VAL_ 2555904136 P8_BalSwCell93 01 "Active" 00 "Inactive" ;
VAL_ 2555904136 P8_BalSwCell94 01 "Active" 00 "Inactive" ;
VAL_ 2555904136 P8_BalSwCell95 01 "Active" 00 "Inactive" ;
VAL_ 2555904136 P8_BalSwCell96 01 "Active" 00 "Inactive" ;
VAL_ 2555969672 P8_BalSwCell97 01 "Active" 00 "Inactive" ;
VAL_ 2555969672 P8_BalSwCell98 01 "Active" 00 "Inactive" ;
VAL_ 2555969672 P8_BalSwCell99 01 "Active" 00 "Inactive" ;
VAL_ 2555969672 P8_BalSwCell100 01 "Active" 00 "Inactive" ;
VAL_ 2556035208 P8_BalSwCell101 01 "Active" 00 "Inactive" ;
VAL_ 2556035208 P8_BalSwCell102 01 "Active" 00 "Inactive" ;
VAL_ 2556035208 P8_BalSwCell103 01 "Active" 00 "Inactive" ;
VAL_ 2556035208 P8_BalSwCell104 01 "Active" 00 "Inactive" ;
VAL_ 2556100744 P8_BalSwCell105 01 "Active" 00 "Inactive" ;
VAL_ 2556100744 P8_BalSwCell106 01 "Active" 00 "Inactive" ;
VAL_ 2556100744 P8_BalSwCell107 01 "Active" 00 "Inactive" ;
VAL_ 2556100744 P8_BalSwCell108 01 "Active" 00 "Inactive" ;
VAL_ 2556166280 P8_BalSwCell109 01 "Active" 00 "Inactive" ;
VAL_ 2556166280 P8_BalSwCell110 01 "Active" 00 "Inactive" ;
VAL_ 2556166280 P8_BalSwCell111 01 "Active" 00 "Inactive" ;
VAL_ 2556166280 P8_BalSwCell112 01 "Active" 00 "Inactive" ;
VAL_ 2556231816 P8_BalSwCell113 01 "Active" 00 "Inactive" ;
VAL_ 2556231816 P8_BalSwCell114 01 "Active" 00 "Inactive" ;
VAL_ 2556231816 P8_BalSwCell115 01 "Active" 00 "Inactive" ;
VAL_ 2556231816 P8_BalSwCell116 01 "Active" 00 "Inactive" ;
VAL_ 2556297352 P8_BalSwCell117 01 "Active" 00 "Inactive" ;
VAL_ 2556297352 P8_BalSwCell118 01 "Active" 00 "Inactive" ;
VAL_ 2556297352 P8_BalSwCell119 01 "Active" 00 "Inactive" ;
VAL_ 2556297352 P8_BalSwCell120 01 "Active" 00 "Inactive" ;
VAL_ 2556362888 P8_BalSwCell121 01 "Active" 00 "Inactive" ;
VAL_ 2556362888 P8_BalSwCell122 01 "Active" 00 "Inactive" ;
VAL_ 2556362888 P8_BalSwCell123 01 "Active" 00 "Inactive" ;
VAL_ 2556362888 P8_BalSwCell124 01 "Active" 00 "Inactive" ;
VAL_ 2556428424 P8_BalSwCell125 01 "Active" 00 "Inactive" ;
VAL_ 2556428424 P8_BalSwCell126 01 "Active" 00 "Inactive" ;
VAL_ 2556428424 P8_BalSwCell127 01 "Active" 00 "Inactive" ;
VAL_ 2556428424 P8_BalSwCell128 01 "Active" 00 "Inactive" ;
VAL_ 2556493960 P8_BalSwCell129 01 "Active" 00 "Inactive" ;
VAL_ 2556493960 P8_BalSwCell130 01 "Active" 00 "Inactive" ;
VAL_ 2556493960 P8_BalSwCell131 01 "Active" 00 "Inactive" ;
VAL_ 2556493960 P8_BalSwCell132 01 "Active" 00 "Inactive" ;
VAL_ 2556559496 P8_BalSwCell133 01 "Active" 00 "Inactive" ;
VAL_ 2556559496 P8_BalSwCell134 01 "Active" 00 "Inactive" ;
VAL_ 2556559496 P8_BalSwCell135 01 "Active" 00 "Inactive" ;
VAL_ 2556559496 P8_BalSwCell136 01 "Active" 00 "Inactive" ;
VAL_ 2556625032 P8_BalSwCell137 01 "Active" 00 "Inactive" ;
VAL_ 2556625032 P8_BalSwCell138 01 "Active" 00 "Inactive" ;
VAL_ 2556625032 P8_BalSwCell139 01 "Active" 00 "Inactive" ;
VAL_ 2556625032 P8_BalSwCell140 01 "Active" 00 "Inactive" ;
VAL_ 2556690568 P8_BalSwCell141 01 "Active" 00 "Inactive" ;
VAL_ 2556690568 P8_BalSwCell142 01 "Active" 00 "Inactive" ;
VAL_ 2556690568 P8_BalSwCell143 01 "Active" 00 "Inactive" ;
VAL_ 2556690568 P8_BalSwCell144 01 "Active" 00 "Inactive" ;
VAL_ 2556756104 P8_BalSwCell145 01 "Active" 00 "Inactive" ;
VAL_ 2556756104 P8_BalSwCell146 01 "Active" 00 "Inactive" ;
VAL_ 2556756104 P8_BalSwCell147 01 "Active" 00 "Inactive" ;
VAL_ 2556756104 P8_BalSwCell148 01 "Active" 00 "Inactive" ;
VAL_ 2556821640 P8_BalSwCell149 01 "Active" 00 "Inactive" ;
VAL_ 2556821640 P8_BalSwCell150 01 "Active" 00 "Inactive" ;
VAL_ 2556821640 P8_BalSwCell151 01 "Active" 00 "Inactive" ;
VAL_ 2556821640 P8_BalSwCell152 01 "Active" 00 "Inactive" ;
VAL_ 2556887176 P8_BalSwCell153 01 "Active" 00 "Inactive" ;
VAL_ 2556887176 P8_BalSwCell154 01 "Active" 00 "Inactive" ;
VAL_ 2556887176 P8_BalSwCell155 01 "Active" 00 "Inactive" ;
VAL_ 2556887176 P8_BalSwCell156 01 "Active" 00 "Inactive" ;
VAL_ 2556952712 P8_BalSwCell157 01 "Active" 00 "Inactive" ;
VAL_ 2556952712 P8_BalSwCell158 01 "Active" 00 "Inactive" ;
VAL_ 2556952712 P8_BalSwCell159 01 "Active" 00 "Inactive" ;
VAL_ 2556952712 P8_BalSwCell160 01 "Active" 00 "Inactive" ;
VAL_ 2557018248 P8_BalSwCell161 01 "Active" 00 "Inactive" ;
VAL_ 2557018248 P8_BalSwCell162 01 "Active" 00 "Inactive" ;
VAL_ 2557018248 P8_BalSwCell163 01 "Active" 00 "Inactive" ;
VAL_ 2557018248 P8_BalSwCell164 01 "Active" 00 "Inactive" ;
VAL_ 2557083784 P8_BalSwCell165 01 "Active" 00 "Inactive" ;
VAL_ 2557083784 P8_BalSwCell166 01 "Active" 00 "Inactive" ;
VAL_ 2557083784 P8_BalSwCell167 01 "Active" 00 "Inactive" ;
VAL_ 2557083784 P8_BalSwCell168 01 "Active" 00 "Inactive" ;
VAL_ 2557149320 P8_BalSwCell169 01 "Active" 00 "Inactive" ;
VAL_ 2557149320 P8_BalSwCell170 01 "Active" 00 "Inactive" ;
VAL_ 2557149320 P8_BalSwCell171 01 "Active" 00 "Inactive" ;
VAL_ 2557149320 P8_BalSwCell172 01 "Active" 00 "Inactive" ;
VAL_ 2557214856 P8_BalSwCell173 01 "Active" 00 "Inactive" ;
VAL_ 2557214856 P8_BalSwCell174 01 "Active" 00 "Inactive" ;
VAL_ 2557214856 P8_BalSwCell175 01 "Active" 00 "Inactive" ;
VAL_ 2557214856 P8_BalSwCell176 01 "Active" 00 "Inactive" ;
VAL_ 2557280392 P8_BalSwCell177 01 "Active" 00 "Inactive" ;
VAL_ 2557280392 P8_BalSwCell178 01 "Active" 00 "Inactive" ;
VAL_ 2557280392 P8_BalSwCell179 01 "Active" 00 "Inactive" ;
VAL_ 2557280392 P8_BalSwCell180 01 "Active" 00 "Inactive" ;
VAL_ 2557345928 P8_BalSwCell181 01 "Active" 00 "Inactive" ;
VAL_ 2557345928 P8_BalSwCell182 01 "Active" 00 "Inactive" ;
VAL_ 2557345928 P8_BalSwCell183 01 "Active" 00 "Inactive" ;
VAL_ 2557345928 P8_BalSwCell184 01 "Active" 00 "Inactive" ;
VAL_ 2557411464 P8_BalSwCell185 01 "Active" 00 "Inactive" ;
VAL_ 2557411464 P8_BalSwCell186 01 "Active" 00 "Inactive" ;
VAL_ 2557411464 P8_BalSwCell187 01 "Active" 00 "Inactive" ;
VAL_ 2557411464 P8_BalSwCell188 01 "Active" 00 "Inactive" ;
VAL_ 2557477000 P8_BalSwCell189 01 "Active" 00 "Inactive" ;
VAL_ 2557477000 P8_BalSwCell190 01 "Active" 00 "Inactive" ;
VAL_ 2557477000 P8_BalSwCell191 01 "Active" 00 "Inactive" ;
VAL_ 2557477000 P8_BalSwCell192 01 "Active" 00 "Inactive" ;
VAL_ 2550399129 P9_BMSKL15ON 01 "On" 00 "Off" ;
VAL_ 2550530201 P9_PackDschrgPwrStat 02 "鎸佺画鏀剧數鍔熺巼" 01 "30s鏀剧數鍔熺巼" 00 "10s鏀剧數鍔熺巼" ;
VAL_ 2550530201 P9_PackChrgPwrStat 02 "鎸佺画鍏呯數鍔熺巼" 01 "30s鍏呯數鍔熺巼" 00 "10s鍏呯數鍔熺巼" ;
